VERSION "created by canmatrix"

NS_ :

BS_:

BU_: MD1_ECM ETC NODE_5 BSM_EBS RM_IRCS IC_Multic SGW BCM_NBM VCM NODE_31 ETS NODE_45 FCCU DICO NODE_72 FMReceiver SGW2 VCU ADCU MRGEN DTCO MBMS TPMS AI_CAID ELC ELC_R NODE_F7 BMS3 TUROLLA PCM SRR_Front_Left SRR_Rear_Right SRR_Front_Right SRR_Front SRR_Rear_Left ELFA3_S THERMOKING_M TMU_HP_Rr NODE_B1 NODE_B2 NODE_B3 NODE_B4 NODE_B5 NODE_B6 NODE_B7 NODE_B8 BMS2 NODE_B9 NODE_BA NODE_FC NODE_BB NODE_BC NODE_BE NODE_BD NODE_BF ACU NODE_C0 BMS1 NODE_C1 FCU NODE_C3 NODE_C4 NODE_EC NODE_C5 NODE_C6 NODE_C7 NODE_C8 VCU2 NODE_CA NODE_CB NODE_CD NODE_CE NODE_CF NODE_ED ST_ScanTool MASTER68_STD1 NODE_D1 NODE_F2 NODE_FD NODE_D2 MCSL NODE_EB NODE_D3 NODE_D4 NODE_D5 NODE_D6 VCCU NODE_D8 NODE_D9 NODE_F9 DiagTool NODE_DA NODE_DB NODE_DC NODE_DD NODE_DE NODE_DF NODE_E0 NODE_E1 NODE_E2 NODE_E9 NODE_E3 SAS NODE_FB NODE_F8 NODE_E6 ELFA3 NODE_F THERMOKING_D FMS MULTIC_S MULTIC_2 BMS4 BMS5 BMS6 BMS7 BMS8 BMS9 BMS10 BMS11 NODE_71

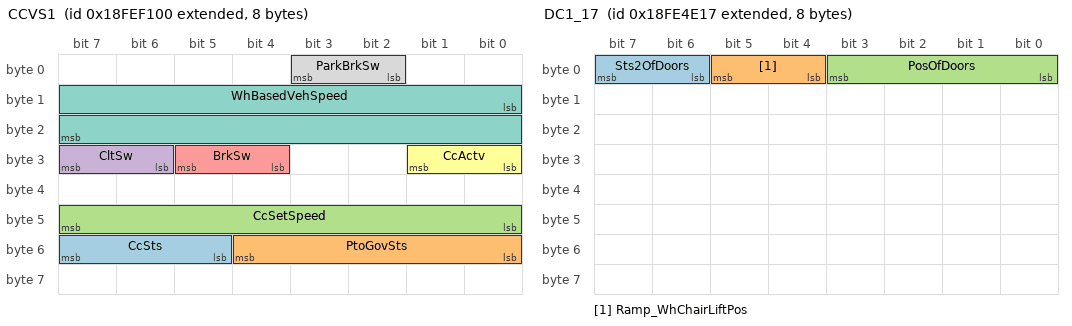
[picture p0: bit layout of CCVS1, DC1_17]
BO_ 2566844672 CCVS1: 8 MD1_ECM
 SG_ CcSts : 53|3@1+ (1,0) [0|7] ""  PCM
 SG_ PtoGovSts : 48|5@1+ (1,0) [0|31] ""  PCM
 SG_ CcSetSpeed : 40|8@1+ (1,0) [0|250] "km/h"  PCM
 SG_ CltSw : 30|2@1+ (1,0) [0|3] ""  PCM
 SG_ BrkSw : 28|2@1+ (1,0) [0|3] ""  PCM
 SG_ CcActv : 24|2@1+ (1,0) [0|3] ""  PCM
 SG_ WhBasedVehSpeed : 8|16@1+ (0.00390625,0) [0|250.996] "km/h"  PCM
 SG_ ParkBrkSw : 2|2@1+ (1,0) [0|3] ""  PCM

BO_ 2566890313 ChargerFaults: 8 FCCU
 SG_ BefLastStopCause : 32|8@1+ (1,0) [0|250] ""  PCM
 SG_ LastStopCause : 24|8@1+ (1,0) [0|250] ""  PCM

BO_ 2566843165 CI_1D: 609 SGW
 SG_ UnitNumPwrUnit : 24|8@1+ (1,0) [0|255] "ASCII"  PCM
 SG_ Sn : 16|8@1+ (1,0) [0|255] "ASCII"  PCM
 SG_ Model : 8|8@1+ (1,0) [0|255] "ASCII"  PCM
 SG_ Make : 0|8@1+ (1,0) [0|255] "ASCII"  PCM

BO_ 2566843230 CI_5E: 609 AI_CAID
 SG_ Model_FEEB5E : 8|8@1+ (1,0) [0|255] "ASCII"  PCM

BO_ 2566865139 CLIM_LTO_STATUS: 8 MBMS
 SG_ CoolSts : 4|4@1+ (1,0) [0|7] ""  PCM

BO_ 2566811659 CVW_0B: 8 BSM_EBS
 SG_ Gcvw : 16|16@1+ (10,0) [0|642550] "kg"  PCM

BO_ 2566802967 DC1_17: 8 IC_Multic
 SG_ Sts2OfDoors : 6|2@1+ (1,0) [0|3] ""  PCM
 SG_ Ramp_WhChairLiftPos : 4|2@1+ (1,0) [0|3] ""  PCM
 SG_ PosOfDoors : 0|4@1+ (1,0) [0|15] ""  PCM

BO_ 2566759703 DC2_17: 8 IC_Multic
 SG_ EnaStsOfDoor10 : 58|2@1+ (1,0) [0|3] ""  PCM
 SG_ OpenStsOfDoor10 : 56|2@1+ (1,0) [0|3] ""  PCM
 SG_ LckStsOfDoor10 : 54|2@1+ (1,0) [0|3] ""  PCM
 SG_ EnaStsOfDoor9 : 52|2@1+ (1,0) [0|3] ""  PCM
 SG_ OpenStsOfDoor9 : 50|2@1+ (1,0) [0|3] ""  PCM
 SG_ LckStsOfDoor9 : 48|2@1+ (1,0) [0|3] ""  PCM
 SG_ EnaStsOfDoor8 : 46|2@1+ (1,0) [0|3] ""  PCM
 SG_ OpenStsOfDoor8 : 44|2@1+ (1,0) [0|3] ""  PCM
 SG_ LckStsOfDoor8 : 42|2@1+ (1,0) [0|3] ""  PCM
 SG_ EnaStsOfDoor7 : 40|2@1+ (1,0) [0|3] ""  PCM
 SG_ OpenStsOfDoor7 : 38|2@1+ (1,0) [0|3] ""  PCM
 SG_ LckStsOfDoor7 : 36|2@1+ (1,0) [0|3] ""  PCM
 SG_ EnaStsOfDoor6 : 34|2@1+ (1,0) [0|3] ""  PCM
 SG_ OpenStsOfDoor6 : 32|2@1+ (1,0) [0|3] ""  PCM
 SG_ LckStsOfDoor6 : 30|2@1+ (1,0) [0|3] ""  PCM
 SG_ EnaStsOfDoor5 : 28|2@1+ (1,0) [0|3] ""  PCM
 SG_ OpenStsOfDoor5 : 26|2@1+ (1,0) [0|3] ""  PCM
 SG_ LckStsOfDoor5 : 24|2@1+ (1,0) [0|3] ""  PCM
 SG_ EnaStsOfDoor4 : 22|2@1+ (1,0) [0|3] ""  PCM
 SG_ OpenStsOfDoor4 : 20|2@1+ (1,0) [0|3] ""  PCM
 SG_ LckStsOfDoor4 : 18|2@1+ (1,0) [0|3] ""  PCM
 SG_ EnaStsOfDoor3 : 16|2@1+ (1,0) [0|3] ""  PCM
 SG_ OpenStsOfDoor3 : 14|2@1+ (1,0) [0|3] ""  PCM
 SG_ LckStsOfDoor3 : 12|2@1+ (1,0) [0|3] ""  PCM
 SG_ EnaStsOfDoor2 : 10|2@1+ (1,0) [0|3] ""  PCM
 SG_ OpenStsOfDoor2 : 8|2@1+ (1,0) [0|3] ""  PCM
 SG_ LckStsOfDoor2 : 6|2@1+ (1,0) [0|3] ""  PCM
 SG_ EnaStsOfDoor1 : 4|2@1+ (1,0) [0|3] ""  PCM
 SG_ OpenStsOfDoor1 : 2|2@1+ (1,0) [0|3] ""  PCM
 SG_ LckStsOfDoor1 : 0|2@1+ (1,0) [0|3] ""  PCM

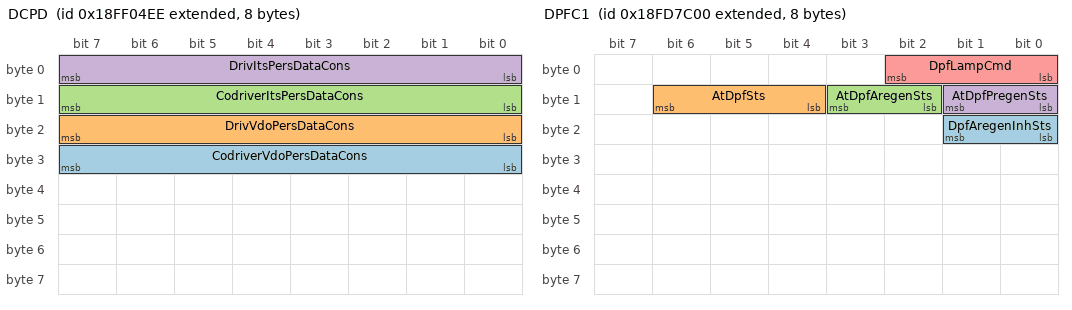
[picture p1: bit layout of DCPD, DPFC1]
BO_ 2566849774 DCPD: 8 DTCO
 SG_ CodriverVdoPersDataCons : 24|8@1+ (1,0) [0|250] ""  PCM
 SG_ DrivVdoPersDataCons : 16|8@1+ (1,0) [0|250] ""  PCM
 SG_ CodriverItsPersDataCons : 8|8@1+ (1,0) [0|250] ""  PCM
 SG_ DrivItsPersDataCons : 0|8@1+ (1,0) [0|250] ""  PCM

BO_ 2566847521 DD1_21: 8 BCM_NBM
 SG_ FuelLev1 : 8|8@1+ (0.4,0) [0|100] "%"  PCM

BO_ 2566810606 DI_EE: 40 DTCO
 SG_ Driv2Id : 8|8@1+ (1,0) [0|255] "ASCII"  PCM
 SG_ Driv1Id : 0|8@1+ (1,0) [0|255] "ASCII"  PCM

BO_ 2566834688 DM01_00: 82 MD1_ECM
 SG_ SpnCm20 : 655|1@1+ (1,0) [0|1] ""  PCM

BO_ 2566834691 DM01_03: 42 ETC
 SG_ SpnCm10 : 335|1@1+ (1,0) [0|1] ""  PCM

BO_ 2566834699 DM01_0B: 42 BSM_EBS
 SG_ SpnCm10_FECA0B : 335|1@1+ (1,0) [0|1] ""  PCM

BO_ 2566834704 DM01_10: 42 RM_IRCS
 SG_ SpnCm10_FECA10 : 335|1@1+ (1,0) [0|1] ""  PCM

BO_ 2566834711 DM01_17: 82 IC_Multic
 SG_ SpnCm20_FECA17 : 655|1@1+ (1,0) [0|1] ""  PCM

BO_ 2566834716 DM01_1C: 42 PCM
 SG_ SpnCm10_FECA1C : 335|1@1+ (1,0) [0|1] "" Vector__XXX

BO_ 2566834717 DM01_1D: 42 SGW
 SG_ SpnCm10_FECA1D : 335|1@1+ (1,0) [0|1] ""  PCM

BO_ 2566834721 DM01_21: 42 BCM_NBM
 SG_ SpnCm10_FECA21 : 335|1@1+ (1,0) [0|1] ""  PCM

BO_ 2566834727 DM01_27: 42 VCM
 SG_ SpnCm10_FECA27 : 335|1@1+ (1,0) [0|1] ""  PCM

BO_ 2566834734 DM01_2E: 42 TUROLLA
 SG_ SpnCm10_FECA2E : 335|1@1+ (1,0) [0|1] ""  PCM

BO_ 2566834735 DM01_2F: 42 ELC
 SG_ SpnCm10_FECA2F : 335|1@1+ (1,0) [0|1] ""  PCM

BO_ 2566834739 DM01_33: 42 TPMS
 SG_ SpnCm10_FECA33 : 335|1@1+ (1,0) [0|1] ""  PCM

BO_ 2566834744 DM01_38: 42 ETS
 SG_ SpnCm10_FECA38 : 335|1@1+ (1,0) [0|1] ""  PCM

BO_ 2566834752 DM01_40: 42 ELC_R
 SG_ SpnCm10_FECA40 : 335|1@1+ (1,0) [0|1] ""  PCM

BO_ 2566834761 DM01_49: 42 FCCU
 SG_ SpnCm10_FECA49 : 335|1@1+ (1,0) [0|1] ""  PCM

BO_ 2566834762 DM01_4A: 42 PCM
 SG_ SpnCm10_FECA4A : 335|1@1+ (1,0) [0|1] "" Vector__XXX

BO_ 2566834778 DM01_5A: 42 DICO
 SG_ SpnCm10_FECA5A : 335|1@1+ (1,0) [0|1] ""  PCM

BO_ 2566834782 DM01_5E: 42 AI_CAID
 SG_ SpnCm10_FECA5E : 335|1@1+ (1,0) [0|1] ""  PCM

BO_ 2566834814 DM01_7E: 42 SGW2
 SG_ SpnCm10_FECA7E : 335|1@1+ (1,0) [0|1] ""  PCM

BO_ 2566834832 DM01_90: 42 SRR_Front_Left
 SG_ SpnCm10_FECA90 : 335|1@1+ (1,0) [0|1] ""  PCM

BO_ 2566834833 DM01_91: 42 SRR_Rear_Right
 SG_ SpnCm10_FECA91 : 335|1@1+ (1,0) [0|1] ""  PCM

BO_ 2566834834 DM01_92: 42 SRR_Front_Right
 SG_ SpnCm10_FECA92 : 335|1@1+ (1,0) [0|1] ""  PCM

BO_ 2566834844 DM01_9C: 42 SRR_Front
 SG_ SpnCm10_FECA9C : 335|1@1+ (1,0) [0|1] ""  PCM

BO_ 2566834846 DM01_9E: 42 ADCU
 SG_ SpnCm10_FECA9E : 335|1@1+ (1,0) [0|1] ""  PCM

BO_ 2566834848 DM01_A0: 42 MRGEN
 SG_ SpnCm10_FECAA0 : 335|1@1+ (1,0) [0|1] ""  PCM

BO_ 2566834920 DM01_E8: 42 SRR_Rear_Left
 SG_ SpnCm10_FECAE8 : 335|1@1+ (1,0) [0|1] ""  PCM

BO_ 2566834926 DM01_EE: 42 DTCO
 SG_ SpnCm10_FECAEE : 335|1@1+ (1,0) [0|1] ""  PCM

BO_ 2566834928 DM01_F0: 42 ELFA3_S
 SG_ SpnCm10_FECAF0 : 335|1@1+ (1,0) [0|1] ""  PCM

BO_ 2566834931 DM01_F3: 42 MBMS
 SG_ SpnCm10_FECAF3 : 335|1@1+ (1,0) [0|1] ""  PCM

BO_ 2566834972 DM02_1C: 42 PCM
 SG_ SpnCm10_FECB1C : 335|1@1+ (1,0) [0|1] "" Vector__XXX

BO_ 2566834973 DM02_1D: 42 SGW
 SG_ SpnCm10_FECB1D : 335|1@1+ (1,0) [0|1] ""  PCM

BO_ 2566835102 DM02_9E: 42 ADCU
 SG_ SpnCm10_FECB9E : 335|1@1+ (1,0) [0|1] ""  PCM

BO_ 2566835485 DM04_1D: 250 SGW
 SG_ HrTotVehDist_10 : 1968|32@1+ (5,0) [0|21055406075] "m"  PCM

BO_ 2566835614 DM04_9E: 250 ADCU
 SG_ HrTotVehDist_10_FECD9E : 1968|32@1+ (5,0) [0|21055406075] "m"  PCM

BO_ 2633943577 DM1_19_P7: 42 THERMOKING_M
 SG_ SpnCm10_FECA19 : 335|1@1+ (1,0) [0|1] ""  PCM

BO_ 2633943610 DM1_3A_P7: 42 TMU_HP_Rr
 SG_ SpnCm10_FECA3A : 335|1@1+ (1,0) [0|1] ""  PCM

BO_ 2633943680 DM1_80_P7: 42 VCU
 SG_ SpnCm10_FECA80 : 335|1@1+ (1,0) [0|1] ""  PCM

BO_ 2566856773 DoorsStat: 8 NODE_45
 SG_ DoorClosTime4 m4 : 32|8@1+ (100,0) [0|20000] "ms"  PCM
 SG_ DoorClosTime3 m3 : 32|8@1+ (100,0) [0|20000] "ms"  PCM
 SG_ DoorClosTime2 m2 : 32|8@1+ (100,0) [0|20000] "ms"  PCM
 SG_ DoorClosTime1 m1 : 32|8@1+ (100,0) [0|20000] "ms"  PCM
 SG_ DoorClosTime0 m0 : 32|8@1+ (100,0) [0|20000] "ms"  PCM
 SG_ DoorCnt4 m4 : 8|24@1+ (1,0) [0|6291455] "Cy"  PCM
 SG_ DoorCnt3 m3 : 8|24@1+ (1,0) [0|6291455] "Cy"  PCM
 SG_ DoorCnt2 m2 : 8|24@1+ (1,0) [0|6291455] "Cy"  PCM
 SG_ DoorCnt1 m1 : 8|24@1+ (1,0) [0|6291455] "Cy"  PCM
 SG_ DoorCnt0 m0 : 8|24@1+ (1,0) [0|6291455] "Cy"  PCM
 SG_ DoorId M : 0|8@1+ (1,0) [0|7] ""  PCM

BO_ 2566749184 DPFC1: 8 MD1_ECM
 SG_ DpfAregenInhSts : 16|2@1+ (1,0) [0|3] ""  PCM
 SG_ AtDpfSts : 12|3@1+ (1,0) [0|7] ""  PCM
 SG_ AtDpfAregenSts : 10|2@1+ (1,0) [0|3] ""  PCM
 SG_ AtDpfPregenSts : 8|2@1+ (1,0) [0|3] ""  PCM
 SG_ DpfLampCmd : 0|3@1+ (1,0) [0|7] ""  PCM

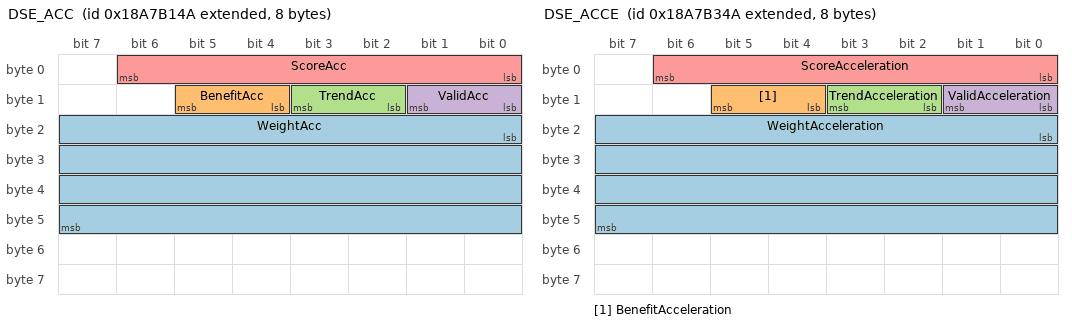
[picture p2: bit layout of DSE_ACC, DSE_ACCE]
BO_ 2561126730 DSE_ACC: 8 PCM
 SG_ WeightAcc : 16|32@1+ (1,-1) [-1|4294967294] ""  NODE_B1
 SG_ BenefitAcc : 12|2@1+ (1,0) [0|3] ""  NODE_B1
 SG_ TrendAcc : 10|2@1+ (1,-1) [-1|2] ""  NODE_B1
 SG_ ValidAcc : 8|2@1+ (1,0) [0|3] ""  NODE_B1
 SG_ ScoreAcc : 0|7@1+ (1,-1) [-1|126] ""  NODE_B1

BO_ 2561126986 DSE_ACC_DBG: 8 PCM
 SG_ EventAcc : 16|2@1+ (1,0) [0|3] ""  NODE_B2
 SG_ EvaluatedSamplesAcc : 0|16@1+ (1,-1) [-1|65534] ""  NODE_B2

BO_ 2561127242 DSE_ACCE: 8 PCM
 SG_ WeightAcceleration : 16|32@1+ (1,-1) [-1|4294967294] ""  NODE_B3
 SG_ BenefitAcceleration : 12|2@1+ (1,0) [0|3] ""  NODE_B3
 SG_ TrendAcceleration : 10|2@1+ (1,-1) [-1|2] ""  NODE_B3
 SG_ ValidAcceleration : 8|2@1+ (1,0) [0|3] ""  NODE_B3
 SG_ ScoreAcceleration : 0|7@1+ (1,-1) [-1|126] ""  NODE_B3

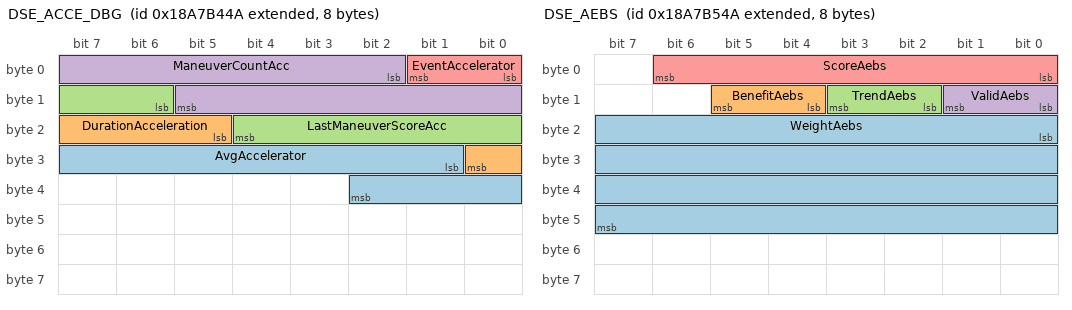
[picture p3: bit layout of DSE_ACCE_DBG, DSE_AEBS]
BO_ 2561127498 DSE_ACCE_DBG: 8 PCM
 SG_ AvgAccelerator : 25|10@1+ (0.1,-1) [-1|101.3] "%"  NODE_B4
 SG_ DurationAcceleration : 21|4@1+ (1,-1) [-1|14] "s"  NODE_B4
 SG_ LastManeuverScoreAcc : 14|7@1+ (1,-1) [-1|126] "Index"  NODE_B4
 SG_ ManeuverCountAcc : 2|12@1+ (1,-1) [-1|4094] "Count"  NODE_B4
 SG_ EventAccelerator : 0|2@1+ (1,0) [0|3] ""  NODE_B4

BO_ 2561127754 DSE_AEBS: 8 PCM
 SG_ WeightAebs : 16|32@1+ (1,-1) [-1|4294967294] ""  NODE_B5
 SG_ BenefitAebs : 12|2@1+ (1,0) [0|3] ""  NODE_B5
 SG_ TrendAebs : 10|2@1+ (1,-1) [-1|2] ""  NODE_B5
 SG_ ValidAebs : 8|2@1+ (1,0) [0|3] ""  NODE_B5
 SG_ ScoreAebs : 0|7@1+ (1,-1) [-1|126] ""  NODE_B5

BO_ 2561128010 DSE_AEBS_DBG: 8 PCM
 SG_ EventAebs : 16|2@1+ (1,0) [0|3] ""  NODE_B6
 SG_ EvaluatedSamplesAebs : 0|16@1+ (1,-1) [-1|65534] ""  NODE_B6

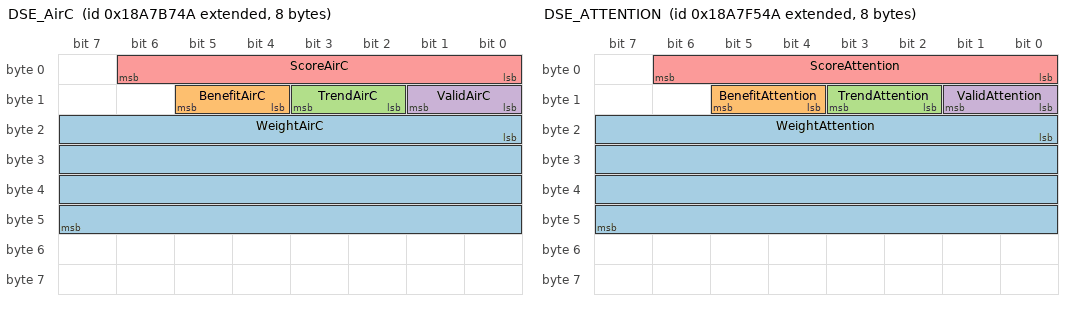
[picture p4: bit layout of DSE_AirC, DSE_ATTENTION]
BO_ 2561128266 DSE_AirC: 8 PCM
 SG_ WeightAirC : 16|32@1+ (1,-1) [-1|4294967294] ""  NODE_B7
 SG_ BenefitAirC : 12|2@1+ (1,0) [0|3] ""  NODE_B7
 SG_ TrendAirC : 10|2@1+ (1,-1) [-1|2] ""  NODE_B7
 SG_ ValidAirC : 8|2@1+ (1,0) [0|3] ""  NODE_B7
 SG_ ScoreAirC : 0|7@1+ (1,-1) [-1|126] ""  NODE_B7

BO_ 2561128522 DSE_AirC_DBG: 8 PCM
 SG_ EvaluatedSamplesAirC : 0|16@1+ (1,-1) [-1|65534] ""  NODE_B8

BO_ 2561144138 DSE_ATTENTION: 8 PCM
 SG_ WeightAttention : 16|32@1+ (1,-1) [-1|4294967294] ""  BMS2
 SG_ BenefitAttention : 12|2@1+ (1,0) [0|3] ""  BMS2
 SG_ TrendAttention : 10|2@1+ (1,-1) [-1|2] ""  BMS2
 SG_ ValidAttention : 8|2@1+ (1,0) [0|3] ""  BMS2
 SG_ ScoreAttention : 0|7@1+ (1,-1) [-1|126] ""  BMS2

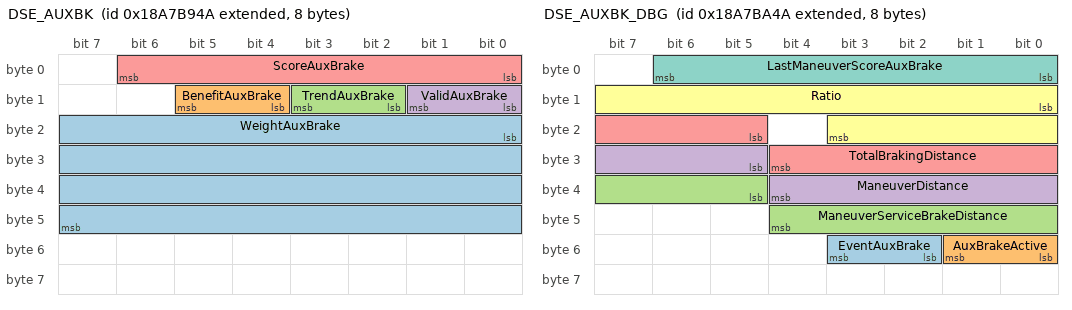
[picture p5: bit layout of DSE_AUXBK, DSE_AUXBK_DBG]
BO_ 2561128778 DSE_AUXBK: 8 PCM
 SG_ WeightAuxBrake : 16|32@1+ (1,-1) [-1|4294967294] ""  NODE_B9
 SG_ BenefitAuxBrake : 12|2@1+ (1,0) [0|3] ""  NODE_B9
 SG_ TrendAuxBrake : 10|2@1+ (1,-1) [-1|2] ""  NODE_B9
 SG_ ValidAuxBrake : 8|2@1+ (1,0) [0|3] ""  NODE_B9
 SG_ ScoreAuxBrake : 0|7@1+ (1,-1) [-1|126] ""  NODE_B9

BO_ 2561129034 DSE_AUXBK_DBG: 8 PCM
 SG_ EventAuxBrake : 50|2@1+ (1,0) [0|3] ""  NODE_BA
 SG_ AuxBrakeActive : 48|2@1+ (1,0) [0|3] ""  NODE_BA
 SG_ ManeuverServiceBrakeDistance : 37|8@1+ (1,0) [0|254] "m"  NODE_BA
 SG_ ManeuverDistance : 29|8@1+ (1,-1) [-1|254] "m"  NODE_BA
 SG_ TotalBrakingDistance : 21|8@1+ (1,-1) [-1|254] "m"  NODE_BA
 SG_ Ratio : 8|12@1+ (0.1,-1) [-1|408.5] ""  NODE_BA
 SG_ LastManeuverScoreAuxBrake : 0|7@1+ (1,-1) [-1|126] "Index"  NODE_BA

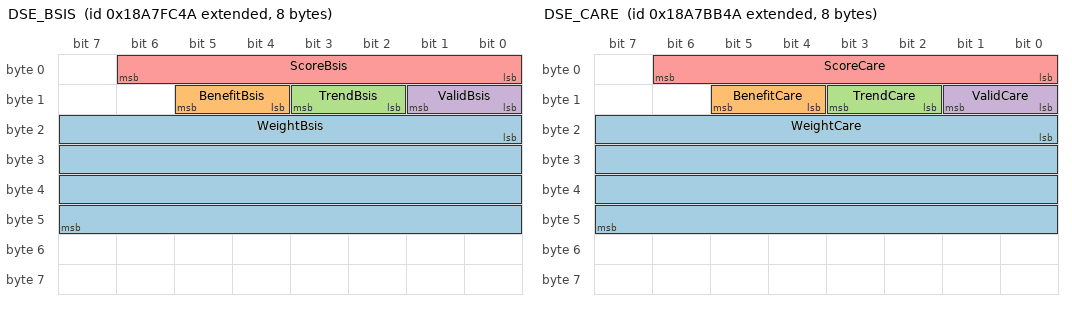
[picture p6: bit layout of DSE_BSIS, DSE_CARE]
BO_ 2561145930 DSE_BSIS: 8 PCM
 SG_ WeightBsis : 16|32@1+ (1,-1) [-1|4294967294] ""  NODE_FC
 SG_ BenefitBsis : 12|2@1+ (1,0) [0|3] ""  NODE_FC
 SG_ TrendBsis : 10|2@1+ (1,-1) [-1|2] ""  NODE_FC
 SG_ ValidBsis : 8|2@1+ (1,0) [0|3] ""  NODE_FC
 SG_ ScoreBsis : 0|7@1+ (1,-1) [-1|126] ""  NODE_FC

BO_ 2561129290 DSE_CARE: 8 PCM
 SG_ WeightCare : 16|32@1+ (1,-1) [-1|4294967294] ""  NODE_BB
 SG_ BenefitCare : 12|2@1+ (1,0) [0|3] ""  NODE_BB
 SG_ TrendCare : 10|2@1+ (1,-1) [-1|2] ""  NODE_BB
 SG_ ValidCare : 8|2@1+ (1,0) [0|3] ""  NODE_BB
 SG_ ScoreCare : 0|7@1+ (1,-1) [-1|126] "Index"  NODE_BB

BO_ 2561129546 DSE_CMD: 8 PCM
 SG_ ResetEcoB : 2|2@1+ (1,0) [0|3] ""  NODE_BC
 SG_ ResetEcoA : 0|2@1+ (1,0) [0|3] ""  NODE_BC

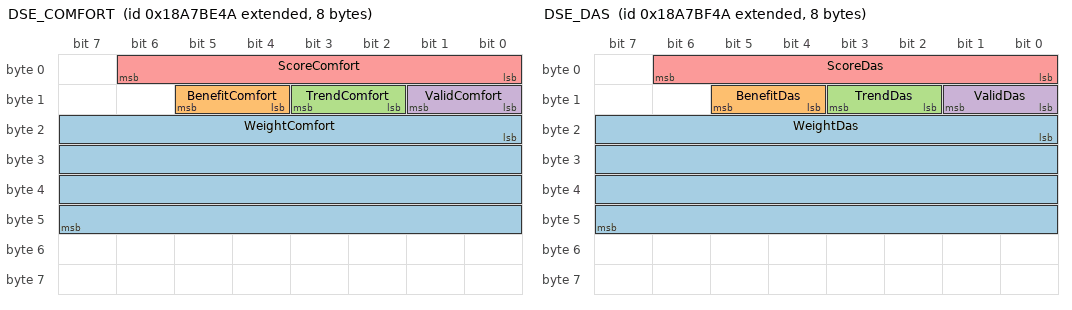
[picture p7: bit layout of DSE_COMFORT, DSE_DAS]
BO_ 2561130058 DSE_COMFORT: 8 PCM
 SG_ WeightComfort : 16|32@1+ (1,-1) [-1|4294967294] ""  NODE_BE
 SG_ BenefitComfort : 12|2@1+ (1,0) [0|3] ""  NODE_BE
 SG_ TrendComfort : 10|2@1+ (1,-1) [-1|2] ""  NODE_BE
 SG_ ValidComfort : 8|2@1+ (1,0) [0|3] ""  NODE_BE
 SG_ ScoreComfort : 0|7@1+ (1,0) [0|100] "%"  NODE_BE

BO_ 2561129802 DSE_CURNT: 8 PCM
 SG_ TimeStampCurrent : 32|32@1+ (1,946684800) [946684800|5241652095] "Date"  NODE_BD
 SG_ OdometerTripCurrent : 0|32@1+ (5,-1) [-1|21474836474] "m"  NODE_BD

BO_ 2561130314 DSE_DAS: 8 PCM
 SG_ WeightDas : 16|32@1+ (1,-1) [-1|4294967294] ""  NODE_BF
 SG_ BenefitDas : 12|2@1+ (1,0) [0|3] ""  NODE_BF
 SG_ TrendDas : 10|2@1+ (1,-1) [-1|2] ""  NODE_BF
 SG_ ValidDas : 8|2@1+ (1,0) [0|3] ""  NODE_BF
 SG_ ScoreDas : 0|7@1+ (1,-1) [-1|126] "Index"  NODE_BF

BO_ 2561140554 DSE_DAS_DBG: 8 PCM
 SG_ EventDas : 16|2@1+ (1,0) [0|3] ""  ACU
 SG_ EvaluatedSamplesDas : 0|16@1+ (1,-1) [-1|65534] ""  ACU

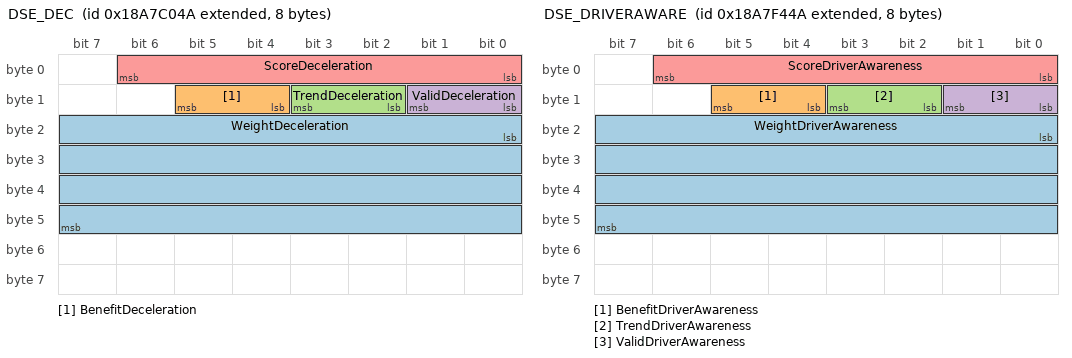
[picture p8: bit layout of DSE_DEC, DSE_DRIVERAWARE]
BO_ 2561130570 DSE_DEC: 8 PCM
 SG_ WeightDeceleration : 16|32@1+ (1,-1) [-1|4294967294] ""  NODE_C0
 SG_ BenefitDeceleration : 12|2@1+ (1,0) [0|3] ""  NODE_C0
 SG_ TrendDeceleration : 10|2@1+ (1,-1) [-1|2] ""  NODE_C0
 SG_ ValidDeceleration : 8|2@1+ (1,0) [0|3] ""  NODE_C0
 SG_ ScoreDeceleration : 0|7@1+ (1,-1) [-1|126] "Index"  NODE_C0

BO_ 2561143882 DSE_DRIVERAWARE: 8 PCM
 SG_ WeightDriverAwareness : 16|32@1+ (1,-1) [-1|4294967294] ""  BMS1
 SG_ BenefitDriverAwareness : 12|2@1+ (1,0) [0|3] ""  BMS1
 SG_ TrendDriverAwareness : 10|2@1+ (1,-1) [-1|2] ""  BMS1
 SG_ ValidDriverAwareness : 8|2@1+ (1,0) [0|3] ""  BMS1
 SG_ ScoreDriverAwareness : 0|7@1+ (1,-1) [-1|126] "Index"  BMS1

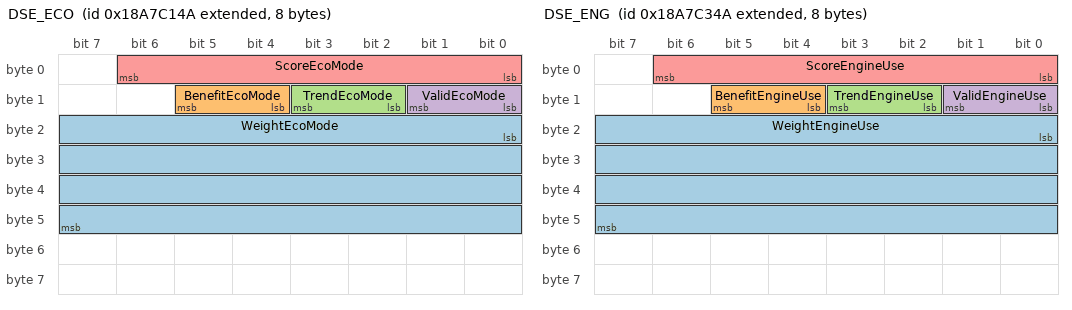
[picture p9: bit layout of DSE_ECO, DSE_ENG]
BO_ 2561130826 DSE_ECO: 8 PCM
 SG_ WeightEcoMode : 16|32@1+ (1,-1) [-1|4294967294] ""  NODE_C1
 SG_ BenefitEcoMode : 12|2@1+ (1,0) [0|3] ""  NODE_C1
 SG_ TrendEcoMode : 10|2@1+ (1,-1) [-1|2] ""  NODE_C1
 SG_ ValidEcoMode : 8|2@1+ (1,0) [0|3] ""  NODE_C1
 SG_ ScoreEcoMode : 0|7@1+ (1,-1) [-1|126] "Index"  NODE_C1

BO_ 2561131082 DSE_ECO_DBG: 8 PCM
 SG_ EvaluatedSamplesEcoMode : 0|16@1+ (1,-1) [-1|65534] ""  FCU

BO_ 2561131338 DSE_ENG: 8 PCM
 SG_ WeightEngineUse : 16|32@1+ (1,-1) [-1|4294967294] ""  NODE_C3
 SG_ BenefitEngineUse : 12|2@1+ (1,0) [0|3] ""  NODE_C3
 SG_ TrendEngineUse : 10|2@1+ (1,-1) [-1|2] ""  NODE_C3
 SG_ ValidEngineUse : 8|2@1+ (1,0) [0|3] ""  NODE_C3
 SG_ ScoreEngineUse : 0|7@1+ (1,-1) [-1|126] "Index"  NODE_C3

BO_ 2561140810 DSE_EVAL: 8 PCM
 SG_ EvaluatedSamplesTrip : 32|32@1+ (1,-1) [-1|4294967294] ""  SRR_Rear_Left
 SG_ EvaluatedMetersTrip : 0|32@1+ (1,-1) [-1|4294967294] "m"  SRR_Rear_Left

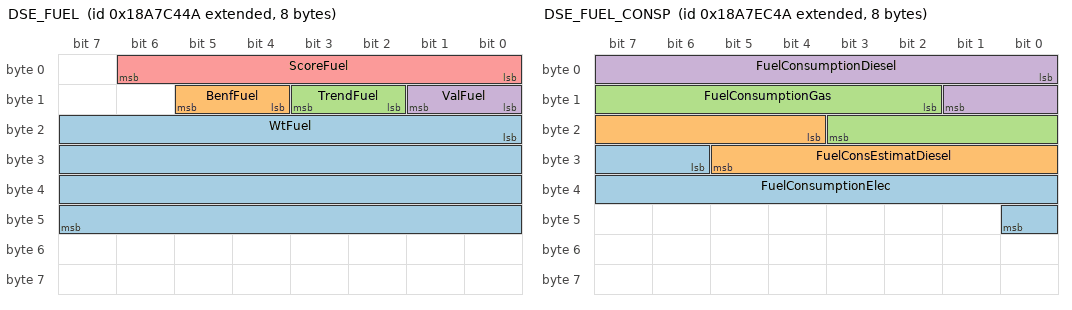
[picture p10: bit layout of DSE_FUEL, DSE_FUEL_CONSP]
BO_ 2561131594 DSE_FUEL: 8 PCM
 SG_ WtFuel : 16|32@1+ (1,-1) [-1|4294967294] ""  NODE_C4
 SG_ BenfFuel : 12|2@1+ (1,0) [0|3] ""  NODE_C4
 SG_ TrendFuel : 10|2@1+ (1,-1) [-1|2] ""  NODE_C4
 SG_ ValFuel : 8|2@1+ (1,0) [0|3] ""  NODE_C4
 SG_ ScoreFuel : 0|7@1+ (1,-1) [-1|100] "%"  NODE_C4

BO_ 2561141834 DSE_FUEL_CONSP: 8 PCM
 SG_ FuelConsumptionElec : 30|11@1+ (0.1,-1) [-1|203.7] "kWh/100km"  NODE_EC
 SG_ FuelConsEstimatDiesel : 20|10@1+ (0.1,-1) [-1|101.3] "L/100km"  NODE_EC
 SG_ FuelConsumptionGas : 10|10@1+ (0.1,-1) [-1|101.3] "Kg/100km"  NODE_EC
 SG_ FuelConsumptionDiesel : 0|10@1+ (0.1,-1) [-1|101.3] "L/100km"  NODE_EC

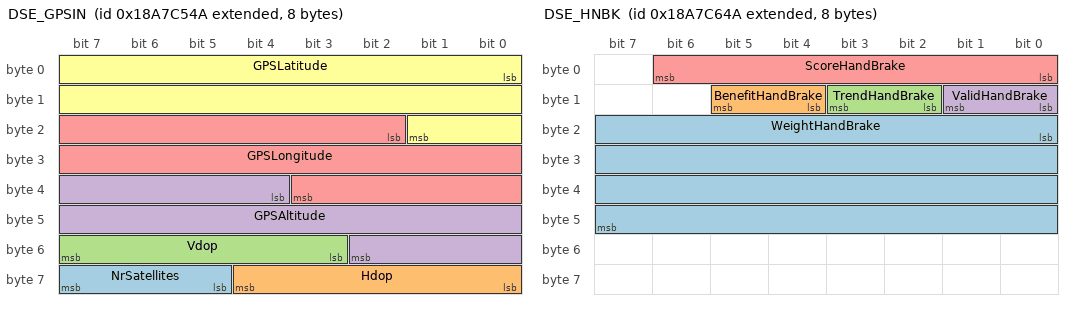
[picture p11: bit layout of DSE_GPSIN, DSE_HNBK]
BO_ 2561131850 DSE_GPSIN: 8 PCM
 SG_ NrSatellites : 61|3@1+ (1,0) [0|7] ""  NODE_C5
 SG_ Hdop : 56|5@1+ (1,0) [0|25] ""  NODE_C5
 SG_ Vdop : 51|5@1+ (1,0) [0|25] ""  NODE_C5
 SG_ GPSAltitude : 36|15@1+ (0.2,-500) [-500|5797.4] ""  NODE_C5
 SG_ GPSLongitude : 18|18@1- (0.0015,0) [-196.608|196.6065] ""  NODE_C5
 SG_ GPSLatitude : 0|18@1- (0.001,0) [-131.072|131.071] ""  NODE_C5

BO_ 2561132106 DSE_HNBK: 8 PCM
 SG_ WeightHandBrake : 16|32@1+ (1,-1) [-1|4294967294] ""  NODE_C6
 SG_ BenefitHandBrake : 12|2@1+ (1,0) [0|3] ""  NODE_C6
 SG_ TrendHandBrake : 10|2@1+ (1,-1) [-1|2] ""  NODE_C6
 SG_ ValidHandBrake : 8|2@1+ (1,0) [0|3] ""  NODE_C6
 SG_ ScoreHandBrake : 0|7@1+ (1,-1) [-1|126] "Index"  NODE_C6

BO_ 2561132362 DSE_HNBK_DBG: 8 PCM
 SG_ EventHandBrake : 16|2@1+ (1,0) [0|3] ""  NODE_C7
 SG_ NumEventsHandBrake : 0|16@1+ (1,-1) [-1|65534] ""  NODE_C7

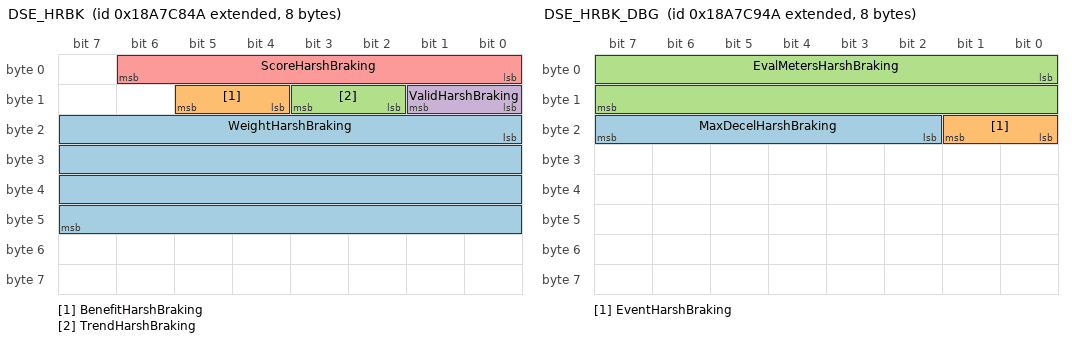
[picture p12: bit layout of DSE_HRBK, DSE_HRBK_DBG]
BO_ 2561132618 DSE_HRBK: 8 PCM
 SG_ WeightHarshBraking : 16|32@1+ (1,-1) [-1|4294967294] ""  NODE_C8
 SG_ BenefitHarshBraking : 12|2@1+ (1,0) [0|3] ""  NODE_C8
 SG_ TrendHarshBraking : 10|2@1+ (1,-1) [-1|2] ""  NODE_C8
 SG_ ValidHarshBraking : 8|2@1+ (1,0) [0|3] ""  NODE_C8
 SG_ ScoreHarshBraking : 0|7@1+ (1,-1) [-1|126] "Index"  NODE_C8

BO_ 2561132874 DSE_HRBK_DBG: 8 PCM
 SG_ MaxDecelHarshBraking : 18|6@1+ (1,0) [0|63] "kmh/s"  VCU2
 SG_ EventHarshBraking : 16|2@1+ (1,0) [0|3] ""  VCU2
 SG_ EvalMetersHarshBraking : 0|16@1+ (1,-1) [-1|65534] "m"  VCU2

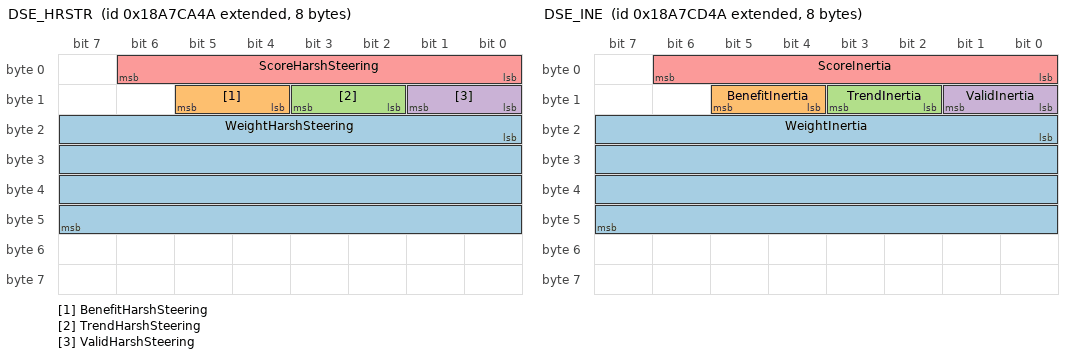
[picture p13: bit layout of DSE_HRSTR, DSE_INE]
BO_ 2561133130 DSE_HRSTR: 8 PCM
 SG_ WeightHarshSteering : 16|32@1+ (1,-1) [-1|4294967294] ""  NODE_CA
 SG_ BenefitHarshSteering : 12|2@1+ (1,0) [0|3] ""  NODE_CA
 SG_ TrendHarshSteering : 10|2@1+ (1,-1) [-1|2] ""  NODE_CA
 SG_ ValidHarshSteering : 8|2@1+ (1,0) [0|3] ""  NODE_CA
 SG_ ScoreHarshSteering : 0|7@1+ (1,-1) [-1|126] "Index"  NODE_CA

BO_ 2561133386 DSE_HRSTR_DBG: 8 PCM
 SG_ EventHarshSteering : 16|2@1+ (1,0) [0|3] ""  NODE_CB
 SG_ EvalMetersHarshSteering : 0|16@1+ (1,-1) [-1|65534] "m"  NODE_CB

BO_ 2561133898 DSE_INE: 8 PCM
 SG_ WeightInertia : 16|32@1+ (1,-1) [-1|4294967294] ""  NODE_CD
 SG_ BenefitInertia : 12|2@1+ (1,0) [0|3] ""  NODE_CD
 SG_ TrendInertia : 10|2@1+ (1,-1) [-1|2] ""  NODE_CD
 SG_ ValidInertia : 8|2@1+ (1,0) [0|3] ""  NODE_CD
 SG_ ScoreInertia : 0|7@1+ (1,-1) [-1|126] "Index"  NODE_CD

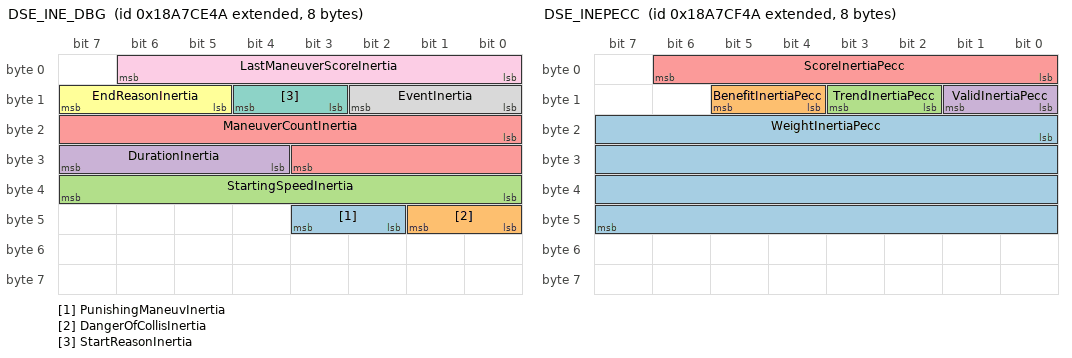
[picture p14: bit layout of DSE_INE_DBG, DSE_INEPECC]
BO_ 2561134154 DSE_INE_DBG: 8 PCM
 SG_ PunishingManeuvInertia : 42|2@1+ (1,0) [0|3] ""  NODE_CE
 SG_ DangerOfCollisInertia : 40|2@1+ (1,0) [0|3] ""  NODE_CE
 SG_ StartingSpeedInertia : 32|8@1+ (0.5,0) [0|125] "km/h"  NODE_CE
 SG_ DurationInertia : 28|4@1+ (1,-1) [-1|14] "s"  NODE_CE
 SG_ ManeuverCountInertia : 16|12@1+ (1,-1) [-1|4094] "Count"  NODE_CE
 SG_ EndReasonInertia : 13|3@1+ (1,0) [0|7] ""  NODE_CE
 SG_ StartReasonInertia : 11|2@1+ (1,0) [0|3] ""  NODE_CE
 SG_ EventInertia : 8|3@1+ (1,0) [0|7] ""  NODE_CE
 SG_ LastManeuverScoreInertia : 0|7@1+ (1,-1) [-1|126] "Index"  NODE_CE

BO_ 2561134410 DSE_INEPECC: 8 PCM
 SG_ WeightInertiaPecc : 16|32@1+ (1,-1) [-1|4294967294] ""  NODE_CF
 SG_ BenefitInertiaPecc : 12|2@1+ (1,0) [0|3] ""  NODE_CF
 SG_ TrendInertiaPecc : 10|2@1+ (1,-1) [-1|2] ""  NODE_CF
 SG_ ValidInertiaPecc : 8|2@1+ (1,0) [0|3] ""  NODE_CF
 SG_ ScoreInertiaPecc : 0|7@1+ (1,-1) [-1|126] "Index"  NODE_CF

CM_ BO_ 2566844672 "- ECU Sender (Tx) on VCM4 if Thermal. VCU or VMU on Siemens elec veh.
-  Only on ELFA2 250K, ELFA3 250K, ELFA2 500K.
-  Only on ELFA3 500K: copy of the message read with SA=0x21 on CAN vehicle. SA=0x00 maintained for PCM and IPM.
-  Sent on VDB for bus (TBC with ADCU requirement).
- VS2.B.SGW2..23..VDB: Used in freeze frames parameters.";
CM_ SG_ 2566844672 PtoGovSts "- To be confirmed if used on elec vehicles. Tx on VCU/VMU to be confirmed.";
CM_ SG_ 2566844672 WhBasedVehSpeed "- SAE J1939/73 Freeze Frame parameter";
CM_ BO_ 2566890313 "- Specific to Siemens Full Elec vehicles. Tx by FCCU, or by VCU in case VC-VCCU. 3 bytes if sent by the FCCU, 8 bytes if sent by the supervisor in case VC-VCCU.";
CM_ SG_ 2566890313 BefLastStopCause "- Diag info end of charge cause (n-1). (case VC-VCCU only)";
CM_ SG_ 2566890313 LastStopCause "- Diag info end of charge cause (n). (case VC-VCCU only)";
CM_ BO_ 2566843165 "- Delimiter (“*”) required after each parameter, even if not used
-  Multipacket message handled by SAE Transport Protocol (J1939/21, par 5.10, Multipacket Broadcast with TP.CM/BAM, TP.DT)
-  Transport Protocol with Control Flow  (RTS, CTS, EndOfMsgAck, Conn_Abort) shall be also supported by the receiver if the multipacket message has been solicited by a Destination Specific Request
-  Variable Message Length, maximum value used for dbc generation";
CM_ SG_ 2566843165 UnitNumPwrUnit "- 15+1 characters maximum
-  Optional, delimiter only if not supported
-  Variable signal length, 8 bits used for dbc generation only";
CM_ SG_ 2566843165 Sn "- 10+1 characters maximum. Manufacturer assigned (CNHI Std. 18-2253)
-  Optional (CNHI Std. 18-2253), delimiter only if not supported
-  Variable signal length, 8 bits used for dbc generation only";
CM_ SG_ 2566843165 Model "- 15+1 characters maximum. Manufacturer assigned Component/ECU Model or P/N(CNHI Std. 18-2253)
-  Variable signal length, 8 bits used for dbc generation only";
CM_ SG_ 2566843165 Make "- Variable signal length, 8 bits used for dbc generation only";
CM_ BO_ 2566843230 "- Delimiter (“*”) required after each parameter, even if not used
-  Multipacket message handled by SAE Transport Protocol (J1939/21, par 5.10, Multipacket Broadcast with TP.CM/BAM, TP.DT)
-  Transport Protocol with Control Flow  (RTS, CTS, EndOfMsgAck, Conn_Abort) shall be also supported by the receiver if the multipacket message has been solicited by a Destination Specific Request
-  Variable Message Length, maximum value used for dbc generation";
CM_ BO_ 2566865139 "- Clim_LTO_Sts (Status of the Clim System of the LTO Batteries) / CLIM_BATT_MANGEMENT.
-  Rate transmision 5000 ms (Value transmitted) / 1000 ms (received for HeatPump).
-  Sent by the MBMS in case of batteries FORSEE (only PULSE battery).
-  Sent by the supervisor (VCU/VMU) in case of batteries Microvast.";
CM_ BO_ 2566811659 "- Message activated only for vehicles with AG ZF Ecolife 2. Message ICE only.
-  SAE Trans.Rate=OnRequest.
- EBC.ZF.BSM..27..VDB: Transmission: 1000 ms";
CM_ SG_ 2566811659 Gcvw "- FF00 to FFFF = not available";
CM_ BO_ 2566802967 "- OVG.Mtx.FMS.4.24.Generic.FMSi: FMS Optional. Update: filled in blue (differed in according with CW/UW VDB CAN files).";
CM_ BO_ 2566759703 "- OVG.Mtx.FMS.4.24.Generic.FMSi: FMS Optional. Update: filled in blue (differed in according with CW/UW VDB CAN files).";
CM_ SG_ 2566759703 EnaStsOfDoor10 "- CUC.C.PCM..3..TELEM: Not used on bus application.";
CM_ SG_ 2566759703 OpenStsOfDoor10 "- CUC.C.PCM..3..TELEM: Not used on bus application.";
CM_ SG_ 2566759703 LckStsOfDoor10 "- CUC.C.PCM..3..TELEM: Not used on bus application.";
CM_ SG_ 2566759703 EnaStsOfDoor9 "- CUC.C.PCM..3..TELEM: Not used on bus application.";
CM_ SG_ 2566759703 OpenStsOfDoor9 "- CUC.C.PCM..3..TELEM: Not used on bus application.";
CM_ SG_ 2566759703 LckStsOfDoor9 "- CUC.C.PCM..3..TELEM: Not used on bus application.";
CM_ BO_ 2566849774 "- Update filled in acc with DTCO4.1 (New file). To be confirmed.";
CM_ BO_ 2566847521 "- MC.W.VCM.4.24..VDB: direct routing to DD1_27";
CM_ BO_ 2566810606 "- * Only if the vehicle is equiped with a tachograph.
-  Multipacket message handled by SAE Transport Protocol (J1939/21, par 5.10, Multipacket Broadcast with TP.CM/BAM, TP.DT)
-  Single packet version. in response of FMS requests every 10s (RQST_25_EE).
-  Variable Message Length, maximum value used for dbc generation";
CM_ SG_ 2566810606 Driv1Id "- Only if no driver card is present, only the two delimiters  *  have to be sent. Then, fill with FF. ASCII Example: DI = 2A 2A FF FF FF FF FF FF, 2A [hex] =  *  [ASCII]";
CM_ BO_ 2566834688 "- If Gaz: Message Length: Up to 42
-  Multipacket message handled by SAE Transport Protocol (J1939/21, par 5.10, Multipacket Broadcast with TP.CM/BAM, TP.DT)
-  Variable Message Length, maximum value used for dbc generation.";
CM_ SG_ 2566834688 SpnCm20 "- Always 0b";
CM_ BO_ 2566834691 "- Multipacket message handled by SAE Transport Protocol (J1939/21, par 5.10, Multipacket Broadcast with TP.CM/BAM, TP.DT)
-  Variable Message Length, maximum value used for dbc generation";
CM_ SG_ 2566834691 SpnCm10 "- Always 0b";
CM_ BO_ 2566834699 "- Multipacket message handled by SAE Transport Protocol (J1939/21, par 5.10, Multipacket Broadcast with TP.CM/BAM, TP.DT)
-  Variable Message Length, maximum value used for dbc generation";
CM_ SG_ 2566834699 SpnCm10_FECA0B "- Always 0b";
CM_ BO_ 2566834711 "- Multipacket message handled by SAE Transport Protocol (J1939/21, par 5.10, Multipacket Broadcast with TP.CM/BAM, TP.DT)
-  Variable Message Length, maximum value used for dbc generation";
CM_ SG_ 2566834711 SpnCm20_FECA17 "- Always 0b";
CM_ BO_ 2566834716 "- Multipacket message handled by SAE Transport Protocol (J1939/21, par 5.10, Multipacket Broadcast with TP.CM/BAM, TP.DT)
-  Transport Protocol Packets (TP.CM, TP.DT) Priority=7
-  Variable Message Length, maximum value used for dbc generation";
CM_ SG_ 2566834716 SpnCm10_FECA1C "- Always 0b";
CM_ BO_ 2566834717 "- Multipacket message handled by SAE Transport Protocol (J1939/21, par 5.10, Multipacket Broadcast with TP.CM/BAM, TP.DT)
-  Variable Message Length, maximum value used for dbc generation";
CM_ SG_ 2566834717 SpnCm10_FECA1D "- Always 0b";
CM_ BO_ 2566834721 "- Multipacket message handled by SAE Transport Protocol (J1939/21, par 5.10, Multipacket Broadcast with TP.CM/BAM, TP.DT)
-  Variable Message Length, maximum value used for dbc generation";
CM_ SG_ 2566834721 SpnCm10_FECA21 "- Always 0b";
CM_ BO_ 2566834727 "- DM1_BMS. Multipacket message handled by SAE Transport Protocol (J1939/21, par 5.10, Multipacket Broadcast with TP.CM/BAM, TP.DT)
-  Variable Message Length, maximum value used for dbc generation.";
CM_ SG_ 2566834727 SpnCm10_FECA27 "- Always 0b";
CM_ BO_ 2566834734 "- Full elec only.
-  Multipacket message handled by SAE Transport Protocol (J1939/21, par 5.10, Multipacket Broadcast with TP.CM/BAM, TP.DT)
-  Variable Message Length, maximum value used for dbc generation.";
CM_ BO_ 2566834735 "- Multipacket message handled by SAE Transport Protocol (J1939/21, par 5.10, Multipacket Broadcast with TP.CM/BAM, TP.DT)
-  Variable Message Length, maximum value used for dbc generation";
CM_ SG_ 2566834735 SpnCm10_FECA2F "- Always 0b";
CM_ BO_ 2566834739 "- Multipacket message handled by SAE Transport Protocol (J1939/21, par 5.10, Multipacket Broadcast with TP.CM/BAM, TP.DT)
-  Variable Message Length, maximum value used for dbc generation";
CM_ SG_ 2566834739 SpnCm10_FECA33 "- Always 0b";
CM_ BO_ 2566834744 "- CW Diesel only.
-  Multipacket message handled by SAE Transport Protocol (J1939/21, par 5.10, Multipacket Broadcast with TP.CM/BAM, TP.DT)
-  Transmission Rate can be 1000 [ms].
-  Variable Message Length, maximum value used for dbc generation.";
CM_ SG_ 2566834744 SpnCm10_FECA38 "- Always 0b";
CM_ BO_ 2566834752 "- Multipacket message handled by SAE Transport Protocol (J1939/21, par 5.10, Multipacket Broadcast with TP.CM/BAM, TP.DT)
-  Variable Message Length, maximum value used for dbc generation
- SSC2.KB.ASM..24..VDB: For Rear ELC.";
CM_ SG_ 2566834752 SpnCm10_FECA40 "- Always 0b";
CM_ BO_ 2566834761 "- Full elec only.
-  Multipacket message handled by SAE Transport Protocol (J1939/21, par 5.10, Multipacket Broadcast with TP.CM/BAM, TP.DT)
-  Variable Message Length, maximum value used for dbc generation";
CM_ SG_ 2566834761 SpnCm10_FECA49 "- Always 0b";
CM_ BO_ 2566834778 "- Reading of the DM1 of the DICO, and copying on the VCB (for display of traction chain fault and fleet management system or predictive maintenance).
-  Specific to Siemens Full Elec vehicles.
-  Timeout (ms): 3000 ms";
CM_ BO_ 2566834814 "- Multipacket message handled by SAE Transport Protocol (J1939/21, par 5.10, Multipacket Broadcast with TP.CM/BAM, TP.DT)
-  Variable Message Length, maximum value used for dbc generation";
CM_ SG_ 2566834814 SpnCm10_FECA7E "- Always 0b";
CM_ BO_ 2566834832 "- SA=0x90. ECU Sender is SRR Left Master (CAN RADAR)";
CM_ BO_ 2566834833 "- SA=0x91. ECU Sender is SRR Right Slave (CAN RADAR)";
CM_ BO_ 2566834834 "- SA=0x92. ECU Sender is SRR Right Master (CAN RADAR)";
CM_ BO_ 2566834844 "- SA=0x9C. ECU Sender is SRR Front Master (CAN RADAR)";
CM_ BO_ 2566834848 "- Multipacket message handled by SAE Transport Protocol (J1939/21, par 5.10, Multipacket Broadcast with TP.CM/BAM, TP.DT)
-  SA=0xA0. ECU Sender is MRGen21 (CAN RADAR). CW Class III only.
-  Variable Message Length, maximum value used for dbc generation";
CM_ SG_ 2566834848 SpnCm10_FECAA0 "- Always 0b";
CM_ BO_ 2566834920 "- SA=0xE8. ECU Sender is SRR Left Slave (CAN RADAR)";
CM_ BO_ 2566834928 "- 18m Gx BEV only
-  Multipacket message DM1 Slave";
CM_ SG_ 2566834928 SpnCm10_FECAF0 "- Always 0b";
CM_ BO_ 2566834931 "- Multipacket message
- BPM.Fo.MBMS....VDB: MBMS Transmission rate: 1000ms for DM1.
- BPM.M.MBMS....VDB: MBMS Transmission rate: 1000ms for DM1.";
CM_ SG_ 2566834931 SpnCm10_FECAF3 "- Always 0b";
CM_ BO_ 2566834972 "- DM02 eHorizon: eHorizon integrated in PCM3 ECU.
-  Multipacket message handled by SAE Transport Protocol (J1939/21, par 5.10, Multipacket Broadcast with TP.CM/BAM, TP.DT)";
CM_ SG_ 2566834972 SpnCm10_FECB1C "- Always 0b";
CM_ BO_ 2566834973 "- Multipacket message handled by SAE Transport Protocol (J1939/21, par 5.10, Multipacket Broadcast with TP.CM/BAM, TP.DT)
-  Transport Protocol with Control Flow  (RTS, CTS, EndOfMsgAck, Conn_Abort) shall be also supported by the receiver if the multipacket message has been solicited by a Destination Specific Request
-  Variable Message Length, maximum value used for dbc generation";
CM_ SG_ 2566834973 SpnCm10_FECB1D "- Always 0b";
CM_ BO_ 2566835102 "- Multipacket message handled by SAE Transport Protocol (J1939/21, par 5.10, Multipacket Broadcast with TP.CM/BAM, TP.DT)
-  Transport Protocol with Control Flow  (RTS, CTS, EndOfMsgAck, Conn_Abort) shall be also supported by the receiver if the multipacket message has been solicited by a Destination Specific Request
-  Variable Message Length, maximum value used for dbc generation";
CM_ SG_ 2566835102 SpnCm10_FECB9E "- Always 0b";
CM_ BO_ 2566835485 "- Freeze Parameters taken at last fault occurrence
-  Multipacket message handled by SAE Transport Protocol (J1939/21, par 5.10, Multipacket Broadcast with TP.CM/BAM, TP.DT)
-  Variable Message Length, maximum value used for dbc generation";
CM_ SG_ 2566835485 HrTotVehDist_10 "- “Manufacturer Specified Information” as per CNHi 18-2253";
CM_ BO_ 2566835614 "- Freeze Parameters taken at last fault occurrence
-  Multipacket message handled by SAE Transport Protocol (J1939/21, par 5.10, Multipacket Broadcast with TP.CM/BAM, TP.DT)
-  Variable Message Length, maximum value used for dbc generation";
CM_ BO_ 2633943577 "- Multipacket message handled by SAE Transport Protocol (J1939/21, par 5.10, Multipacket Broadcast with TP.CM/BAM, TP.DT)
-  Period: 1000ms
-  Variable Message Length, maximum value used for dbc generation.";
CM_ SG_ 2633943577 SpnCm10_FECA19 "- Always 0b";
CM_ BO_ 2633943610 "- Multipacket message handled by SAE Transport Protocol (J1939/21, par 5.10, Multipacket Broadcast with TP.CM/BAM, TP.DT)
-  Period: 1000ms
-  Variable Message Length, maximum value used for dbc generation.";
CM_ SG_ 2633943610 SpnCm10_FECA3A "- Always 0b";
CM_ BO_ 2633943680 "- Multipacket message handled by SAE Transport Protocol (J1939/21, par 5.10, Multipacket Broadcast with TP.CM/BAM, TP.DT)
-  Siemens Full Elec only.
-  Variable Message Length, maximum value used for dbc generation";
CM_ SG_ 2633943680 SpnCm10_FECA80 "- Always 0b";
CM_ BO_ 2566856773 "- DoorsInfo=DoorsStat
-  Predisposal";
CM_ BO_ 2566749184 "- Engine Diesel only.";
CM_ BO_ 2561126730 "- DSE Functionnality. Message sent for debugging on the CAN Telem";
CM_ BO_ 2561126986 "- DSE Functionnality. Message sent for debugging on the CAN Telem";
CM_ BO_ 2561127242 "- DSE Functionnality. Message sent for debugging on the CAN Telem";
CM_ BO_ 2561127498 "- DSE Functionnality. Message sent for debugging on the CAN Telem";
CM_ BO_ 2561127754 "- DSE Functionnality. Message sent for debugging on the CAN Telem";
CM_ BO_ 2561128010 "- DSE Functionnality. Message sent for debugging on the CAN Telem";
CM_ BO_ 2561128266 "- DSE Functionnality. Message sent for debugging on the CAN Telem";
CM_ BO_ 2561128522 "- DSE Functionnality. Message sent for debugging on the CAN Telem";
CM_ BO_ 2561144138 "- DSE Functionnality. Message sent for debugging on the CAN Telem";
CM_ BO_ 2561128778 "- DSE Functionnality. Message sent for debugging on the CAN Telem";
CM_ BO_ 2561129034 "- DSE Functionnality. Message sent for debugging on the CAN Telem";
CM_ BO_ 2561145930 "- DSE Functionnality. Message sent for debugging on the CAN Telem";
CM_ BO_ 2561129290 "- DSE Functionnality. Message sent for debugging on the CAN Telem";
CM_ BO_ 2561129546 "- DSE Functionnality. Message sent for debugging on the CAN Telem";
CM_ BO_ 2561130058 "- DSE Functionnality. Message sent for debugging on the CAN Telem";
CM_ BO_ 2561129802 "- DSE Functionnality. Message sent for debugging on the CAN Telem";
CM_ BO_ 2561130314 "- DSE Functionnality. Message sent for debugging on the CAN Telem";
CM_ BO_ 2561140554 "- DSE Functionnality. Message sent for debugging on the CAN Telem";
CM_ BO_ 2561130570 "- DSE Functionnality. Message sent for debugging on the CAN Telem";
CM_ BO_ 2561143882 "- DSE Functionnality. Message sent for debugging on the CAN Telem";
CM_ BO_ 2561130826 "- DSE Functionnality. Message sent for debugging on the CAN Telem";
CM_ BO_ 2561131082 "- DSE Functionnality. Message sent for debugging on the CAN Telem";
CM_ BO_ 2561131338 "- DSE Functionnality. Message sent for debugging on the CAN Telem";
CM_ BO_ 2561140810 "- DSE Functionnality. Message sent for debugging on the CAN Telem";
CM_ BO_ 2561131594 "- Fuel score is the value interpreated by the cluster's econometer.";
CM_ SG_ 2561131594 ScoreFuel "- Predisposal. Used for Econometer value provided by PCM on IC.
-  Values outside the slot are considered out of range.";
CM_ BO_ 2561141834 "- DSE Functionnality. Message sent for debugging on the CAN Telem";
CM_ BO_ 2561131850 "- DSE Functionnality. Message sent for debugging on the CAN Telem";
CM_ BO_ 2561132106 "- DSE Functionnality. Message sent for debugging on the CAN Telem";
CM_ BO_ 2561132362 "- DSE Functionnality. Message sent for debugging on the CAN Telem";
CM_ BO_ 2561132618 "- DSE Functionnality. Message sent for debugging on the CAN Telem";
CM_ BO_ 2561132874 "- DSE Functionnality. Message sent for debugging on the CAN Telem";
CM_ BO_ 2561133130 "- DSE Functionnality. Message sent for debugging on the CAN Telem";
CM_ BO_ 2561133386 "- DSE Functionnality. Message sent for debugging on the CAN Telem";
CM_ BO_ 2561133898 "- DSE Functionnality. Message sent for debugging on the CAN Telem";
CM_ BO_ 2561134154 "- DSE Functionnality. Message sent for debugging on the CAN Telem";
CM_ BO_ 2561134410 "- DSE Functionnality. Message sent for debugging on the CAN Telem";
BA_DEF_ BO_  "CI_MsgDefinition" STRING ;
BA_DEF_ BO_  "CI_MsgId" INT 0 2147483647;
BA_DEF_ BO_  "CI_MsgName" STRING ;
BA_DEF_ BO_  "GenMsgCycleTime" INT 0 3600000;
BA_DEF_ BO_  "GenMsgCycleTimeFast" INT 0 3600000;
BA_DEF_ BO_  "GenMsgDelayTime" INT 0 3600000;
BA_DEF_ BO_  "GenMsgILSupport" ENUM  "No","Yes";
BA_DEF_ BO_  "GenMsgNrOfRepetition" INT 0 1000000;
BA_DEF_ BO_  "GenMsgRequestable" INT 0 1;
BA_DEF_ BO_  "GenMsgSendType" ENUM  "cyclic","NotUsed","NotUsed","NotUsed","NotUsed","NotUsed","NotUsed","IfActive","noMsgSendType";
BA_DEF_ BO_  "GenMsgStartDelayTime" INT 0 100000;
BA_DEF_ BO_  "TpJ1939VarDlc" ENUM  "No","Yes";
BA_DEF_ BO_  "VFrameFormat" ENUM  "StandardCAN","ExtendedCAN","reserved","J1939PG";
BA_DEF_ SG_  "CI_ParId" STRING ;
BA_DEF_ SG_  "CI_SigId" INT 0 2147483647;
BA_DEF_ SG_  "CI_SigName" STRING ;
BA_DEF_ SG_  "GenSigEVName" STRING ;
BA_DEF_ SG_  "GenSigILSupport" ENUM  "No","Yes";
BA_DEF_ SG_  "GenSigInactiveValue" INT 0 2147483647;
BA_DEF_ SG_  "GenSigSendType" ENUM  "Cyclic","OnWrite","OnWriteWithRepetition","OnChange","OnChangeWithRepetition","IfActive","IfActiveWithRepetition","NoSigSendType";
BA_DEF_ SG_  "GenSigStartValue" INT 0 2147483647;
BA_DEF_ SG_  "GenSigTimeoutTime_ACM_CANAIR" INT 0 3600000;
BA_DEF_ SG_  "GenSigTimeoutTime_ACU" INT 0 3600000;
BA_DEF_ SG_  "GenSigTimeoutTime_ADCU" INT 0 3600000;
BA_DEF_ SG_  "GenSigTimeoutTime_AI_CAID" INT 0 3600000;
BA_DEF_ SG_  "GenSigTimeoutTime_ASM_ELC5_Fr" INT 0 3600000;
BA_DEF_ SG_  "GenSigTimeoutTime_AVAS" INT 0 3600000;
BA_DEF_ SG_  "GenSigTimeoutTime_Av2HP" INT 0 3600000;
BA_DEF_ SG_  "GenSigTimeoutTime_BCM_NBM" INT 0 3600000;
BA_DEF_ SG_  "GenSigTimeoutTime_BSM_EBS" INT 0 3600000;
BA_DEF_ SG_  "GenSigTimeoutTime_DICO" INT 0 3600000;
BA_DEF_ SG_  "GenSigTimeoutTime_DMS" INT 0 3600000;
BA_DEF_ SG_  "GenSigTimeoutTime_EBS_EBR" INT 0 3600000;
BA_DEF_ SG_  "GenSigTimeoutTime_ECM_MD1_D" INT 0 3600000;
BA_DEF_ SG_  "GenSigTimeoutTime_ECM_MD1_G" INT 0 3600000;
BA_DEF_ SG_  "GenSigTimeoutTime_ETC_DiwaNXT" INT 0 3600000;
BA_DEF_ SG_  "GenSigTimeoutTime_ETC_DiwaNXT_MH" INT 0 3600000;
BA_DEF_ SG_  "GenSigTimeoutTime_ETC_Ecolife2" INT 0 3600000;
BA_DEF_ SG_  "GenSigTimeoutTime_FCCU" INT 0 3600000;
BA_DEF_ SG_  "GenSigTimeoutTime_FMS_FMS4" INT 0 3600000;
BA_DEF_ SG_  "GenSigTimeoutTime_FMS_FMS5" INT 0 3600000;
BA_DEF_ SG_  "GenSigTimeoutTime_HVPDU_HV_BOX" INT 0 3600000;
BA_DEF_ SG_  "GenSigTimeoutTime_IC_MulticII" INT 0 3600000;
BA_DEF_ SG_  "GenSigTimeoutTime_IC_MulticS" INT 0 3600000;
BA_DEF_ SG_  "GenSigTimeoutTime_INVEM1_ELFA3" INT 0 3600000;
BA_DEF_ SG_  "GenSigTimeoutTime_MBMS" INT 0 3600000;
BA_DEF_ SG_  "GenSigTimeoutTime_MCSL" INT 0 3600000;
BA_DEF_ SG_  "GenSigTimeoutTime_MPPxPTFE2" INT 0 3600000;
BA_DEF_ SG_  "GenSigTimeoutTime_PCM" INT 0 3600000;
BA_DEF_ SG_  "GenSigTimeoutTime_RDAB_SmtRadio" INT 0 3600000;
BA_DEF_ SG_  "GenSigTimeoutTime_RM_INTD" INT 0 3600000;
BA_DEF_ SG_  "GenSigTimeoutTime_RM_IRCS" INT 0 3600000;
BA_DEF_ SG_  "GenSigTimeoutTime_SAS" INT 0 3600000;
BA_DEF_ SG_  "GenSigTimeoutTime_SGW" INT 0 3600000;
BA_DEF_ SG_  "GenSigTimeoutTime_SGW2" INT 0 3600000;
BA_DEF_ SG_  "GenSigTimeoutTime_TASM_ETS" INT 0 3600000;
BA_DEF_ SG_  "GenSigTimeoutTime_TMU_HP_Fr" INT 0 3600000;
BA_DEF_ SG_  "GenSigTimeoutTime_TMU_HP_Rr" INT 0 3600000;
BA_DEF_ SG_  "GenSigTimeoutTime_TPMS" INT 0 3600000;
BA_DEF_ SG_  "GenSigTimeoutTime_Tacho_DTCO" INT 0 3600000;
BA_DEF_ SG_  "GenSigTimeoutTime_Tacho_MTCO" INT 0 3600000;
BA_DEF_ SG_  "GenSigTimeoutTime_Tacho_TSU" INT 0 3600000;
BA_DEF_ SG_  "GenSigTimeoutTime_VCM" INT 0 3600000;
BA_DEF_ SG_  "GenSigTimeoutTime_VCU" INT 0 3600000;
BA_DEF_ SG_  "GenSigTimeoutTime_VMU" INT 0 3600000;
BA_DEF_ SG_  "SPN" INT 0 524287;
BA_DEF_ SG_  "SigType" ENUM  "Default","Range","RangeSigned","ASCII","Discrete","Control","ReferencePGN","DTC","StringDelimiter","StringLength","StringLengthControl";
BA_DEF_DEF_  "CI_MsgDefinition" "";
BA_DEF_DEF_  "CI_MsgId" 0;
BA_DEF_DEF_  "CI_MsgName" "";
BA_DEF_DEF_  "GenMsgCycleTime" 0;
BA_DEF_DEF_  "GenMsgCycleTimeFast" 0;
BA_DEF_DEF_  "GenMsgDelayTime" 1;
BA_DEF_DEF_  "GenMsgILSupport" "Yes";
BA_DEF_DEF_  "GenMsgNrOfRepetition" 0;
BA_DEF_DEF_  "GenMsgRequestable" 0;
BA_DEF_DEF_  "GenMsgSendType" "noMsgSendType";
BA_DEF_DEF_  "GenMsgStartDelayTime" 0;
BA_DEF_DEF_  "TpJ1939VarDlc" "No";
BA_DEF_DEF_  "VFrameFormat" "J1939PG";
BA_DEF_DEF_  "CI_ParId" "";
BA_DEF_DEF_  "CI_SigId" 0;
BA_DEF_DEF_  "CI_SigName" "";
BA_DEF_DEF_  "GenSigEVName" "Env@Nodename_@Signame";
BA_DEF_DEF_  "GenSigILSupport" "Yes";
BA_DEF_DEF_  "GenSigInactiveValue" 0;
BA_DEF_DEF_  "GenSigSendType" "NoSigSendType";
BA_DEF_DEF_  "GenSigStartValue" 0;
BA_DEF_DEF_  "GenSigTimeoutTime_ACM_CANAIR" 0;
BA_DEF_DEF_  "GenSigTimeoutTime_ACU" 0;
BA_DEF_DEF_  "GenSigTimeoutTime_ADCU" 0;
BA_DEF_DEF_  "GenSigTimeoutTime_AI_CAID" 0;
BA_DEF_DEF_  "GenSigTimeoutTime_ASM_ELC5_Fr" 0;
BA_DEF_DEF_  "GenSigTimeoutTime_AVAS" 0;
BA_DEF_DEF_  "GenSigTimeoutTime_Av2HP" 0;
BA_DEF_DEF_  "GenSigTimeoutTime_BCM_NBM" 0;
BA_DEF_DEF_  "GenSigTimeoutTime_BSM_EBS" 0;
BA_DEF_DEF_  "GenSigTimeoutTime_DICO" 0;
BA_DEF_DEF_  "GenSigTimeoutTime_DMS" 0;
BA_DEF_DEF_  "GenSigTimeoutTime_EBS_EBR" 0;
BA_DEF_DEF_  "GenSigTimeoutTime_ECM_MD1_D" 0;
BA_DEF_DEF_  "GenSigTimeoutTime_ECM_MD1_G" 0;
BA_DEF_DEF_  "GenSigTimeoutTime_ETC_DiwaNXT" 0;
BA_DEF_DEF_  "GenSigTimeoutTime_ETC_DiwaNXT_MH" 0;
BA_DEF_DEF_  "GenSigTimeoutTime_ETC_Ecolife2" 0;
BA_DEF_DEF_  "GenSigTimeoutTime_FCCU" 0;
BA_DEF_DEF_  "GenSigTimeoutTime_FMS_FMS4" 0;
BA_DEF_DEF_  "GenSigTimeoutTime_FMS_FMS5" 0;
BA_DEF_DEF_  "GenSigTimeoutTime_HVPDU_HV_BOX" 0;
BA_DEF_DEF_  "GenSigTimeoutTime_IC_MulticII" 0;
BA_DEF_DEF_  "GenSigTimeoutTime_IC_MulticS" 0;
BA_DEF_DEF_  "GenSigTimeoutTime_INVEM1_ELFA3" 0;
BA_DEF_DEF_  "GenSigTimeoutTime_MBMS" 0;
BA_DEF_DEF_  "GenSigTimeoutTime_MCSL" 0;
BA_DEF_DEF_  "GenSigTimeoutTime_MPPxPTFE2" 0;
BA_DEF_DEF_  "GenSigTimeoutTime_PCM" 0;
BA_DEF_DEF_  "GenSigTimeoutTime_RDAB_SmtRadio" 0;
BA_DEF_DEF_  "GenSigTimeoutTime_RM_INTD" 0;
BA_DEF_DEF_  "GenSigTimeoutTime_RM_IRCS" 0;
BA_DEF_DEF_  "GenSigTimeoutTime_SAS" 0;
BA_DEF_DEF_  "GenSigTimeoutTime_SGW" 0;
BA_DEF_DEF_  "GenSigTimeoutTime_SGW2" 0;
BA_DEF_DEF_  "GenSigTimeoutTime_TASM_ETS" 0;
BA_DEF_DEF_  "GenSigTimeoutTime_TMU_HP_Fr" 0;
BA_DEF_DEF_  "GenSigTimeoutTime_TMU_HP_Rr" 0;
BA_DEF_DEF_  "GenSigTimeoutTime_TPMS" 0;
BA_DEF_DEF_  "GenSigTimeoutTime_Tacho_DTCO" 0;
BA_DEF_DEF_  "GenSigTimeoutTime_Tacho_MTCO" 0;
BA_DEF_DEF_  "GenSigTimeoutTime_Tacho_TSU" 0;
BA_DEF_DEF_  "GenSigTimeoutTime_VCM" 0;
BA_DEF_DEF_  "GenSigTimeoutTime_VCU" 0;
BA_DEF_DEF_  "GenSigTimeoutTime_VMU" 0;
BA_DEF_DEF_  "SPN" 0;
BA_DEF_DEF_  "SigType" "Default";
BA_ "GenMsgStartDelayTime" BO_ 2566844672 20;
BA_ "GenMsgSendType" BO_ 2566844672 0;
BA_ "GenMsgDelayTime" BO_ 2566844672 50;
BA_ "GenMsgCycleTimeFast" BO_ 2566844672 100;
BA_ "GenMsgCycleTime" BO_ 2566844672 100;
BA_ "CI_MsgName" BO_ 2566844672 "CCVS1 - Cruise Control/Vehicle Speed 1";
BA_ "CI_MsgId" BO_ 2566844672 2080;
BA_ "CI_MsgDefinition" BO_ 2566844672 "J1939DA";
BA_ "GenMsgStartDelayTime" BO_ 2566890313 56;
BA_ "GenMsgSendType" BO_ 2566890313 0;
BA_ "GenMsgDelayTime" BO_ 2566890313 2500;
BA_ "GenMsgCycleTimeFast" BO_ 2566890313 5000;
BA_ "GenMsgCycleTime" BO_ 2566890313 5000;
BA_ "CI_MsgName" BO_ 2566890313 "ChargerFaults - Proprietary B - ECCU Faults";
BA_ "CI_MsgId" BO_ 2566890313 1397;
BA_ "CI_MsgDefinition" BO_ 2566890313 "Iveco Proprietary";
BA_ "TpJ1939VarDlc" BO_ 2566843165 1;
BA_ "CI_MsgName" BO_ 2566843165 "CI_1D - Component Identification";
BA_ "CI_MsgId" BO_ 2566843165 10382;
BA_ "CI_MsgDefinition" BO_ 2566843165 "J1939DA";
BA_ "TpJ1939VarDlc" BO_ 2566843230 1;
BA_ "CI_MsgName" BO_ 2566843230 "CI_5E - Component Identification";
BA_ "CI_MsgId" BO_ 2566843230 10397;
BA_ "CI_MsgDefinition" BO_ 2566843230 "J1939DA";
BA_ "GenMsgStartDelayTime" BO_ 2566865139 38;
BA_ "GenMsgSendType" BO_ 2566865139 0;
BA_ "GenMsgDelayTime" BO_ 2566865139 2500;
BA_ "GenMsgCycleTimeFast" BO_ 2566865139 5000;
BA_ "GenMsgCycleTime" BO_ 2566865139 5000;
BA_ "CI_MsgName" BO_ 2566865139 "CLIM_LTO_STATUS - Status of the Clim System of the LTO Batteries";
BA_ "CI_MsgId" BO_ 2566865139 3881;
BA_ "CI_MsgDefinition" BO_ 2566865139 "Iveco Bus Proprietary";
BA_ "GenMsgStartDelayTime" BO_ 2566811659 46;
BA_ "GenMsgSendType" BO_ 2566811659 0;
BA_ "GenMsgDelayTime" BO_ 2566811659 500;
BA_ "GenMsgCycleTimeFast" BO_ 2566811659 1000;
BA_ "GenMsgCycleTime" BO_ 2566811659 1000;
BA_ "CI_MsgName" BO_ 2566811659 "CVW_0B - Combination Vehicle Weight";
BA_ "CI_MsgId" BO_ 2566811659 389;
BA_ "CI_MsgDefinition" BO_ 2566811659 "J1939DA";
BA_ "GenMsgStartDelayTime" BO_ 2566802967 42;
BA_ "GenMsgSendType" BO_ 2566802967 0;
BA_ "GenMsgDelayTime" BO_ 2566802967 50;
BA_ "GenMsgCycleTimeFast" BO_ 2566802967 100;
BA_ "GenMsgCycleTime" BO_ 2566802967 100;
BA_ "CI_MsgName" BO_ 2566802967 "DC1_17 - Door Control 1";
BA_ "CI_MsgId" BO_ 2566802967 3267;
BA_ "CI_MsgDefinition" BO_ 2566802967 "J1939DA";
BA_ "GenMsgStartDelayTime" BO_ 2566759703 30;
BA_ "GenMsgSendType" BO_ 2566759703 0;
BA_ "GenMsgDelayTime" BO_ 2566759703 50;
BA_ "GenMsgCycleTimeFast" BO_ 2566759703 100;
BA_ "GenMsgCycleTime" BO_ 2566759703 100;
BA_ "CI_MsgName" BO_ 2566759703 "DC2_17 - Door Control 2";
BA_ "CI_MsgId" BO_ 2566759703 3271;
BA_ "CI_MsgDefinition" BO_ 2566759703 "J1939DA";
BA_ "CI_MsgName" BO_ 2566849774 "DCPD - DriversConsentOnPersonalData (Continental Proprietary)";
BA_ "CI_MsgId" BO_ 2566849774 2581;
BA_ "CI_MsgDefinition" BO_ 2566849774 "Continental Proprietary";
BA_ "GenMsgStartDelayTime" BO_ 2566847521 140;
BA_ "GenMsgSendType" BO_ 2566847521 0;
BA_ "GenMsgDelayTime" BO_ 2566847521 100;
BA_ "GenMsgCycleTimeFast" BO_ 2566847521 1000;
BA_ "GenMsgCycleTime" BO_ 2566847521 1000;
BA_ "CI_MsgName" BO_ 2566847521 "DD1_21 - Dash Display 1";
BA_ "CI_MsgId" BO_ 2566847521 2997;
BA_ "CI_MsgDefinition" BO_ 2566847521 "J1939DA";
BA_ "TpJ1939VarDlc" BO_ 2566810606 1;
BA_ "CI_MsgName" BO_ 2566810606 "DI_EE - Driver's Identification";
BA_ "CI_MsgId" BO_ 2566810606 729;
BA_ "CI_MsgDefinition" BO_ 2566810606 "J1939DA";
BA_ "TpJ1939VarDlc" BO_ 2566834688 1;
BA_ "GenMsgStartDelayTime" BO_ 2566834688 49;
BA_ "GenMsgSendType" BO_ 2566834688 0;
BA_ "GenMsgDelayTime" BO_ 2566834688 100;
BA_ "GenMsgCycleTimeFast" BO_ 2566834688 1000;
BA_ "GenMsgCycleTime" BO_ 2566834688 1000;
BA_ "CI_MsgName" BO_ 2566834688 "DM01_00 - Active Diagnostic Trouble Codes";
BA_ "CI_MsgId" BO_ 2566834688 4456;
BA_ "CI_MsgDefinition" BO_ 2566834688 "J1939-73";
BA_ "TpJ1939VarDlc" BO_ 2566834691 1;
BA_ "GenMsgStartDelayTime" BO_ 2566834691 27;
BA_ "GenMsgSendType" BO_ 2566834691 0;
BA_ "GenMsgDelayTime" BO_ 2566834691 100;
BA_ "GenMsgCycleTimeFast" BO_ 2566834691 1000;
BA_ "GenMsgCycleTime" BO_ 2566834691 1000;
BA_ "CI_MsgName" BO_ 2566834691 "DM01_03 - Active Diagnostic Trouble Codes";
BA_ "CI_MsgId" BO_ 2566834691 4565;
BA_ "CI_MsgDefinition" BO_ 2566834691 "J1939-73";
BA_ "TpJ1939VarDlc" BO_ 2566834699 1;
BA_ "GenMsgStartDelayTime" BO_ 2566834699 51;
BA_ "GenMsgSendType" BO_ 2566834699 0;
BA_ "GenMsgDelayTime" BO_ 2566834699 100;
BA_ "GenMsgCycleTimeFast" BO_ 2566834699 1000;
BA_ "GenMsgCycleTime" BO_ 2566834699 1000;
BA_ "CI_MsgName" BO_ 2566834699 "DM01_0B - Active Diagnostic Trouble Codes";
BA_ "CI_MsgId" BO_ 2566834699 4624;
BA_ "CI_MsgDefinition" BO_ 2566834699 "J1939-73";
BA_ "TpJ1939VarDlc" BO_ 2566834704 1;
BA_ "GenMsgStartDelayTime" BO_ 2566834704 6;
BA_ "GenMsgSendType" BO_ 2566834704 0;
BA_ "GenMsgDelayTime" BO_ 2566834704 100;
BA_ "GenMsgCycleTimeFast" BO_ 2566834704 1000;
BA_ "GenMsgCycleTime" BO_ 2566834704 1000;
BA_ "CI_MsgName" BO_ 2566834704 "DM01_10 - Active Diagnostic Trouble Codes";
BA_ "CI_MsgId" BO_ 2566834704 4679;
BA_ "CI_MsgDefinition" BO_ 2566834704 "J1939-73";
BA_ "TpJ1939VarDlc" BO_ 2566834711 1;
BA_ "GenMsgStartDelayTime" BO_ 2566834711 84;
BA_ "GenMsgSendType" BO_ 2566834711 0;
BA_ "GenMsgDelayTime" BO_ 2566834711 100;
BA_ "GenMsgCycleTimeFast" BO_ 2566834711 1000;
BA_ "GenMsgCycleTime" BO_ 2566834711 1000;
BA_ "CI_MsgName" BO_ 2566834711 "DM01_17 - Active Diagnostic Trouble Codes";
BA_ "CI_MsgId" BO_ 2566834711 4738;
BA_ "CI_MsgDefinition" BO_ 2566834711 "J1939-73";
BA_ "TpJ1939VarDlc" BO_ 2566834716 1;
BA_ "GenMsgStartDelayTime" BO_ 2566834716 152;
BA_ "GenMsgSendType" BO_ 2566834716 0;
BA_ "GenMsgDelayTime" BO_ 2566834716 100;
BA_ "GenMsgCycleTimeFast" BO_ 2566834716 1000;
BA_ "GenMsgCycleTime" BO_ 2566834716 1000;
BA_ "CI_MsgName" BO_ 2566834716 "DM01_1C - Active Diagnostic Trouble Codes";
BA_ "CI_MsgId" BO_ 2566834716 5008;
BA_ "CI_MsgDefinition" BO_ 2566834716 "J1939-73";
BA_ "TpJ1939VarDlc" BO_ 2566834717 1;
BA_ "GenMsgStartDelayTime" BO_ 2566834717 24;
BA_ "GenMsgSendType" BO_ 2566834717 0;
BA_ "GenMsgDelayTime" BO_ 2566834717 100;
BA_ "GenMsgCycleTimeFast" BO_ 2566834717 1000;
BA_ "GenMsgCycleTime" BO_ 2566834717 1000;
BA_ "CI_MsgName" BO_ 2566834717 "DM01_1D - Active Diagnostic Trouble Codes";
BA_ "CI_MsgId" BO_ 2566834717 5063;
BA_ "CI_MsgDefinition" BO_ 2566834717 "J1939-73";
BA_ "TpJ1939VarDlc" BO_ 2566834721 1;
BA_ "GenMsgStartDelayTime" BO_ 2566834721 132;
BA_ "GenMsgSendType" BO_ 2566834721 0;
BA_ "GenMsgDelayTime" BO_ 2566834721 100;
BA_ "GenMsgCycleTimeFast" BO_ 2566834721 1000;
BA_ "GenMsgCycleTime" BO_ 2566834721 1000;
BA_ "CI_MsgName" BO_ 2566834721 "DM01_21 - Active Diagnostic Trouble Codes";
BA_ "CI_MsgId" BO_ 2566834721 5118;
BA_ "CI_MsgDefinition" BO_ 2566834721 "J1939-73";
BA_ "TpJ1939VarDlc" BO_ 2566834727 1;
BA_ "GenMsgStartDelayTime" BO_ 2566834727 6;
BA_ "GenMsgSendType" BO_ 2566834727 0;
BA_ "GenMsgDelayTime" BO_ 2566834727 100;
BA_ "GenMsgCycleTimeFast" BO_ 2566834727 1000;
BA_ "GenMsgCycleTime" BO_ 2566834727 1000;
BA_ "CI_MsgName" BO_ 2566834727 "DM01_27 - Active Diagnostic Trouble Codes";
BA_ "CI_MsgId" BO_ 2566834727 5173;
BA_ "CI_MsgDefinition" BO_ 2566834727 "J1939-73";
BA_ "TpJ1939VarDlc" BO_ 2566834734 1;
BA_ "GenMsgSendType" BO_ 2566834734 0;
BA_ "GenMsgDelayTime" BO_ 2566834734 100;
BA_ "GenMsgCycleTimeFast" BO_ 2566834734 1000;
BA_ "GenMsgCycleTime" BO_ 2566834734 1000;
BA_ "CI_MsgName" BO_ 2566834734 "DM01_2E - Active Diagnostic Trouble Codes";
BA_ "CI_MsgId" BO_ 2566834734 5283;
BA_ "CI_MsgDefinition" BO_ 2566834734 "J1939-73";
BA_ "TpJ1939VarDlc" BO_ 2566834735 1;
BA_ "GenMsgStartDelayTime" BO_ 2566834735 8;
BA_ "GenMsgSendType" BO_ 2566834735 0;
BA_ "GenMsgDelayTime" BO_ 2566834735 100;
BA_ "GenMsgCycleTimeFast" BO_ 2566834735 1000;
BA_ "GenMsgCycleTime" BO_ 2566834735 1000;
BA_ "CI_MsgName" BO_ 2566834735 "DM01_2F - Active Diagnostic Trouble Codes";
BA_ "CI_MsgId" BO_ 2566834735 5338;
BA_ "CI_MsgDefinition" BO_ 2566834735 "J1939-73";
BA_ "TpJ1939VarDlc" BO_ 2566834739 1;
BA_ "GenMsgStartDelayTime" BO_ 2566834739 2;
BA_ "GenMsgSendType" BO_ 2566834739 0;
BA_ "GenMsgDelayTime" BO_ 2566834739 100;
BA_ "GenMsgCycleTimeFast" BO_ 2566834739 1000;
BA_ "GenMsgCycleTime" BO_ 2566834739 1000;
BA_ "CI_MsgName" BO_ 2566834739 "DM01_33 - Active Diagnostic Trouble Codes";
BA_ "CI_MsgId" BO_ 2566834739 5448;
BA_ "CI_MsgDefinition" BO_ 2566834739 "J1939-73";
BA_ "TpJ1939VarDlc" BO_ 2566834744 1;
BA_ "GenMsgSendType" BO_ 2566834744 0;
BA_ "GenMsgDelayTime" BO_ 2566834744 100;
BA_ "GenMsgCycleTimeFast" BO_ 2566834744 1000;
BA_ "GenMsgCycleTime" BO_ 2566834744 1000;
BA_ "CI_MsgName" BO_ 2566834744 "DM01_38 - Active Diagnostic Trouble Codes";
BA_ "CI_MsgId" BO_ 2566834744 5503;
BA_ "CI_MsgDefinition" BO_ 2566834744 "J1939-73";
BA_ "TpJ1939VarDlc" BO_ 2566834752 1;
BA_ "GenMsgStartDelayTime" BO_ 2566834752 8;
BA_ "GenMsgSendType" BO_ 2566834752 0;
BA_ "GenMsgDelayTime" BO_ 2566834752 100;
BA_ "GenMsgCycleTimeFast" BO_ 2566834752 1000;
BA_ "GenMsgCycleTime" BO_ 2566834752 1000;
BA_ "CI_MsgName" BO_ 2566834752 "DM01_40 - Active Diagnostic Trouble Codes";
BA_ "CI_MsgId" BO_ 2566834752 5793;
BA_ "CI_MsgDefinition" BO_ 2566834752 "J1939-73";
BA_ "TpJ1939VarDlc" BO_ 2566834761 1;
BA_ "GenMsgSendType" BO_ 2566834761 0;
BA_ "GenMsgDelayTime" BO_ 2566834761 100;
BA_ "GenMsgCycleTimeFast" BO_ 2566834761 1000;
BA_ "GenMsgCycleTime" BO_ 2566834761 1000;
BA_ "CI_MsgName" BO_ 2566834761 "DM01_49 - Active Diagnostic Trouble Codes";
BA_ "CI_MsgId" BO_ 2566834761 4953;
BA_ "CI_MsgDefinition" BO_ 2566834761 "J1939-73";
BA_ "TpJ1939VarDlc" BO_ 2566834762 1;
BA_ "GenMsgStartDelayTime" BO_ 2566834762 154;
BA_ "GenMsgSendType" BO_ 2566834762 0;
BA_ "GenMsgDelayTime" BO_ 2566834762 100;
BA_ "GenMsgCycleTimeFast" BO_ 2566834762 1000;
BA_ "GenMsgCycleTime" BO_ 2566834762 1000;
BA_ "CI_MsgName" BO_ 2566834762 "DM01_4A - Active Diagnostic Trouble Codes";
BA_ "CI_MsgId" BO_ 2566834762 5558;
BA_ "CI_MsgDefinition" BO_ 2566834762 "J1939-73";
BA_ "TpJ1939VarDlc" BO_ 2566834778 1;
BA_ "GenMsgStartDelayTime" BO_ 2566834778 12;
BA_ "GenMsgSendType" BO_ 2566834778 0;
BA_ "GenMsgDelayTime" BO_ 2566834778 100;
BA_ "GenMsgCycleTimeFast" BO_ 2566834778 1000;
BA_ "GenMsgCycleTime" BO_ 2566834778 1000;
BA_ "CI_MsgName" BO_ 2566834778 "DM01_5A - Active Diagnostic Trouble Codes";
BA_ "CI_MsgId" BO_ 2566834778 5738;
BA_ "CI_MsgDefinition" BO_ 2566834778 "J1939-73";
BA_ "TpJ1939VarDlc" BO_ 2566834782 1;
BA_ "GenMsgStartDelayTime" BO_ 2566834782 6;
BA_ "GenMsgSendType" BO_ 2566834782 0;
BA_ "GenMsgDelayTime" BO_ 2566834782 100;
BA_ "GenMsgCycleTimeFast" BO_ 2566834782 1000;
BA_ "GenMsgCycleTime" BO_ 2566834782 1000;
BA_ "CI_MsgName" BO_ 2566834782 "DM01_5E - Active Diagnostic Trouble Codes";
BA_ "CI_MsgId" BO_ 2566834782 14754;
BA_ "CI_MsgDefinition" BO_ 2566834782 "J1939-73";
BA_ "TpJ1939VarDlc" BO_ 2566834814 1;
BA_ "GenMsgStartDelayTime" BO_ 2566834814 2;
BA_ "GenMsgSendType" BO_ 2566834814 0;
BA_ "GenMsgDelayTime" BO_ 2566834814 100;
BA_ "GenMsgCycleTimeFast" BO_ 2566834814 1000;
BA_ "GenMsgCycleTime" BO_ 2566834814 1000;
BA_ "CI_MsgName" BO_ 2566834814 "DM01_7E - Active Diagnostic Trouble Codes";
BA_ "CI_MsgId" BO_ 2566834814 5903;
BA_ "CI_MsgDefinition" BO_ 2566834814 "J1939-73";
BA_ "TpJ1939VarDlc" BO_ 2566834832 1;
BA_ "GenMsgSendType" BO_ 2566834832 0;
BA_ "GenMsgDelayTime" BO_ 2566834832 100;
BA_ "GenMsgCycleTimeFast" BO_ 2566834832 1000;
BA_ "GenMsgCycleTime" BO_ 2566834832 1000;
BA_ "CI_MsgName" BO_ 2566834832 "DM01_90 - Active Diagnostic Trouble Codes";
BA_ "CI_MsgId" BO_ 2566834832 6068;
BA_ "CI_MsgDefinition" BO_ 2566834832 "J1939-73";
BA_ "TpJ1939VarDlc" BO_ 2566834833 1;
BA_ "GenMsgSendType" BO_ 2566834833 0;
BA_ "GenMsgDelayTime" BO_ 2566834833 100;
BA_ "GenMsgCycleTimeFast" BO_ 2566834833 1000;
BA_ "GenMsgCycleTime" BO_ 2566834833 1000;
BA_ "CI_MsgName" BO_ 2566834833 "DM01_91 - Active Diagnostic Trouble Codes";
BA_ "CI_MsgId" BO_ 2566834833 6123;
BA_ "CI_MsgDefinition" BO_ 2566834833 "J1939-73";
BA_ "TpJ1939VarDlc" BO_ 2566834834 1;
BA_ "GenMsgSendType" BO_ 2566834834 0;
BA_ "GenMsgDelayTime" BO_ 2566834834 100;
BA_ "GenMsgCycleTimeFast" BO_ 2566834834 1000;
BA_ "GenMsgCycleTime" BO_ 2566834834 1000;
BA_ "CI_MsgName" BO_ 2566834834 "DM01_92 - Active Diagnostic Trouble Codes";
BA_ "CI_MsgId" BO_ 2566834834 6178;
BA_ "CI_MsgDefinition" BO_ 2566834834 "J1939-73";
BA_ "TpJ1939VarDlc" BO_ 2566834844 1;
BA_ "GenMsgSendType" BO_ 2566834844 0;
BA_ "GenMsgDelayTime" BO_ 2566834844 100;
BA_ "GenMsgCycleTimeFast" BO_ 2566834844 1000;
BA_ "GenMsgCycleTime" BO_ 2566834844 1000;
BA_ "CI_MsgName" BO_ 2566834844 "DM01_9C - Active Diagnostic Trouble Codes";
BA_ "CI_MsgId" BO_ 2566834844 6233;
BA_ "CI_MsgDefinition" BO_ 2566834844 "J1939-73";
BA_ "TpJ1939VarDlc" BO_ 2566834846 1;
BA_ "GenMsgStartDelayTime" BO_ 2566834846 16;
BA_ "GenMsgSendType" BO_ 2566834846 0;
BA_ "GenMsgDelayTime" BO_ 2566834846 100;
BA_ "GenMsgCycleTimeFast" BO_ 2566834846 1000;
BA_ "GenMsgCycleTime" BO_ 2566834846 1000;
BA_ "CI_MsgName" BO_ 2566834846 "DM01_9E - Active Diagnostic Trouble Codes";
BA_ "CI_MsgId" BO_ 2566834846 5958;
BA_ "CI_MsgDefinition" BO_ 2566834846 "J1939-73";
BA_ "TpJ1939VarDlc" BO_ 2566834848 1;
BA_ "GenMsgSendType" BO_ 2566834848 0;
BA_ "GenMsgDelayTime" BO_ 2566834848 100;
BA_ "GenMsgCycleTimeFast" BO_ 2566834848 1000;
BA_ "GenMsgCycleTime" BO_ 2566834848 1000;
BA_ "CI_MsgName" BO_ 2566834848 "DM01_A0 - Active Diagnostic Trouble Codes";
BA_ "CI_MsgId" BO_ 2566834848 6288;
BA_ "CI_MsgDefinition" BO_ 2566834848 "J1939-73";
BA_ "TpJ1939VarDlc" BO_ 2566834920 1;
BA_ "GenMsgSendType" BO_ 2566834920 0;
BA_ "GenMsgDelayTime" BO_ 2566834920 100;
BA_ "GenMsgCycleTimeFast" BO_ 2566834920 1000;
BA_ "GenMsgCycleTime" BO_ 2566834920 1000;
BA_ "CI_MsgName" BO_ 2566834920 "DM01_E8 - Active Diagnostic Trouble Codes";
BA_ "CI_MsgId" BO_ 2566834920 6013;
BA_ "CI_MsgDefinition" BO_ 2566834920 "J1939-73";
BA_ "TpJ1939VarDlc" BO_ 2566834926 1;
BA_ "GenMsgStartDelayTime" BO_ 2566834926 22;
BA_ "GenMsgSendType" BO_ 2566834926 0;
BA_ "GenMsgDelayTime" BO_ 2566834926 100;
BA_ "GenMsgCycleTimeFast" BO_ 2566834926 1000;
BA_ "GenMsgCycleTime" BO_ 2566834926 1000;
BA_ "CI_MsgName" BO_ 2566834926 "DM01_EE - Active Diagnostic Trouble Codes";
BA_ "CI_MsgId" BO_ 2566834926 6353;
BA_ "CI_MsgDefinition" BO_ 2566834926 "J1939-73";
BA_ "TpJ1939VarDlc" BO_ 2566834928 1;
BA_ "GenMsgSendType" BO_ 2566834928 0;
BA_ "GenMsgDelayTime" BO_ 2566834928 100;
BA_ "GenMsgCycleTimeFast" BO_ 2566834928 1000;
BA_ "GenMsgCycleTime" BO_ 2566834928 1000;
BA_ "CI_MsgName" BO_ 2566834928 "DM01_F0 - Active Diagnostic Trouble Codes";
BA_ "CI_MsgId" BO_ 2566834928 20562;
BA_ "CI_MsgDefinition" BO_ 2566834928 "J1939-73";
BA_ "TpJ1939VarDlc" BO_ 2566834931 1;
BA_ "GenMsgStartDelayTime" BO_ 2566834931 14;
BA_ "GenMsgSendType" BO_ 2566834931 0;
BA_ "GenMsgDelayTime" BO_ 2566834931 100;
BA_ "GenMsgCycleTimeFast" BO_ 2566834931 1000;
BA_ "GenMsgCycleTime" BO_ 2566834931 1000;
BA_ "CI_MsgName" BO_ 2566834931 "DM01_F3 - Active Diagnostic Trouble Codes";
BA_ "CI_MsgId" BO_ 2566834931 6408;
BA_ "CI_MsgDefinition" BO_ 2566834931 "J1939-73";
BA_ "TpJ1939VarDlc" BO_ 2566834972 1;
BA_ "CI_MsgName" BO_ 2566834972 "DM02_1C - Previously Active Diagnostic Trouble Codes";
BA_ "CI_MsgId" BO_ 2566834972 6797;
BA_ "CI_MsgDefinition" BO_ 2566834972 "J1939-73";
BA_ "TpJ1939VarDlc" BO_ 2566834973 1;
BA_ "CI_MsgName" BO_ 2566834973 "DM02_1D - Previously Active Diagnostic Trouble Codes";
BA_ "CI_MsgId" BO_ 2566834973 6966;
BA_ "CI_MsgDefinition" BO_ 2566834973 "J1939-73";
BA_ "TpJ1939VarDlc" BO_ 2566835102 1;
BA_ "CI_MsgName" BO_ 2566835102 "DM02_9E - Previously Active Diagnostic Trouble Codes";
BA_ "CI_MsgId" BO_ 2566835102 7241;
BA_ "CI_MsgDefinition" BO_ 2566835102 "J1939-73";
BA_ "TpJ1939VarDlc" BO_ 2566835485 1;
BA_ "CI_MsgName" BO_ 2566835485 "DM04_1D - Freeze Frame Parameters";
BA_ "CI_MsgId" BO_ 2566835485 8594;
BA_ "CI_MsgDefinition" BO_ 2566835485 "Iveco Proprietary";
BA_ "TpJ1939VarDlc" BO_ 2566835614 1;
BA_ "CI_MsgName" BO_ 2566835614 "DM04_9E - Freeze Frame Parameters";
BA_ "CI_MsgId" BO_ 2566835614 9197;
BA_ "CI_MsgDefinition" BO_ 2566835614 "Iveco Proprietary";
BA_ "TpJ1939VarDlc" BO_ 2633943577 1;
BA_ "GenMsgStartDelayTime" BO_ 2633943577 2;
BA_ "GenMsgSendType" BO_ 2633943577 0;
BA_ "GenMsgDelayTime" BO_ 2633943577 100;
BA_ "GenMsgCycleTimeFast" BO_ 2633943577 1000;
BA_ "GenMsgCycleTime" BO_ 2633943577 1000;
BA_ "CI_MsgName" BO_ 2633943577 "DM1_19_P7 - Active Diagnostic Trouble Codes";
BA_ "CI_MsgId" BO_ 2633943577 14916;
BA_ "CI_MsgDefinition" BO_ 2633943577 "J1939-73";
BA_ "TpJ1939VarDlc" BO_ 2633943610 1;
BA_ "GenMsgSendType" BO_ 2633943610 0;
BA_ "GenMsgDelayTime" BO_ 2633943610 100;
BA_ "GenMsgCycleTimeFast" BO_ 2633943610 1000;
BA_ "GenMsgCycleTime" BO_ 2633943610 1000;
BA_ "CI_MsgName" BO_ 2633943610 "DM1_3A_P7 - Active Diagnostic Trouble Codes";
BA_ "CI_MsgId" BO_ 2633943610 20735;
BA_ "CI_MsgDefinition" BO_ 2633943610 "J1939-73";
BA_ "TpJ1939VarDlc" BO_ 2633943680 1;
BA_ "GenMsgStartDelayTime" BO_ 2633943680 53;
BA_ "GenMsgSendType" BO_ 2633943680 0;
BA_ "GenMsgDelayTime" BO_ 2633943680 100;
BA_ "GenMsgCycleTimeFast" BO_ 2633943680 1000;
BA_ "GenMsgCycleTime" BO_ 2633943680 1000;
BA_ "CI_MsgName" BO_ 2633943680 "DM1_80_P7 - Active Diagnostic Trouble Codes";
BA_ "CI_MsgId" BO_ 2633943680 5668;
BA_ "CI_MsgDefinition" BO_ 2633943680 "J1939-73";
BA_ "GenMsgStartDelayTime" BO_ 2566856773 163;
BA_ "GenMsgSendType" BO_ 2566856773 0;
BA_ "GenMsgDelayTime" BO_ 2566856773 500;
BA_ "GenMsgCycleTimeFast" BO_ 2566856773 1000;
BA_ "GenMsgCycleTime" BO_ 2566856773 1000;
BA_ "CI_MsgName" BO_ 2566856773 "DoorStat - Doors status for PCM";
BA_ "CI_MsgId" BO_ 2566856773 3364;
BA_ "CI_MsgDefinition" BO_ 2566856773 "Iveco Proprietary";
BA_ "GenMsgStartDelayTime" BO_ 2566749184 45;
BA_ "GenMsgSendType" BO_ 2566749184 0;
BA_ "GenMsgDelayTime" BO_ 2566749184 100;
BA_ "GenMsgCycleTimeFast" BO_ 2566749184 1000;
BA_ "GenMsgCycleTime" BO_ 2566749184 1000;
BA_ "CI_MsgName" BO_ 2566749184 "DPFC1 - Diesel Particulate Filter Control 1";
BA_ "CI_MsgId" BO_ 2566749184 1215;
BA_ "CI_MsgDefinition" BO_ 2566749184 "J1939DA";
BA_ "GenMsgStartDelayTime" BO_ 2561126730 4;
BA_ "GenMsgSendType" BO_ 2561126730 0;
BA_ "GenMsgDelayTime" BO_ 2561126730 500;
BA_ "GenMsgCycleTimeFast" BO_ 2561126730 1000;
BA_ "GenMsgCycleTime" BO_ 2561126730 1000;
BA_ "CI_MsgName" BO_ 2561126730 "DSE_ACC - DSE Acc";
BA_ "CI_MsgId" BO_ 2561126730 14224;
BA_ "CI_MsgDefinition" BO_ 2561126730 "Iveco Bus Proprietary";
BA_ "GenMsgStartDelayTime" BO_ 2561126986 6;
BA_ "GenMsgSendType" BO_ 2561126986 0;
BA_ "GenMsgDelayTime" BO_ 2561126986 500;
BA_ "GenMsgCycleTimeFast" BO_ 2561126986 1000;
BA_ "GenMsgCycleTime" BO_ 2561126986 1000;
BA_ "CI_MsgName" BO_ 2561126986 "DSE_ACC_DBG - DSE Acc DBG";
BA_ "CI_MsgId" BO_ 2561126986 14230;
BA_ "CI_MsgDefinition" BO_ 2561126986 "Iveco Bus Proprietary";
BA_ "GenMsgStartDelayTime" BO_ 2561127242 8;
BA_ "GenMsgSendType" BO_ 2561127242 0;
BA_ "GenMsgDelayTime" BO_ 2561127242 500;
BA_ "GenMsgCycleTimeFast" BO_ 2561127242 1000;
BA_ "GenMsgCycleTime" BO_ 2561127242 1000;
BA_ "CI_MsgName" BO_ 2561127242 "DSE_ACCE - DSE Acceleration";
BA_ "CI_MsgId" BO_ 2561127242 14233;
BA_ "CI_MsgDefinition" BO_ 2561127242 "Iveco Bus Proprietary";
BA_ "GenMsgStartDelayTime" BO_ 2561127498 10;
BA_ "GenMsgSendType" BO_ 2561127498 0;
BA_ "GenMsgDelayTime" BO_ 2561127498 500;
BA_ "GenMsgCycleTimeFast" BO_ 2561127498 1000;
BA_ "GenMsgCycleTime" BO_ 2561127498 1000;
BA_ "CI_MsgName" BO_ 2561127498 "DSE_ACCE_DBG - DSE Acceleration DBG";
BA_ "CI_MsgId" BO_ 2561127498 14239;
BA_ "CI_MsgDefinition" BO_ 2561127498 "Iveco Bus Proprietary";
BA_ "GenMsgStartDelayTime" BO_ 2561127754 12;
BA_ "GenMsgSendType" BO_ 2561127754 0;
BA_ "GenMsgDelayTime" BO_ 2561127754 500;
BA_ "GenMsgCycleTimeFast" BO_ 2561127754 1000;
BA_ "GenMsgCycleTime" BO_ 2561127754 1000;
BA_ "CI_MsgName" BO_ 2561127754 "DSE_AEBS - DSE Aebs";
BA_ "CI_MsgId" BO_ 2561127754 14245;
BA_ "CI_MsgDefinition" BO_ 2561127754 "Iveco Bus Proprietary";
BA_ "GenMsgStartDelayTime" BO_ 2561128010 14;
BA_ "GenMsgSendType" BO_ 2561128010 0;
BA_ "GenMsgDelayTime" BO_ 2561128010 500;
BA_ "GenMsgCycleTimeFast" BO_ 2561128010 1000;
BA_ "GenMsgCycleTime" BO_ 2561128010 1000;
BA_ "CI_MsgName" BO_ 2561128010 "DSE_AEBS_DBG - DSE Aebs DBG";
BA_ "CI_MsgId" BO_ 2561128010 14251;
BA_ "CI_MsgDefinition" BO_ 2561128010 "Iveco Bus Proprietary";
BA_ "GenMsgStartDelayTime" BO_ 2561128266 16;
BA_ "GenMsgSendType" BO_ 2561128266 0;
BA_ "GenMsgDelayTime" BO_ 2561128266 500;
BA_ "GenMsgCycleTimeFast" BO_ 2561128266 1000;
BA_ "GenMsgCycleTime" BO_ 2561128266 1000;
BA_ "CI_MsgName" BO_ 2561128266 "DSE_AirC - DSE AirC";
BA_ "CI_MsgId" BO_ 2561128266 14254;
BA_ "CI_MsgDefinition" BO_ 2561128266 "Iveco Bus Proprietary";
BA_ "GenMsgStartDelayTime" BO_ 2561128522 18;
BA_ "GenMsgSendType" BO_ 2561128522 0;
BA_ "GenMsgDelayTime" BO_ 2561128522 500;
BA_ "GenMsgCycleTimeFast" BO_ 2561128522 1000;
BA_ "GenMsgCycleTime" BO_ 2561128522 1000;
BA_ "CI_MsgName" BO_ 2561128522 "DSE_AirC_DBG - DSE AirC DBG";
BA_ "CI_MsgId" BO_ 2561128522 14260;
BA_ "CI_MsgDefinition" BO_ 2561128522 "Iveco Bus Proprietary";
BA_ "GenMsgStartDelayTime" BO_ 2561144138 134;
BA_ "GenMsgSendType" BO_ 2561144138 0;
BA_ "GenMsgDelayTime" BO_ 2561144138 500;
BA_ "GenMsgCycleTimeFast" BO_ 2561144138 1000;
BA_ "GenMsgCycleTime" BO_ 2561144138 1000;
BA_ "CI_MsgName" BO_ 2561144138 "DSE_ATTENTION - DSE Attention";
BA_ "CI_MsgId" BO_ 2561144138 14262;
BA_ "CI_MsgDefinition" BO_ 2561144138 "Iveco Bus Proprietary";
BA_ "GenMsgStartDelayTime" BO_ 2561128778 20;
BA_ "GenMsgSendType" BO_ 2561128778 0;
BA_ "GenMsgDelayTime" BO_ 2561128778 500;
BA_ "GenMsgCycleTimeFast" BO_ 2561128778 1000;
BA_ "GenMsgCycleTime" BO_ 2561128778 1000;
BA_ "CI_MsgName" BO_ 2561128778 "DSE_AUXBK - DSE AuxBrake";
BA_ "CI_MsgId" BO_ 2561128778 14268;
BA_ "CI_MsgDefinition" BO_ 2561128778 "Iveco Bus Proprietary";
BA_ "GenMsgStartDelayTime" BO_ 2561129034 22;
BA_ "GenMsgSendType" BO_ 2561129034 0;
BA_ "GenMsgDelayTime" BO_ 2561129034 500;
BA_ "GenMsgCycleTimeFast" BO_ 2561129034 1000;
BA_ "GenMsgCycleTime" BO_ 2561129034 1000;
BA_ "CI_MsgName" BO_ 2561129034 "DSE_AUXBK_DBG - DSE AuxBrake DBG";
BA_ "CI_MsgId" BO_ 2561129034 14274;
BA_ "CI_MsgDefinition" BO_ 2561129034 "Iveco Bus Proprietary";
BA_ "GenMsgStartDelayTime" BO_ 2561145930 148;
BA_ "GenMsgSendType" BO_ 2561145930 0;
BA_ "GenMsgDelayTime" BO_ 2561145930 500;
BA_ "GenMsgCycleTimeFast" BO_ 2561145930 1000;
BA_ "GenMsgCycleTime" BO_ 2561145930 1000;
BA_ "CI_MsgName" BO_ 2561145930 "DSE_BSIS - DSE Bsis";
BA_ "CI_MsgId" BO_ 2561145930 14282;
BA_ "CI_MsgDefinition" BO_ 2561145930 "Iveco Bus Proprietary";
BA_ "GenMsgStartDelayTime" BO_ 2561129290 24;
BA_ "GenMsgSendType" BO_ 2561129290 0;
BA_ "GenMsgDelayTime" BO_ 2561129290 500;
BA_ "GenMsgCycleTimeFast" BO_ 2561129290 1000;
BA_ "GenMsgCycleTime" BO_ 2561129290 1000;
BA_ "CI_MsgName" BO_ 2561129290 "DSE_CARE - DSE Care";
BA_ "CI_MsgId" BO_ 2561129290 14288;
BA_ "CI_MsgDefinition" BO_ 2561129290 "Iveco Bus Proprietary";
BA_ "GenMsgStartDelayTime" BO_ 2561129546 26;
BA_ "GenMsgSendType" BO_ 2561129546 0;
BA_ "GenMsgDelayTime" BO_ 2561129546 500;
BA_ "GenMsgCycleTimeFast" BO_ 2561129546 1000;
BA_ "GenMsgCycleTime" BO_ 2561129546 1000;
BA_ "CI_MsgName" BO_ 2561129546 "DSE_CMD - DSE CMD";
BA_ "CI_MsgId" BO_ 2561129546 14294;
BA_ "CI_MsgDefinition" BO_ 2561129546 "Iveco Bus Proprietary";
BA_ "GenMsgStartDelayTime" BO_ 2561130058 30;
BA_ "GenMsgSendType" BO_ 2561130058 0;
BA_ "GenMsgDelayTime" BO_ 2561130058 500;
BA_ "GenMsgCycleTimeFast" BO_ 2561130058 1000;
BA_ "GenMsgCycleTime" BO_ 2561130058 1000;
BA_ "CI_MsgName" BO_ 2561130058 "DSE_COMFORT - DSE Comfort";
BA_ "CI_MsgId" BO_ 2561130058 14297;
BA_ "CI_MsgDefinition" BO_ 2561130058 "Iveco Bus Proprietary";
BA_ "GenMsgStartDelayTime" BO_ 2561129802 28;
BA_ "GenMsgSendType" BO_ 2561129802 0;
BA_ "GenMsgDelayTime" BO_ 2561129802 500;
BA_ "GenMsgCycleTimeFast" BO_ 2561129802 1000;
BA_ "GenMsgCycleTime" BO_ 2561129802 1000;
BA_ "CI_MsgName" BO_ 2561129802 "DSE_CURNT - DSE Curent";
BA_ "CI_MsgId" BO_ 2561129802 14303;
BA_ "CI_MsgDefinition" BO_ 2561129802 "Iveco Bus Proprietary";
BA_ "GenMsgStartDelayTime" BO_ 2561130314 32;
BA_ "GenMsgSendType" BO_ 2561130314 0;
BA_ "GenMsgDelayTime" BO_ 2561130314 500;
BA_ "GenMsgCycleTimeFast" BO_ 2561130314 1000;
BA_ "GenMsgCycleTime" BO_ 2561130314 1000;
BA_ "CI_MsgName" BO_ 2561130314 "DSE_DAS - DSE Das";
BA_ "CI_MsgId" BO_ 2561130314 14306;
BA_ "CI_MsgDefinition" BO_ 2561130314 "Iveco Bus Proprietary";
BA_ "GenMsgStartDelayTime" BO_ 2561140554 106;
BA_ "GenMsgSendType" BO_ 2561140554 0;
BA_ "GenMsgDelayTime" BO_ 2561140554 500;
BA_ "GenMsgCycleTimeFast" BO_ 2561140554 1000;
BA_ "GenMsgCycleTime" BO_ 2561140554 1000;
BA_ "CI_MsgName" BO_ 2561140554 "DSE_DAS_DBG - DSE DAS DBG";
BA_ "CI_MsgId" BO_ 2561140554 14312;
BA_ "CI_MsgDefinition" BO_ 2561140554 "Iveco Bus Proprietary";
BA_ "GenMsgStartDelayTime" BO_ 2561130570 34;
BA_ "GenMsgSendType" BO_ 2561130570 0;
BA_ "GenMsgDelayTime" BO_ 2561130570 500;
BA_ "GenMsgCycleTimeFast" BO_ 2561130570 1000;
BA_ "GenMsgCycleTime" BO_ 2561130570 1000;
BA_ "CI_MsgName" BO_ 2561130570 "DSE_DEC - DSE Deceleration";
BA_ "CI_MsgId" BO_ 2561130570 14315;
BA_ "CI_MsgDefinition" BO_ 2561130570 "Iveco Bus Proprietary";
BA_ "GenMsgStartDelayTime" BO_ 2561143882 132;
BA_ "GenMsgSendType" BO_ 2561143882 0;
BA_ "GenMsgDelayTime" BO_ 2561143882 500;
BA_ "GenMsgCycleTimeFast" BO_ 2561143882 1000;
BA_ "GenMsgCycleTime" BO_ 2561143882 1000;
BA_ "CI_MsgName" BO_ 2561143882 "DSE_DRIVERAWARE - DSE Driver Awareness";
BA_ "CI_MsgId" BO_ 2561143882 14321;
BA_ "CI_MsgDefinition" BO_ 2561143882 "Iveco Bus Proprietary";
BA_ "GenMsgStartDelayTime" BO_ 2561130826 36;
BA_ "GenMsgSendType" BO_ 2561130826 0;
BA_ "GenMsgDelayTime" BO_ 2561130826 500;
BA_ "GenMsgCycleTimeFast" BO_ 2561130826 1000;
BA_ "GenMsgCycleTime" BO_ 2561130826 1000;
BA_ "CI_MsgName" BO_ 2561130826 "DSE_ECO - DSE EcoMode";
BA_ "CI_MsgId" BO_ 2561130826 14327;
BA_ "CI_MsgDefinition" BO_ 2561130826 "Iveco Bus Proprietary";
BA_ "GenMsgStartDelayTime" BO_ 2561131082 38;
BA_ "GenMsgSendType" BO_ 2561131082 0;
BA_ "GenMsgDelayTime" BO_ 2561131082 500;
BA_ "GenMsgCycleTimeFast" BO_ 2561131082 1000;
BA_ "GenMsgCycleTime" BO_ 2561131082 1000;
BA_ "CI_MsgName" BO_ 2561131082 "DSE_ECO_DBG - DSE EcoMode DBG";
BA_ "CI_MsgId" BO_ 2561131082 14333;
BA_ "CI_MsgDefinition" BO_ 2561131082 "Iveco Bus Proprietary";
BA_ "GenMsgStartDelayTime" BO_ 2561131338 40;
BA_ "GenMsgSendType" BO_ 2561131338 0;
BA_ "GenMsgDelayTime" BO_ 2561131338 500;
BA_ "GenMsgCycleTimeFast" BO_ 2561131338 1000;
BA_ "GenMsgCycleTime" BO_ 2561131338 1000;
BA_ "CI_MsgName" BO_ 2561131338 "DSE_ENG - DSE Engine Use";
BA_ "CI_MsgId" BO_ 2561131338 14335;
BA_ "CI_MsgDefinition" BO_ 2561131338 "Iveco Bus Proprietary";
BA_ "GenMsgStartDelayTime" BO_ 2561140810 108;
BA_ "GenMsgSendType" BO_ 2561140810 0;
BA_ "GenMsgDelayTime" BO_ 2561140810 500;
BA_ "GenMsgCycleTimeFast" BO_ 2561140810 1000;
BA_ "GenMsgCycleTime" BO_ 2561140810 1000;
BA_ "CI_MsgName" BO_ 2561140810 "DSE_EVAL - DSE Evaluated Trip";
BA_ "CI_MsgId" BO_ 2561140810 14341;
BA_ "CI_MsgDefinition" BO_ 2561140810 "Iveco Bus Proprietary";
BA_ "GenMsgSendType" BO_ 2561131594 0;
BA_ "GenMsgDelayTime" BO_ 2561131594 250;
BA_ "GenMsgCycleTimeFast" BO_ 2561131594 500;
BA_ "GenMsgCycleTime" BO_ 2561131594 500;
BA_ "CI_MsgName" BO_ 2561131594 "DSE_FUEL - DSE Fuel";
BA_ "CI_MsgId" BO_ 2561131594 1906;
BA_ "CI_MsgDefinition" BO_ 2561131594 "Iveco Bus Proprietary";
BA_ "GenMsgStartDelayTime" BO_ 2561141834 116;
BA_ "GenMsgSendType" BO_ 2561141834 0;
BA_ "GenMsgDelayTime" BO_ 2561141834 500;
BA_ "GenMsgCycleTimeFast" BO_ 2561141834 1000;
BA_ "GenMsgCycleTime" BO_ 2561141834 1000;
BA_ "CI_MsgName" BO_ 2561141834 "DSE_FUEL_CONSP - DSE Fuel Consumption";
BA_ "CI_MsgId" BO_ 2561141834 14344;
BA_ "CI_MsgDefinition" BO_ 2561141834 "Iveco Bus Proprietary";
BA_ "GenMsgStartDelayTime" BO_ 2561131850 42;
BA_ "GenMsgSendType" BO_ 2561131850 0;
BA_ "GenMsgDelayTime" BO_ 2561131850 500;
BA_ "GenMsgCycleTimeFast" BO_ 2561131850 1000;
BA_ "GenMsgCycleTime" BO_ 2561131850 1000;
BA_ "CI_MsgName" BO_ 2561131850 "DSE_GPSIN - DSE GPSIN";
BA_ "CI_MsgId" BO_ 2561131850 14349;
BA_ "CI_MsgDefinition" BO_ 2561131850 "Iveco Bus Proprietary";
BA_ "GenMsgStartDelayTime" BO_ 2561132106 44;
BA_ "GenMsgSendType" BO_ 2561132106 0;
BA_ "GenMsgDelayTime" BO_ 2561132106 500;
BA_ "GenMsgCycleTimeFast" BO_ 2561132106 1000;
BA_ "GenMsgCycleTime" BO_ 2561132106 1000;
BA_ "CI_MsgName" BO_ 2561132106 "DSE_HNBK - DSE Hand Brake";
BA_ "CI_MsgId" BO_ 2561132106 14356;
BA_ "CI_MsgDefinition" BO_ 2561132106 "Iveco Bus Proprietary";
BA_ "GenMsgStartDelayTime" BO_ 2561132362 46;
BA_ "GenMsgSendType" BO_ 2561132362 0;
BA_ "GenMsgDelayTime" BO_ 2561132362 500;
BA_ "GenMsgCycleTimeFast" BO_ 2561132362 1000;
BA_ "GenMsgCycleTime" BO_ 2561132362 1000;
BA_ "CI_MsgName" BO_ 2561132362 "DSE_HNBK_DBG - DSE Hand Brake DBG";
BA_ "CI_MsgId" BO_ 2561132362 14362;
BA_ "CI_MsgDefinition" BO_ 2561132362 "Iveco Bus Proprietary";
BA_ "GenMsgStartDelayTime" BO_ 2561132618 48;
BA_ "GenMsgSendType" BO_ 2561132618 0;
BA_ "GenMsgDelayTime" BO_ 2561132618 500;
BA_ "GenMsgCycleTimeFast" BO_ 2561132618 1000;
BA_ "GenMsgCycleTime" BO_ 2561132618 1000;
BA_ "CI_MsgName" BO_ 2561132618 "DSE_HRBK - DSE HarshBraking";
BA_ "CI_MsgId" BO_ 2561132618 14365;
BA_ "CI_MsgDefinition" BO_ 2561132618 "Iveco Bus Proprietary";
BA_ "GenMsgStartDelayTime" BO_ 2561132874 50;
BA_ "GenMsgSendType" BO_ 2561132874 0;
BA_ "GenMsgDelayTime" BO_ 2561132874 500;
BA_ "GenMsgCycleTimeFast" BO_ 2561132874 1000;
BA_ "GenMsgCycleTime" BO_ 2561132874 1000;
BA_ "CI_MsgName" BO_ 2561132874 "DSE_HRBK_DBG - DSE HarshBraking DBG";
BA_ "CI_MsgId" BO_ 2561132874 14371;
BA_ "CI_MsgDefinition" BO_ 2561132874 "Iveco Bus Proprietary";
BA_ "GenMsgStartDelayTime" BO_ 2561133130 52;
BA_ "GenMsgSendType" BO_ 2561133130 0;
BA_ "GenMsgDelayTime" BO_ 2561133130 500;
BA_ "GenMsgCycleTimeFast" BO_ 2561133130 1000;
BA_ "GenMsgCycleTime" BO_ 2561133130 1000;
BA_ "CI_MsgName" BO_ 2561133130 "DSE_HRSTR - DSE Harsh Steeering";
BA_ "CI_MsgId" BO_ 2561133130 14375;
BA_ "CI_MsgDefinition" BO_ 2561133130 "Iveco Bus Proprietary";
BA_ "GenMsgStartDelayTime" BO_ 2561133386 54;
BA_ "GenMsgSendType" BO_ 2561133386 0;
BA_ "GenMsgDelayTime" BO_ 2561133386 500;
BA_ "GenMsgCycleTimeFast" BO_ 2561133386 1000;
BA_ "GenMsgCycleTime" BO_ 2561133386 1000;
BA_ "CI_MsgName" BO_ 2561133386 "DSE_HRSTR_DBG - DSE Harsh Steeering DBG";
BA_ "CI_MsgId" BO_ 2561133386 14381;
BA_ "CI_MsgDefinition" BO_ 2561133386 "Iveco Bus Proprietary";
BA_ "GenMsgStartDelayTime" BO_ 2561133898 56;
BA_ "GenMsgSendType" BO_ 2561133898 0;
BA_ "GenMsgDelayTime" BO_ 2561133898 500;
BA_ "GenMsgCycleTimeFast" BO_ 2561133898 1000;
BA_ "GenMsgCycleTime" BO_ 2561133898 1000;
BA_ "CI_MsgName" BO_ 2561133898 "DSE_INE - DSE Inertia";
BA_ "CI_MsgId" BO_ 2561133898 14384;
BA_ "CI_MsgDefinition" BO_ 2561133898 "Iveco Bus Proprietary";
BA_ "GenMsgStartDelayTime" BO_ 2561134154 58;
BA_ "GenMsgSendType" BO_ 2561134154 0;
BA_ "GenMsgDelayTime" BO_ 2561134154 500;
BA_ "GenMsgCycleTimeFast" BO_ 2561134154 1000;
BA_ "GenMsgCycleTime" BO_ 2561134154 1000;
BA_ "CI_MsgName" BO_ 2561134154 "DSE_INE_DBG - DSE Inertia DBG";
BA_ "CI_MsgId" BO_ 2561134154 14390;
BA_ "CI_MsgDefinition" BO_ 2561134154 "Iveco Bus Proprietary";
BA_ "GenMsgStartDelayTime" BO_ 2561134410 60;
BA_ "GenMsgSendType" BO_ 2561134410 0;
BA_ "GenMsgDelayTime" BO_ 2561134410 500;
BA_ "GenMsgCycleTimeFast" BO_ 2561134410 1000;
BA_ "GenMsgCycleTime" BO_ 2561134410 1000;
BA_ "CI_MsgName" BO_ 2561134410 "DSE_INEPECC - DSE Inertia Pecc";
BA_ "CI_MsgId" BO_ 2561134410 14400;
BA_ "CI_MsgDefinition" BO_ 2561134410 "Iveco Bus Proprietary";
BA_ "SPN" SG_ 2566844672 CcSts 527;
BA_ "GenSigTimeoutTime_SGW2" SG_ 2566844672 CcSts 500;
BA_ "GenSigTimeoutTime_SGW" SG_ 2566844672 CcSts 500;
BA_ "GenSigTimeoutTime_RM_IRCS" SG_ 2566844672 CcSts 500;
BA_ "GenSigTimeoutTime_PCM" SG_ 2566844672 CcSts 500;
BA_ "GenSigTimeoutTime_MPPxPTFE2" SG_ 2566844672 CcSts 500;
BA_ "GenSigTimeoutTime_IC_MulticS" SG_ 2566844672 CcSts 500;
BA_ "GenSigTimeoutTime_FMS_FMS5" SG_ 2566844672 CcSts 500;
BA_ "GenSigTimeoutTime_FMS_FMS4" SG_ 2566844672 CcSts 500;
BA_ "GenSigTimeoutTime_ADCU" SG_ 2566844672 CcSts 500;
BA_ "CI_SigName" SG_ 2566844672 CcSts "Cruise Control States";
BA_ "CI_SigId" SG_ 2566844672 CcSts 2095;
BA_ "CI_ParId" SG_ 2566844672 CcSts "527";
BA_ "SPN" SG_ 2566844672 PtoGovSts 976;
BA_ "GenSigTimeoutTime_SGW2" SG_ 2566844672 PtoGovSts 500;
BA_ "GenSigTimeoutTime_SGW" SG_ 2566844672 PtoGovSts 500;
BA_ "GenSigTimeoutTime_PCM" SG_ 2566844672 PtoGovSts 500;
BA_ "GenSigTimeoutTime_IC_MulticS" SG_ 2566844672 PtoGovSts 500;
BA_ "GenSigTimeoutTime_FMS_FMS5" SG_ 2566844672 PtoGovSts 500;
BA_ "GenSigTimeoutTime_FMS_FMS4" SG_ 2566844672 PtoGovSts 500;
BA_ "CI_SigName" SG_ 2566844672 PtoGovSts "PTO Governor State";
BA_ "CI_SigId" SG_ 2566844672 PtoGovSts 2094;
BA_ "CI_ParId" SG_ 2566844672 PtoGovSts "976";
BA_ "SigType" SG_ 2566844672 CcSetSpeed 1;
BA_ "SPN" SG_ 2566844672 CcSetSpeed 86;
BA_ "GenSigTimeoutTime_SGW2" SG_ 2566844672 CcSetSpeed 500;
BA_ "GenSigTimeoutTime_SGW" SG_ 2566844672 CcSetSpeed 500;
BA_ "GenSigTimeoutTime_PCM" SG_ 2566844672 CcSetSpeed 500;
BA_ "GenSigTimeoutTime_IC_MulticS" SG_ 2566844672 CcSetSpeed 500;
BA_ "GenSigTimeoutTime_ADCU" SG_ 2566844672 CcSetSpeed 500;
BA_ "CI_SigName" SG_ 2566844672 CcSetSpeed "Cruise Control Set Speed";
BA_ "CI_SigId" SG_ 2566844672 CcSetSpeed 2093;
BA_ "CI_ParId" SG_ 2566844672 CcSetSpeed "86";
BA_ "SigType" SG_ 2566844672 CltSw 4;
BA_ "SPN" SG_ 2566844672 CltSw 598;
BA_ "GenSigTimeoutTime_SGW2" SG_ 2566844672 CltSw 500;
BA_ "GenSigTimeoutTime_SGW" SG_ 2566844672 CltSw 500;
BA_ "GenSigTimeoutTime_PCM" SG_ 2566844672 CltSw 500;
BA_ "GenSigTimeoutTime_FMS_FMS5" SG_ 2566844672 CltSw 500;
BA_ "GenSigTimeoutTime_FMS_FMS4" SG_ 2566844672 CltSw 500;
BA_ "GenSigTimeoutTime_BSM_EBS" SG_ 2566844672 CltSw 500;
BA_ "GenSigTimeoutTime_BCM_NBM" SG_ 2566844672 CltSw 500;
BA_ "GenSigTimeoutTime_ADCU" SG_ 2566844672 CltSw 500;
BA_ "CI_SigName" SG_ 2566844672 CltSw "Clutch Switch";
BA_ "CI_SigId" SG_ 2566844672 CltSw 2088;
BA_ "CI_ParId" SG_ 2566844672 CltSw "598";
BA_ "SigType" SG_ 2566844672 BrkSw 4;
BA_ "SPN" SG_ 2566844672 BrkSw 597;
BA_ "GenSigTimeoutTime_SGW2" SG_ 2566844672 BrkSw 500;
BA_ "GenSigTimeoutTime_SGW" SG_ 2566844672 BrkSw 500;
BA_ "GenSigTimeoutTime_RM_IRCS" SG_ 2566844672 BrkSw 500;
BA_ "GenSigTimeoutTime_PCM" SG_ 2566844672 BrkSw 500;
BA_ "GenSigTimeoutTime_MPPxPTFE2" SG_ 2566844672 BrkSw 500;
BA_ "GenSigTimeoutTime_FMS_FMS5" SG_ 2566844672 BrkSw 500;
BA_ "GenSigTimeoutTime_FMS_FMS4" SG_ 2566844672 BrkSw 500;
BA_ "GenSigTimeoutTime_ETC_Ecolife2" SG_ 2566844672 BrkSw 500;
BA_ "GenSigTimeoutTime_BCM_NBM" SG_ 2566844672 BrkSw 500;
BA_ "GenSigTimeoutTime_ADCU" SG_ 2566844672 BrkSw 500;
BA_ "CI_SigName" SG_ 2566844672 BrkSw "Brake Switch";
BA_ "CI_SigId" SG_ 2566844672 BrkSw 2087;
BA_ "CI_ParId" SG_ 2566844672 BrkSw "597";
BA_ "SigType" SG_ 2566844672 CcActv 4;
BA_ "SPN" SG_ 2566844672 CcActv 595;
BA_ "GenSigTimeoutTime_SGW2" SG_ 2566844672 CcActv 500;
BA_ "GenSigTimeoutTime_SGW" SG_ 2566844672 CcActv 500;
BA_ "GenSigTimeoutTime_RM_IRCS" SG_ 2566844672 CcActv 500;
BA_ "GenSigTimeoutTime_PCM" SG_ 2566844672 CcActv 500;
BA_ "GenSigTimeoutTime_MPPxPTFE2" SG_ 2566844672 CcActv 500;
BA_ "GenSigTimeoutTime_IC_MulticS" SG_ 2566844672 CcActv 500;
BA_ "GenSigTimeoutTime_FMS_FMS5" SG_ 2566844672 CcActv 500;
BA_ "GenSigTimeoutTime_FMS_FMS4" SG_ 2566844672 CcActv 500;
BA_ "GenSigTimeoutTime_ETC_Ecolife2" SG_ 2566844672 CcActv 500;
BA_ "GenSigTimeoutTime_BSM_EBS" SG_ 2566844672 CcActv 500;
BA_ "GenSigTimeoutTime_BCM_NBM" SG_ 2566844672 CcActv 500;
BA_ "GenSigTimeoutTime_ADCU" SG_ 2566844672 CcActv 500;
BA_ "CI_SigName" SG_ 2566844672 CcActv "Cruise Control Active";
BA_ "CI_SigId" SG_ 2566844672 CcActv 2085;
BA_ "CI_ParId" SG_ 2566844672 CcActv "595";
BA_ "SigType" SG_ 2566844672 WhBasedVehSpeed 1;
BA_ "SPN" SG_ 2566844672 WhBasedVehSpeed 84;
BA_ "GenSigTimeoutTime_SGW2" SG_ 2566844672 WhBasedVehSpeed 500;
BA_ "GenSigTimeoutTime_SGW" SG_ 2566844672 WhBasedVehSpeed 500;
BA_ "GenSigTimeoutTime_SAS" SG_ 2566844672 WhBasedVehSpeed 500;
BA_ "GenSigTimeoutTime_RM_IRCS" SG_ 2566844672 WhBasedVehSpeed 500;
BA_ "GenSigTimeoutTime_RDAB_SmtRadio" SG_ 2566844672 WhBasedVehSpeed 500;
BA_ "GenSigTimeoutTime_PCM" SG_ 2566844672 WhBasedVehSpeed 500;
BA_ "GenSigTimeoutTime_MPPxPTFE2" SG_ 2566844672 WhBasedVehSpeed 500;
BA_ "GenSigTimeoutTime_MBMS" SG_ 2566844672 WhBasedVehSpeed 500;
BA_ "GenSigTimeoutTime_FMS_FMS5" SG_ 2566844672 WhBasedVehSpeed 500;
BA_ "GenSigTimeoutTime_FMS_FMS4" SG_ 2566844672 WhBasedVehSpeed 500;
BA_ "GenSigTimeoutTime_ETC_Ecolife2" SG_ 2566844672 WhBasedVehSpeed 500;
BA_ "GenSigTimeoutTime_DMS" SG_ 2566844672 WhBasedVehSpeed 500;
BA_ "GenSigTimeoutTime_BSM_EBS" SG_ 2566844672 WhBasedVehSpeed 500;
BA_ "GenSigTimeoutTime_Av2HP" SG_ 2566844672 WhBasedVehSpeed 500;
BA_ "GenSigTimeoutTime_AVAS" SG_ 2566844672 WhBasedVehSpeed 500;
BA_ "GenSigTimeoutTime_ASM_ELC5_Fr" SG_ 2566844672 WhBasedVehSpeed 500;
BA_ "GenSigTimeoutTime_ADCU" SG_ 2566844672 WhBasedVehSpeed 500;
BA_ "GenSigTimeoutTime_ACM_CANAIR" SG_ 2566844672 WhBasedVehSpeed 500;
BA_ "CI_SigName" SG_ 2566844672 WhBasedVehSpeed "Wheel-Based Vehicle Speed";
BA_ "CI_SigId" SG_ 2566844672 WhBasedVehSpeed 2084;
BA_ "CI_ParId" SG_ 2566844672 WhBasedVehSpeed "84";
BA_ "SigType" SG_ 2566844672 ParkBrkSw 4;
BA_ "SPN" SG_ 2566844672 ParkBrkSw 70;
BA_ "GenSigTimeoutTime_SGW2" SG_ 2566844672 ParkBrkSw 500;
BA_ "GenSigTimeoutTime_SGW" SG_ 2566844672 ParkBrkSw 500;
BA_ "GenSigTimeoutTime_RDAB_SmtRadio" SG_ 2566844672 ParkBrkSw 500;
BA_ "GenSigTimeoutTime_PCM" SG_ 2566844672 ParkBrkSw 500;
BA_ "GenSigTimeoutTime_MPPxPTFE2" SG_ 2566844672 ParkBrkSw 500;
BA_ "GenSigTimeoutTime_IC_MulticS" SG_ 2566844672 ParkBrkSw 500;
BA_ "GenSigTimeoutTime_FMS_FMS5" SG_ 2566844672 ParkBrkSw 500;
BA_ "GenSigTimeoutTime_FMS_FMS4" SG_ 2566844672 ParkBrkSw 500;
BA_ "GenSigTimeoutTime_ETC_Ecolife2" SG_ 2566844672 ParkBrkSw 500;
BA_ "GenSigTimeoutTime_BSM_EBS" SG_ 2566844672 ParkBrkSw 500;
BA_ "GenSigTimeoutTime_BCM_NBM" SG_ 2566844672 ParkBrkSw 500;
BA_ "GenSigTimeoutTime_ADCU" SG_ 2566844672 ParkBrkSw 500;
BA_ "GenSigTimeoutTime_ACM_CANAIR" SG_ 2566844672 ParkBrkSw 500;
BA_ "CI_SigName" SG_ 2566844672 ParkBrkSw "Parking Brake Switch";
BA_ "CI_SigId" SG_ 2566844672 ParkBrkSw 2082;
BA_ "CI_ParId" SG_ 2566844672 ParkBrkSw "70";
BA_ "GenSigTimeoutTime_SGW" SG_ 2566890313 BefLastStopCause 25000;
BA_ "GenSigTimeoutTime_PCM" SG_ 2566890313 BefLastStopCause 25000;
BA_ "GenSigTimeoutTime_IC_MulticS" SG_ 2566890313 BefLastStopCause 25000;
BA_ "GenSigTimeoutTime_IC_MulticII" SG_ 2566890313 BefLastStopCause 25000;
BA_ "CI_SigName" SG_ 2566890313 BefLastStopCause "Before Last Stop Cause";
BA_ "CI_SigId" SG_ 2566890313 BefLastStopCause 1405;
BA_ "CI_ParId" SG_ 2566890313 BefLastStopCause "IB127";
BA_ "GenSigTimeoutTime_SGW" SG_ 2566890313 LastStopCause 25000;
BA_ "GenSigTimeoutTime_PCM" SG_ 2566890313 LastStopCause 25000;
BA_ "GenSigTimeoutTime_IC_MulticS" SG_ 2566890313 LastStopCause 25000;
BA_ "GenSigTimeoutTime_IC_MulticII" SG_ 2566890313 LastStopCause 25000;
BA_ "CI_SigName" SG_ 2566890313 LastStopCause "Last Stop Cause";
BA_ "CI_SigId" SG_ 2566890313 LastStopCause 1404;
BA_ "CI_ParId" SG_ 2566890313 LastStopCause "IB126";
BA_ "SigType" SG_ 2566843165 UnitNumPwrUnit 8;
BA_ "SPN" SG_ 2566843165 UnitNumPwrUnit 233;
BA_ "CI_SigName" SG_ 2566843165 UnitNumPwrUnit "Unit Number (Power Unit)";
BA_ "CI_SigId" SG_ 2566843165 UnitNumPwrUnit 10386;
BA_ "CI_ParId" SG_ 2566843165 UnitNumPwrUnit "233";
BA_ "SigType" SG_ 2566843165 Sn 8;
BA_ "SPN" SG_ 2566843165 Sn 588;
BA_ "CI_SigName" SG_ 2566843165 Sn "Serial Number";
BA_ "CI_SigId" SG_ 2566843165 Sn 10385;
BA_ "CI_ParId" SG_ 2566843165 Sn "588";
BA_ "SigType" SG_ 2566843165 Model 8;
BA_ "SPN" SG_ 2566843165 Model 587;
BA_ "CI_SigName" SG_ 2566843165 Model "Model";
BA_ "CI_SigId" SG_ 2566843165 Model 10384;
BA_ "CI_ParId" SG_ 2566843165 Model "587";
BA_ "SigType" SG_ 2566843165 Make 8;
BA_ "SPN" SG_ 2566843165 Make 586;
BA_ "CI_SigName" SG_ 2566843165 Make "Make";
BA_ "CI_SigId" SG_ 2566843165 Make 10383;
BA_ "CI_ParId" SG_ 2566843165 Make "586";
BA_ "SigType" SG_ 2566843230 Model_FEEB5E 8;
BA_ "SPN" SG_ 2566843230 Model_FEEB5E 587;
BA_ "CI_SigName" SG_ 2566843230 Model_FEEB5E "Model";
BA_ "CI_SigId" SG_ 2566843230 Model_FEEB5E 10399;
BA_ "CI_ParId" SG_ 2566843230 Model_FEEB5E "587";
BA_ "GenSigTimeoutTime_SGW" SG_ 2566865139 CoolSts 25000;
BA_ "GenSigTimeoutTime_PCM" SG_ 2566865139 CoolSts 25000;
BA_ "GenSigTimeoutTime_IC_MulticS" SG_ 2566865139 CoolSts 25000;
BA_ "GenSigTimeoutTime_IC_MulticII" SG_ 2566865139 CoolSts 25000;
BA_ "GenSigTimeoutTime_BCM_NBM" SG_ 2566865139 CoolSts 25000;
BA_ "CI_SigName" SG_ 2566865139 CoolSts "Cooling state";
BA_ "CI_SigId" SG_ 2566865139 CoolSts 3883;
BA_ "CI_ParId" SG_ 2566865139 CoolSts "IB530";
BA_ "SigType" SG_ 2566811659 Gcvw 1;
BA_ "SPN" SG_ 2566811659 Gcvw 1760;
BA_ "GenSigTimeoutTime_SGW" SG_ 2566811659 Gcvw 5000;
BA_ "GenSigTimeoutTime_PCM" SG_ 2566811659 Gcvw 5000;
BA_ "GenSigTimeoutTime_FMS_FMS5" SG_ 2566811659 Gcvw 5000;
BA_ "GenSigTimeoutTime_FMS_FMS4" SG_ 2566811659 Gcvw 5000;
BA_ "GenSigTimeoutTime_ETC_Ecolife2" SG_ 2566811659 Gcvw 5000;
BA_ "GenSigTimeoutTime_ADCU" SG_ 2566811659 Gcvw 5000;
BA_ "CI_SigName" SG_ 2566811659 Gcvw "Gross Combination Vehicle Weight";
BA_ "CI_SigId" SG_ 2566811659 Gcvw 391;
BA_ "CI_ParId" SG_ 2566811659 Gcvw "1760";
BA_ "SigType" SG_ 2566802967 Sts2OfDoors 4;
BA_ "SPN" SG_ 2566802967 Sts2OfDoors 3411;
BA_ "GenSigTimeoutTime_SGW" SG_ 2566802967 Sts2OfDoors 500;
BA_ "GenSigTimeoutTime_PCM" SG_ 2566802967 Sts2OfDoors 500;
BA_ "GenSigTimeoutTime_MPPxPTFE2" SG_ 2566802967 Sts2OfDoors 500;
BA_ "GenSigTimeoutTime_FMS_FMS5" SG_ 2566802967 Sts2OfDoors 500;
BA_ "GenSigTimeoutTime_FMS_FMS4" SG_ 2566802967 Sts2OfDoors 500;
BA_ "CI_SigName" SG_ 2566802967 Sts2OfDoors "Status 2 of doors";
BA_ "CI_SigId" SG_ 2566802967 Sts2OfDoors 3270;
BA_ "CI_ParId" SG_ 2566802967 Sts2OfDoors "3411";
BA_ "SigType" SG_ 2566802967 Ramp_WhChairLiftPos 4;
BA_ "SPN" SG_ 2566802967 Ramp_WhChairLiftPos 1820;
BA_ "GenSigTimeoutTime_SGW" SG_ 2566802967 Ramp_WhChairLiftPos 500;
BA_ "GenSigTimeoutTime_PCM" SG_ 2566802967 Ramp_WhChairLiftPos 500;
BA_ "GenSigTimeoutTime_MPPxPTFE2" SG_ 2566802967 Ramp_WhChairLiftPos 500;
BA_ "GenSigTimeoutTime_FMS_FMS5" SG_ 2566802967 Ramp_WhChairLiftPos 500;
BA_ "GenSigTimeoutTime_FMS_FMS4" SG_ 2566802967 Ramp_WhChairLiftPos 500;
BA_ "CI_SigName" SG_ 2566802967 Ramp_WhChairLiftPos "Ramp / Wheel Chair Lift Position";
BA_ "CI_SigId" SG_ 2566802967 Ramp_WhChairLiftPos 3269;
BA_ "CI_ParId" SG_ 2566802967 Ramp_WhChairLiftPos "1820";
BA_ "SPN" SG_ 2566802967 PosOfDoors 1821;
BA_ "GenSigTimeoutTime_SGW" SG_ 2566802967 PosOfDoors 500;
BA_ "GenSigTimeoutTime_PCM" SG_ 2566802967 PosOfDoors 500;
BA_ "GenSigTimeoutTime_MPPxPTFE2" SG_ 2566802967 PosOfDoors 500;
BA_ "GenSigTimeoutTime_FMS_FMS5" SG_ 2566802967 PosOfDoors 500;
BA_ "GenSigTimeoutTime_FMS_FMS4" SG_ 2566802967 PosOfDoors 500;
BA_ "GenSigTimeoutTime_ADCU" SG_ 2566802967 PosOfDoors 500;
BA_ "CI_SigName" SG_ 2566802967 PosOfDoors "Position of doors";
BA_ "CI_SigId" SG_ 2566802967 PosOfDoors 3268;
BA_ "CI_ParId" SG_ 2566802967 PosOfDoors "1821";
BA_ "SigType" SG_ 2566759703 EnaStsOfDoor10 4;
BA_ "SPN" SG_ 2566759703 EnaStsOfDoor10 3441;
BA_ "GenSigTimeoutTime_SGW" SG_ 2566759703 EnaStsOfDoor10 500;
BA_ "GenSigTimeoutTime_PCM" SG_ 2566759703 EnaStsOfDoor10 500;
BA_ "CI_SigName" SG_ 2566759703 EnaStsOfDoor10 "Enable Status of Door 10";
BA_ "CI_SigId" SG_ 2566759703 EnaStsOfDoor10 3301;
BA_ "CI_ParId" SG_ 2566759703 EnaStsOfDoor10 "3441";
BA_ "SigType" SG_ 2566759703 OpenStsOfDoor10 4;
BA_ "SPN" SG_ 2566759703 OpenStsOfDoor10 3440;
BA_ "GenSigTimeoutTime_SGW" SG_ 2566759703 OpenStsOfDoor10 500;
BA_ "GenSigTimeoutTime_PCM" SG_ 2566759703 OpenStsOfDoor10 500;
BA_ "CI_SigName" SG_ 2566759703 OpenStsOfDoor10 "Open Status of Door 10";
BA_ "CI_SigId" SG_ 2566759703 OpenStsOfDoor10 3300;
BA_ "CI_ParId" SG_ 2566759703 OpenStsOfDoor10 "3440";
BA_ "SigType" SG_ 2566759703 LckStsOfDoor10 4;
BA_ "SPN" SG_ 2566759703 LckStsOfDoor10 3439;
BA_ "GenSigTimeoutTime_SGW" SG_ 2566759703 LckStsOfDoor10 500;
BA_ "GenSigTimeoutTime_PCM" SG_ 2566759703 LckStsOfDoor10 500;
BA_ "CI_SigName" SG_ 2566759703 LckStsOfDoor10 "Lock Status of Door 10";
BA_ "CI_SigId" SG_ 2566759703 LckStsOfDoor10 3299;
BA_ "CI_ParId" SG_ 2566759703 LckStsOfDoor10 "3439";
BA_ "SigType" SG_ 2566759703 EnaStsOfDoor9 4;
BA_ "SPN" SG_ 2566759703 EnaStsOfDoor9 3438;
BA_ "GenSigTimeoutTime_SGW" SG_ 2566759703 EnaStsOfDoor9 500;
BA_ "GenSigTimeoutTime_PCM" SG_ 2566759703 EnaStsOfDoor9 500;
BA_ "CI_SigName" SG_ 2566759703 EnaStsOfDoor9 "Enable Status of Door 9";
BA_ "CI_SigId" SG_ 2566759703 EnaStsOfDoor9 3298;
BA_ "CI_ParId" SG_ 2566759703 EnaStsOfDoor9 "3438";
BA_ "SigType" SG_ 2566759703 OpenStsOfDoor9 4;
BA_ "SPN" SG_ 2566759703 OpenStsOfDoor9 3437;
BA_ "GenSigTimeoutTime_SGW" SG_ 2566759703 OpenStsOfDoor9 500;
BA_ "GenSigTimeoutTime_PCM" SG_ 2566759703 OpenStsOfDoor9 500;
BA_ "CI_SigName" SG_ 2566759703 OpenStsOfDoor9 "Open Status of Door 9";
BA_ "CI_SigId" SG_ 2566759703 OpenStsOfDoor9 3297;
BA_ "CI_ParId" SG_ 2566759703 OpenStsOfDoor9 "3437";
BA_ "SigType" SG_ 2566759703 LckStsOfDoor9 4;
BA_ "SPN" SG_ 2566759703 LckStsOfDoor9 3436;
BA_ "GenSigTimeoutTime_SGW" SG_ 2566759703 LckStsOfDoor9 500;
BA_ "GenSigTimeoutTime_PCM" SG_ 2566759703 LckStsOfDoor9 500;
BA_ "CI_SigName" SG_ 2566759703 LckStsOfDoor9 "Lock Status of Door 9";
BA_ "CI_SigId" SG_ 2566759703 LckStsOfDoor9 3296;
BA_ "CI_ParId" SG_ 2566759703 LckStsOfDoor9 "3436";
BA_ "SigType" SG_ 2566759703 EnaStsOfDoor8 4;
BA_ "SPN" SG_ 2566759703 EnaStsOfDoor8 3435;
BA_ "GenSigTimeoutTime_SGW" SG_ 2566759703 EnaStsOfDoor8 500;
BA_ "GenSigTimeoutTime_PCM" SG_ 2566759703 EnaStsOfDoor8 500;
BA_ "CI_SigName" SG_ 2566759703 EnaStsOfDoor8 "Enable Status of Door 8";
BA_ "CI_SigId" SG_ 2566759703 EnaStsOfDoor8 3295;
BA_ "CI_ParId" SG_ 2566759703 EnaStsOfDoor8 "3435";
BA_ "SigType" SG_ 2566759703 OpenStsOfDoor8 4;
BA_ "SPN" SG_ 2566759703 OpenStsOfDoor8 3434;
BA_ "GenSigTimeoutTime_SGW" SG_ 2566759703 OpenStsOfDoor8 500;
BA_ "GenSigTimeoutTime_PCM" SG_ 2566759703 OpenStsOfDoor8 500;
BA_ "CI_SigName" SG_ 2566759703 OpenStsOfDoor8 "Open Status of Door 8";
BA_ "CI_SigId" SG_ 2566759703 OpenStsOfDoor8 3294;
BA_ "CI_ParId" SG_ 2566759703 OpenStsOfDoor8 "3434";
BA_ "SigType" SG_ 2566759703 LckStsOfDoor8 4;
BA_ "SPN" SG_ 2566759703 LckStsOfDoor8 3433;
BA_ "GenSigTimeoutTime_SGW" SG_ 2566759703 LckStsOfDoor8 500;
BA_ "GenSigTimeoutTime_PCM" SG_ 2566759703 LckStsOfDoor8 500;
BA_ "CI_SigName" SG_ 2566759703 LckStsOfDoor8 "Lock Status of Door 8";
BA_ "CI_SigId" SG_ 2566759703 LckStsOfDoor8 3293;
BA_ "CI_ParId" SG_ 2566759703 LckStsOfDoor8 "3433";
BA_ "SigType" SG_ 2566759703 EnaStsOfDoor7 4;
BA_ "SPN" SG_ 2566759703 EnaStsOfDoor7 3432;
BA_ "GenSigTimeoutTime_SGW" SG_ 2566759703 EnaStsOfDoor7 500;
BA_ "GenSigTimeoutTime_PCM" SG_ 2566759703 EnaStsOfDoor7 500;
BA_ "CI_SigName" SG_ 2566759703 EnaStsOfDoor7 "Enable Status of Door 7";
BA_ "CI_SigId" SG_ 2566759703 EnaStsOfDoor7 3292;
BA_ "CI_ParId" SG_ 2566759703 EnaStsOfDoor7 "3432";
BA_ "SigType" SG_ 2566759703 OpenStsOfDoor7 4;
BA_ "SPN" SG_ 2566759703 OpenStsOfDoor7 3431;
BA_ "GenSigTimeoutTime_SGW" SG_ 2566759703 OpenStsOfDoor7 500;
BA_ "GenSigTimeoutTime_PCM" SG_ 2566759703 OpenStsOfDoor7 500;
BA_ "CI_SigName" SG_ 2566759703 OpenStsOfDoor7 "Open Status of Door 7";
BA_ "CI_SigId" SG_ 2566759703 OpenStsOfDoor7 3291;
BA_ "CI_ParId" SG_ 2566759703 OpenStsOfDoor7 "3431";
BA_ "SigType" SG_ 2566759703 LckStsOfDoor7 4;
BA_ "SPN" SG_ 2566759703 LckStsOfDoor7 3430;
BA_ "GenSigTimeoutTime_SGW" SG_ 2566759703 LckStsOfDoor7 500;
BA_ "GenSigTimeoutTime_PCM" SG_ 2566759703 LckStsOfDoor7 500;
BA_ "CI_SigName" SG_ 2566759703 LckStsOfDoor7 "Lock Status of Door 7";
BA_ "CI_SigId" SG_ 2566759703 LckStsOfDoor7 3290;
BA_ "CI_ParId" SG_ 2566759703 LckStsOfDoor7 "3430";
BA_ "SigType" SG_ 2566759703 EnaStsOfDoor6 4;
BA_ "SPN" SG_ 2566759703 EnaStsOfDoor6 3429;
BA_ "GenSigTimeoutTime_SGW" SG_ 2566759703 EnaStsOfDoor6 500;
BA_ "GenSigTimeoutTime_PCM" SG_ 2566759703 EnaStsOfDoor6 500;
BA_ "CI_SigName" SG_ 2566759703 EnaStsOfDoor6 "Enable Status of Door 6";
BA_ "CI_SigId" SG_ 2566759703 EnaStsOfDoor6 3289;
BA_ "CI_ParId" SG_ 2566759703 EnaStsOfDoor6 "3429";
BA_ "SigType" SG_ 2566759703 OpenStsOfDoor6 4;
BA_ "SPN" SG_ 2566759703 OpenStsOfDoor6 3428;
BA_ "GenSigTimeoutTime_SGW" SG_ 2566759703 OpenStsOfDoor6 500;
BA_ "GenSigTimeoutTime_PCM" SG_ 2566759703 OpenStsOfDoor6 500;
BA_ "CI_SigName" SG_ 2566759703 OpenStsOfDoor6 "Open Status of Door 6";
BA_ "CI_SigId" SG_ 2566759703 OpenStsOfDoor6 3288;
BA_ "CI_ParId" SG_ 2566759703 OpenStsOfDoor6 "3428";
BA_ "SigType" SG_ 2566759703 LckStsOfDoor6 4;
BA_ "SPN" SG_ 2566759703 LckStsOfDoor6 3427;
BA_ "GenSigTimeoutTime_SGW" SG_ 2566759703 LckStsOfDoor6 500;
BA_ "GenSigTimeoutTime_PCM" SG_ 2566759703 LckStsOfDoor6 500;
BA_ "CI_SigName" SG_ 2566759703 LckStsOfDoor6 "Lock Status of Door 6";
BA_ "CI_SigId" SG_ 2566759703 LckStsOfDoor6 3287;
BA_ "CI_ParId" SG_ 2566759703 LckStsOfDoor6 "3427";
BA_ "SigType" SG_ 2566759703 EnaStsOfDoor5 4;
BA_ "SPN" SG_ 2566759703 EnaStsOfDoor5 3426;
BA_ "GenSigTimeoutTime_SGW" SG_ 2566759703 EnaStsOfDoor5 500;
BA_ "GenSigTimeoutTime_PCM" SG_ 2566759703 EnaStsOfDoor5 500;
BA_ "CI_SigName" SG_ 2566759703 EnaStsOfDoor5 "Enable Status of Door 5";
BA_ "CI_SigId" SG_ 2566759703 EnaStsOfDoor5 3286;
BA_ "CI_ParId" SG_ 2566759703 EnaStsOfDoor5 "3426";
BA_ "SigType" SG_ 2566759703 OpenStsOfDoor5 4;
BA_ "SPN" SG_ 2566759703 OpenStsOfDoor5 3425;
BA_ "GenSigTimeoutTime_SGW" SG_ 2566759703 OpenStsOfDoor5 500;
BA_ "GenSigTimeoutTime_PCM" SG_ 2566759703 OpenStsOfDoor5 500;
BA_ "CI_SigName" SG_ 2566759703 OpenStsOfDoor5 "Open Status of Door 5";
BA_ "CI_SigId" SG_ 2566759703 OpenStsOfDoor5 3285;
BA_ "CI_ParId" SG_ 2566759703 OpenStsOfDoor5 "3425";
BA_ "SigType" SG_ 2566759703 LckStsOfDoor5 4;
BA_ "SPN" SG_ 2566759703 LckStsOfDoor5 3424;
BA_ "GenSigTimeoutTime_SGW" SG_ 2566759703 LckStsOfDoor5 500;
BA_ "GenSigTimeoutTime_PCM" SG_ 2566759703 LckStsOfDoor5 500;
BA_ "CI_SigName" SG_ 2566759703 LckStsOfDoor5 "Lock Status of Door 5";
BA_ "CI_SigId" SG_ 2566759703 LckStsOfDoor5 3284;
BA_ "CI_ParId" SG_ 2566759703 LckStsOfDoor5 "3424";
BA_ "SigType" SG_ 2566759703 EnaStsOfDoor4 4;
BA_ "SPN" SG_ 2566759703 EnaStsOfDoor4 3423;
BA_ "GenSigTimeoutTime_SGW" SG_ 2566759703 EnaStsOfDoor4 500;
BA_ "GenSigTimeoutTime_PCM" SG_ 2566759703 EnaStsOfDoor4 500;
BA_ "GenSigTimeoutTime_MPPxPTFE2" SG_ 2566759703 EnaStsOfDoor4 500;
BA_ "GenSigTimeoutTime_FMS_FMS5" SG_ 2566759703 EnaStsOfDoor4 500;
BA_ "GenSigTimeoutTime_FMS_FMS4" SG_ 2566759703 EnaStsOfDoor4 500;
BA_ "CI_SigName" SG_ 2566759703 EnaStsOfDoor4 "Enable Status of Door 4";
BA_ "CI_SigId" SG_ 2566759703 EnaStsOfDoor4 3283;
BA_ "CI_ParId" SG_ 2566759703 EnaStsOfDoor4 "3423";
BA_ "SigType" SG_ 2566759703 OpenStsOfDoor4 4;
BA_ "SPN" SG_ 2566759703 OpenStsOfDoor4 3422;
BA_ "GenSigTimeoutTime_SGW" SG_ 2566759703 OpenStsOfDoor4 500;
BA_ "GenSigTimeoutTime_PCM" SG_ 2566759703 OpenStsOfDoor4 500;
BA_ "GenSigTimeoutTime_MPPxPTFE2" SG_ 2566759703 OpenStsOfDoor4 500;
BA_ "GenSigTimeoutTime_FMS_FMS5" SG_ 2566759703 OpenStsOfDoor4 500;
BA_ "GenSigTimeoutTime_FMS_FMS4" SG_ 2566759703 OpenStsOfDoor4 500;
BA_ "CI_SigName" SG_ 2566759703 OpenStsOfDoor4 "Open Status of Door 4";
BA_ "CI_SigId" SG_ 2566759703 OpenStsOfDoor4 3282;
BA_ "CI_ParId" SG_ 2566759703 OpenStsOfDoor4 "3422";
BA_ "SigType" SG_ 2566759703 LckStsOfDoor4 4;
BA_ "SPN" SG_ 2566759703 LckStsOfDoor4 3421;
BA_ "GenSigTimeoutTime_SGW" SG_ 2566759703 LckStsOfDoor4 500;
BA_ "GenSigTimeoutTime_PCM" SG_ 2566759703 LckStsOfDoor4 500;
BA_ "GenSigTimeoutTime_MPPxPTFE2" SG_ 2566759703 LckStsOfDoor4 500;
BA_ "GenSigTimeoutTime_FMS_FMS5" SG_ 2566759703 LckStsOfDoor4 500;
BA_ "GenSigTimeoutTime_FMS_FMS4" SG_ 2566759703 LckStsOfDoor4 500;
BA_ "CI_SigName" SG_ 2566759703 LckStsOfDoor4 "Lock Status of Door 4";
BA_ "CI_SigId" SG_ 2566759703 LckStsOfDoor4 3281;
BA_ "CI_ParId" SG_ 2566759703 LckStsOfDoor4 "3421";
BA_ "SigType" SG_ 2566759703 EnaStsOfDoor3 4;
BA_ "SPN" SG_ 2566759703 EnaStsOfDoor3 3420;
BA_ "GenSigTimeoutTime_SGW" SG_ 2566759703 EnaStsOfDoor3 500;
BA_ "GenSigTimeoutTime_PCM" SG_ 2566759703 EnaStsOfDoor3 500;
BA_ "GenSigTimeoutTime_MPPxPTFE2" SG_ 2566759703 EnaStsOfDoor3 500;
BA_ "GenSigTimeoutTime_FMS_FMS5" SG_ 2566759703 EnaStsOfDoor3 500;
BA_ "GenSigTimeoutTime_FMS_FMS4" SG_ 2566759703 EnaStsOfDoor3 500;
BA_ "CI_SigName" SG_ 2566759703 EnaStsOfDoor3 "Enable Status of Door 3";
BA_ "CI_SigId" SG_ 2566759703 EnaStsOfDoor3 3280;
BA_ "CI_ParId" SG_ 2566759703 EnaStsOfDoor3 "3420";
BA_ "SigType" SG_ 2566759703 OpenStsOfDoor3 4;
BA_ "SPN" SG_ 2566759703 OpenStsOfDoor3 3419;
BA_ "GenSigTimeoutTime_SGW" SG_ 2566759703 OpenStsOfDoor3 500;
BA_ "GenSigTimeoutTime_PCM" SG_ 2566759703 OpenStsOfDoor3 500;
BA_ "GenSigTimeoutTime_MPPxPTFE2" SG_ 2566759703 OpenStsOfDoor3 500;
BA_ "GenSigTimeoutTime_FMS_FMS5" SG_ 2566759703 OpenStsOfDoor3 500;
BA_ "GenSigTimeoutTime_FMS_FMS4" SG_ 2566759703 OpenStsOfDoor3 500;
BA_ "CI_SigName" SG_ 2566759703 OpenStsOfDoor3 "Open Status of Door 3";
BA_ "CI_SigId" SG_ 2566759703 OpenStsOfDoor3 3279;
BA_ "CI_ParId" SG_ 2566759703 OpenStsOfDoor3 "3419";
BA_ "SigType" SG_ 2566759703 LckStsOfDoor3 4;
BA_ "SPN" SG_ 2566759703 LckStsOfDoor3 3418;
BA_ "GenSigTimeoutTime_SGW" SG_ 2566759703 LckStsOfDoor3 500;
BA_ "GenSigTimeoutTime_PCM" SG_ 2566759703 LckStsOfDoor3 500;
BA_ "GenSigTimeoutTime_MPPxPTFE2" SG_ 2566759703 LckStsOfDoor3 500;
BA_ "GenSigTimeoutTime_FMS_FMS5" SG_ 2566759703 LckStsOfDoor3 500;
BA_ "GenSigTimeoutTime_FMS_FMS4" SG_ 2566759703 LckStsOfDoor3 500;
BA_ "CI_SigName" SG_ 2566759703 LckStsOfDoor3 "Lock Status of Door 3";
BA_ "CI_SigId" SG_ 2566759703 LckStsOfDoor3 3278;
BA_ "CI_ParId" SG_ 2566759703 LckStsOfDoor3 "3418";
BA_ "SigType" SG_ 2566759703 EnaStsOfDoor2 4;
BA_ "SPN" SG_ 2566759703 EnaStsOfDoor2 3417;
BA_ "GenSigTimeoutTime_SGW" SG_ 2566759703 EnaStsOfDoor2 500;
BA_ "GenSigTimeoutTime_PCM" SG_ 2566759703 EnaStsOfDoor2 500;
BA_ "GenSigTimeoutTime_MPPxPTFE2" SG_ 2566759703 EnaStsOfDoor2 500;
BA_ "GenSigTimeoutTime_FMS_FMS5" SG_ 2566759703 EnaStsOfDoor2 500;
BA_ "GenSigTimeoutTime_FMS_FMS4" SG_ 2566759703 EnaStsOfDoor2 500;
BA_ "CI_SigName" SG_ 2566759703 EnaStsOfDoor2 "Enable Status of Door 2";
BA_ "CI_SigId" SG_ 2566759703 EnaStsOfDoor2 3277;
BA_ "CI_ParId" SG_ 2566759703 EnaStsOfDoor2 "3417";
BA_ "SigType" SG_ 2566759703 OpenStsOfDoor2 4;
BA_ "SPN" SG_ 2566759703 OpenStsOfDoor2 3416;
BA_ "GenSigTimeoutTime_SGW" SG_ 2566759703 OpenStsOfDoor2 500;
BA_ "GenSigTimeoutTime_PCM" SG_ 2566759703 OpenStsOfDoor2 500;
BA_ "GenSigTimeoutTime_MPPxPTFE2" SG_ 2566759703 OpenStsOfDoor2 500;
BA_ "GenSigTimeoutTime_FMS_FMS5" SG_ 2566759703 OpenStsOfDoor2 500;
BA_ "GenSigTimeoutTime_FMS_FMS4" SG_ 2566759703 OpenStsOfDoor2 500;
BA_ "CI_SigName" SG_ 2566759703 OpenStsOfDoor2 "Open Status of Door 2";
BA_ "CI_SigId" SG_ 2566759703 OpenStsOfDoor2 3276;
BA_ "CI_ParId" SG_ 2566759703 OpenStsOfDoor2 "3416";
BA_ "SigType" SG_ 2566759703 LckStsOfDoor2 4;
BA_ "SPN" SG_ 2566759703 LckStsOfDoor2 3415;
BA_ "GenSigTimeoutTime_SGW" SG_ 2566759703 LckStsOfDoor2 500;
BA_ "GenSigTimeoutTime_PCM" SG_ 2566759703 LckStsOfDoor2 500;
BA_ "GenSigTimeoutTime_MPPxPTFE2" SG_ 2566759703 LckStsOfDoor2 500;
BA_ "GenSigTimeoutTime_FMS_FMS5" SG_ 2566759703 LckStsOfDoor2 500;
BA_ "GenSigTimeoutTime_FMS_FMS4" SG_ 2566759703 LckStsOfDoor2 500;
BA_ "CI_SigName" SG_ 2566759703 LckStsOfDoor2 "Lock Status of Door 2";
BA_ "CI_SigId" SG_ 2566759703 LckStsOfDoor2 3275;
BA_ "CI_ParId" SG_ 2566759703 LckStsOfDoor2 "3415";
BA_ "SigType" SG_ 2566759703 EnaStsOfDoor1 4;
BA_ "SPN" SG_ 2566759703 EnaStsOfDoor1 3414;
BA_ "GenSigTimeoutTime_SGW" SG_ 2566759703 EnaStsOfDoor1 500;
BA_ "GenSigTimeoutTime_PCM" SG_ 2566759703 EnaStsOfDoor1 500;
BA_ "GenSigTimeoutTime_MPPxPTFE2" SG_ 2566759703 EnaStsOfDoor1 500;
BA_ "GenSigTimeoutTime_FMS_FMS5" SG_ 2566759703 EnaStsOfDoor1 500;
BA_ "GenSigTimeoutTime_FMS_FMS4" SG_ 2566759703 EnaStsOfDoor1 500;
BA_ "CI_SigName" SG_ 2566759703 EnaStsOfDoor1 "Enable Status of Door 1";
BA_ "CI_SigId" SG_ 2566759703 EnaStsOfDoor1 3274;
BA_ "CI_ParId" SG_ 2566759703 EnaStsOfDoor1 "3414";
BA_ "SigType" SG_ 2566759703 OpenStsOfDoor1 4;
BA_ "SPN" SG_ 2566759703 OpenStsOfDoor1 3413;
BA_ "GenSigTimeoutTime_SGW" SG_ 2566759703 OpenStsOfDoor1 500;
BA_ "GenSigTimeoutTime_PCM" SG_ 2566759703 OpenStsOfDoor1 500;
BA_ "GenSigTimeoutTime_MPPxPTFE2" SG_ 2566759703 OpenStsOfDoor1 500;
BA_ "GenSigTimeoutTime_FMS_FMS5" SG_ 2566759703 OpenStsOfDoor1 500;
BA_ "GenSigTimeoutTime_FMS_FMS4" SG_ 2566759703 OpenStsOfDoor1 500;
BA_ "CI_SigName" SG_ 2566759703 OpenStsOfDoor1 "Open Status of Door 1";
BA_ "CI_SigId" SG_ 2566759703 OpenStsOfDoor1 3273;
BA_ "CI_ParId" SG_ 2566759703 OpenStsOfDoor1 "3413";
BA_ "SigType" SG_ 2566759703 LckStsOfDoor1 4;
BA_ "SPN" SG_ 2566759703 LckStsOfDoor1 3412;
BA_ "GenSigTimeoutTime_SGW" SG_ 2566759703 LckStsOfDoor1 500;
BA_ "GenSigTimeoutTime_PCM" SG_ 2566759703 LckStsOfDoor1 500;
BA_ "GenSigTimeoutTime_MPPxPTFE2" SG_ 2566759703 LckStsOfDoor1 500;
BA_ "GenSigTimeoutTime_FMS_FMS5" SG_ 2566759703 LckStsOfDoor1 500;
BA_ "GenSigTimeoutTime_FMS_FMS4" SG_ 2566759703 LckStsOfDoor1 500;
BA_ "CI_SigName" SG_ 2566759703 LckStsOfDoor1 "Lock Status of Door 1";
BA_ "CI_SigId" SG_ 2566759703 LckStsOfDoor1 3272;
BA_ "CI_ParId" SG_ 2566759703 LckStsOfDoor1 "3412";
BA_ "CI_SigName" SG_ 2566849774 CodriverVdoPersDataCons "Codriver VDO Personal Data Consent";
BA_ "CI_SigId" SG_ 2566849774 CodriverVdoPersDataCons 2585;
BA_ "CI_ParId" SG_ 2566849774 CodriverVdoPersDataCons "V098";
BA_ "CI_SigName" SG_ 2566849774 DrivVdoPersDataCons "Driver VDO Personal Data Consent";
BA_ "CI_SigId" SG_ 2566849774 DrivVdoPersDataCons 2584;
BA_ "CI_ParId" SG_ 2566849774 DrivVdoPersDataCons "V097";
BA_ "CI_SigName" SG_ 2566849774 CodriverItsPersDataCons "Codriver ITS Personal Data Consent";
BA_ "CI_SigId" SG_ 2566849774 CodriverItsPersDataCons 2583;
BA_ "CI_ParId" SG_ 2566849774 CodriverItsPersDataCons "V096";
BA_ "CI_SigName" SG_ 2566849774 DrivItsPersDataCons "Driver ITS Personal Data Consent";
BA_ "CI_SigId" SG_ 2566849774 DrivItsPersDataCons 2582;
BA_ "CI_ParId" SG_ 2566849774 DrivItsPersDataCons "V095";
BA_ "SigType" SG_ 2566847521 FuelLev1 1;
BA_ "SPN" SG_ 2566847521 FuelLev1 96;
BA_ "GenSigTimeoutTime_VCM" SG_ 2566847521 FuelLev1 5000;
BA_ "GenSigTimeoutTime_SGW" SG_ 2566847521 FuelLev1 5000;
BA_ "GenSigTimeoutTime_PCM" SG_ 2566847521 FuelLev1 5000;
BA_ "GenSigTimeoutTime_IC_MulticS" SG_ 2566847521 FuelLev1 5000;
BA_ "GenSigTimeoutTime_FMS_FMS5" SG_ 2566847521 FuelLev1 5000;
BA_ "GenSigTimeoutTime_FMS_FMS4" SG_ 2566847521 FuelLev1 5000;
BA_ "CI_SigName" SG_ 2566847521 FuelLev1 "Fuel Level 1";
BA_ "CI_SigId" SG_ 2566847521 FuelLev1 3000;
BA_ "CI_ParId" SG_ 2566847521 FuelLev1 "96";
BA_ "SigType" SG_ 2566810606 Driv2Id 8;
BA_ "SPN" SG_ 2566810606 Driv2Id 1626;
BA_ "CI_SigName" SG_ 2566810606 Driv2Id "Driver 2 identification";
BA_ "CI_SigId" SG_ 2566810606 Driv2Id 731;
BA_ "CI_ParId" SG_ 2566810606 Driv2Id "1626";
BA_ "SigType" SG_ 2566810606 Driv1Id 8;
BA_ "SPN" SG_ 2566810606 Driv1Id 1625;
BA_ "CI_SigName" SG_ 2566810606 Driv1Id "Driver 1 identification";
BA_ "CI_SigId" SG_ 2566810606 Driv1Id 730;
BA_ "CI_ParId" SG_ 2566810606 Driv1Id "1625";
BA_ "SPN" SG_ 2566834688 SpnCm20 1706;
BA_ "GenSigTimeoutTime_SGW" SG_ 2566834688 SpnCm20 5000;
BA_ "GenSigTimeoutTime_PCM" SG_ 2566834688 SpnCm20 5000;
BA_ "GenSigTimeoutTime_IC_MulticS" SG_ 2566834688 SpnCm20 5000;
BA_ "GenSigTimeoutTime_FMS_FMS5" SG_ 2566834688 SpnCm20 5000;
BA_ "GenSigTimeoutTime_FMS_FMS4" SG_ 2566834688 SpnCm20 5000;
BA_ "GenSigTimeoutTime_BCM_NBM" SG_ 2566834688 SpnCm20 5000;
BA_ "GenSigSendType" SG_ 2566834688 SpnCm20 3;
BA_ "CI_SigName" SG_ 2566834688 SpnCm20 "SPN Conversion Method 20";
BA_ "CI_SigId" SG_ 2566834688 SpnCm20 4564;
BA_ "CI_ParId" SG_ 2566834688 SpnCm20 "1706";
BA_ "SPN" SG_ 2566834691 SpnCm10 1706;
BA_ "GenSigTimeoutTime_SGW" SG_ 2566834691 SpnCm10 5000;
BA_ "GenSigTimeoutTime_PCM" SG_ 2566834691 SpnCm10 5000;
BA_ "GenSigTimeoutTime_IC_MulticS" SG_ 2566834691 SpnCm10 5000;
BA_ "GenSigTimeoutTime_FMS_FMS5" SG_ 2566834691 SpnCm10 5000;
BA_ "GenSigTimeoutTime_FMS_FMS4" SG_ 2566834691 SpnCm10 5000;
BA_ "GenSigSendType" SG_ 2566834691 SpnCm10 3;
BA_ "CI_SigName" SG_ 2566834691 SpnCm10 "SPN Conversion Method 10";
BA_ "CI_SigId" SG_ 2566834691 SpnCm10 4623;
BA_ "CI_ParId" SG_ 2566834691 SpnCm10 "1706";
BA_ "SPN" SG_ 2566834699 SpnCm10_FECA0B 1706;
BA_ "GenSigTimeoutTime_SGW" SG_ 2566834699 SpnCm10_FECA0B 5000;
BA_ "GenSigTimeoutTime_PCM" SG_ 2566834699 SpnCm10_FECA0B 5000;
BA_ "GenSigTimeoutTime_MPPxPTFE2" SG_ 2566834699 SpnCm10_FECA0B 5000;
BA_ "GenSigTimeoutTime_IC_MulticS" SG_ 2566834699 SpnCm10_FECA0B 5000;
BA_ "GenSigTimeoutTime_FMS_FMS5" SG_ 2566834699 SpnCm10_FECA0B 5000;
BA_ "GenSigTimeoutTime_FMS_FMS4" SG_ 2566834699 SpnCm10_FECA0B 5000;
BA_ "GenSigSendType" SG_ 2566834699 SpnCm10_FECA0B 3;
BA_ "CI_SigName" SG_ 2566834699 SpnCm10_FECA0B "SPN Conversion Method 10";
BA_ "CI_SigId" SG_ 2566834699 SpnCm10_FECA0B 4678;
BA_ "CI_ParId" SG_ 2566834699 SpnCm10_FECA0B "1706";
BA_ "SPN" SG_ 2566834704 SpnCm10_FECA10 1706;
BA_ "GenSigTimeoutTime_SGW" SG_ 2566834704 SpnCm10_FECA10 5000;
BA_ "GenSigTimeoutTime_PCM" SG_ 2566834704 SpnCm10_FECA10 5000;
BA_ "GenSigTimeoutTime_IC_MulticS" SG_ 2566834704 SpnCm10_FECA10 5000;
BA_ "GenSigTimeoutTime_FMS_FMS5" SG_ 2566834704 SpnCm10_FECA10 5000;
BA_ "GenSigTimeoutTime_FMS_FMS4" SG_ 2566834704 SpnCm10_FECA10 5000;
BA_ "GenSigSendType" SG_ 2566834704 SpnCm10_FECA10 3;
BA_ "CI_SigName" SG_ 2566834704 SpnCm10_FECA10 "SPN Conversion Method 10";
BA_ "CI_SigId" SG_ 2566834704 SpnCm10_FECA10 4737;
BA_ "CI_ParId" SG_ 2566834704 SpnCm10_FECA10 "1706";
BA_ "SPN" SG_ 2566834711 SpnCm20_FECA17 1706;
BA_ "GenSigTimeoutTime_SGW" SG_ 2566834711 SpnCm20_FECA17 5000;
BA_ "GenSigTimeoutTime_PCM" SG_ 2566834711 SpnCm20_FECA17 5000;
BA_ "GenSigTimeoutTime_MPPxPTFE2" SG_ 2566834711 SpnCm20_FECA17 5000;
BA_ "GenSigTimeoutTime_FMS_FMS5" SG_ 2566834711 SpnCm20_FECA17 5000;
BA_ "GenSigTimeoutTime_FMS_FMS4" SG_ 2566834711 SpnCm20_FECA17 5000;
BA_ "GenSigSendType" SG_ 2566834711 SpnCm20_FECA17 3;
BA_ "CI_SigName" SG_ 2566834711 SpnCm20_FECA17 "SPN Conversion Method 20";
BA_ "CI_SigId" SG_ 2566834711 SpnCm20_FECA17 4842;
BA_ "CI_ParId" SG_ 2566834711 SpnCm20_FECA17 "1706";
BA_ "SPN" SG_ 2566834716 SpnCm10_FECA1C 1706;
BA_ "GenSigTimeoutTime_SGW" SG_ 2566834716 SpnCm10_FECA1C 5000;
BA_ "GenSigTimeoutTime_PCM" SG_ 2566834716 SpnCm10_FECA1C 5000;
BA_ "GenSigTimeoutTime_MPPxPTFE2" SG_ 2566834716 SpnCm10_FECA1C 5000;
BA_ "GenSigTimeoutTime_IC_MulticS" SG_ 2566834716 SpnCm10_FECA1C 5000;
BA_ "GenSigTimeoutTime_FMS_FMS5" SG_ 2566834716 SpnCm10_FECA1C 5000;
BA_ "GenSigTimeoutTime_FMS_FMS4" SG_ 2566834716 SpnCm10_FECA1C 5000;
BA_ "GenSigSendType" SG_ 2566834716 SpnCm10_FECA1C 3;
BA_ "CI_SigName" SG_ 2566834716 SpnCm10_FECA1C "SPN Conversion Method 10";
BA_ "CI_SigId" SG_ 2566834716 SpnCm10_FECA1C 5062;
BA_ "CI_ParId" SG_ 2566834716 SpnCm10_FECA1C "1706";
BA_ "SPN" SG_ 2566834717 SpnCm10_FECA1D 1706;
BA_ "GenSigTimeoutTime_PCM" SG_ 2566834717 SpnCm10_FECA1D 5000;
BA_ "GenSigTimeoutTime_MPPxPTFE2" SG_ 2566834717 SpnCm10_FECA1D 5000;
BA_ "GenSigTimeoutTime_IC_MulticS" SG_ 2566834717 SpnCm10_FECA1D 5000;
BA_ "GenSigTimeoutTime_FMS_FMS5" SG_ 2566834717 SpnCm10_FECA1D 5000;
BA_ "GenSigTimeoutTime_FMS_FMS4" SG_ 2566834717 SpnCm10_FECA1D 5000;
BA_ "GenSigSendType" SG_ 2566834717 SpnCm10_FECA1D 3;
BA_ "CI_SigName" SG_ 2566834717 SpnCm10_FECA1D "SPN Conversion Method 10";
BA_ "CI_SigId" SG_ 2566834717 SpnCm10_FECA1D 5117;
BA_ "CI_ParId" SG_ 2566834717 SpnCm10_FECA1D "1706";
BA_ "SPN" SG_ 2566834721 SpnCm10_FECA21 1706;
BA_ "GenSigTimeoutTime_SGW" SG_ 2566834721 SpnCm10_FECA21 5000;
BA_ "GenSigTimeoutTime_PCM" SG_ 2566834721 SpnCm10_FECA21 5000;
BA_ "GenSigTimeoutTime_MPPxPTFE2" SG_ 2566834721 SpnCm10_FECA21 5000;
BA_ "GenSigTimeoutTime_IC_MulticS" SG_ 2566834721 SpnCm10_FECA21 5000;
BA_ "GenSigTimeoutTime_FMS_FMS5" SG_ 2566834721 SpnCm10_FECA21 5000;
BA_ "GenSigTimeoutTime_FMS_FMS4" SG_ 2566834721 SpnCm10_FECA21 5000;
BA_ "GenSigSendType" SG_ 2566834721 SpnCm10_FECA21 3;
BA_ "CI_SigName" SG_ 2566834721 SpnCm10_FECA21 "SPN Conversion Method 10";
BA_ "CI_SigId" SG_ 2566834721 SpnCm10_FECA21 5172;
BA_ "CI_ParId" SG_ 2566834721 SpnCm10_FECA21 "1706";
BA_ "SPN" SG_ 2566834727 SpnCm10_FECA27 1706;
BA_ "GenSigTimeoutTime_SGW" SG_ 2566834727 SpnCm10_FECA27 5000;
BA_ "GenSigTimeoutTime_PCM" SG_ 2566834727 SpnCm10_FECA27 5000;
BA_ "GenSigTimeoutTime_IC_MulticS" SG_ 2566834727 SpnCm10_FECA27 5000;
BA_ "GenSigTimeoutTime_FMS_FMS5" SG_ 2566834727 SpnCm10_FECA27 5000;
BA_ "GenSigTimeoutTime_FMS_FMS4" SG_ 2566834727 SpnCm10_FECA27 5000;
BA_ "CI_SigName" SG_ 2566834727 SpnCm10_FECA27 "SPN Conversion Method 10";
BA_ "CI_SigId" SG_ 2566834727 SpnCm10_FECA27 5227;
BA_ "CI_ParId" SG_ 2566834727 SpnCm10_FECA27 "1706";
BA_ "SPN" SG_ 2566834734 SpnCm10_FECA2E 1706;
BA_ "GenSigTimeoutTime_SGW" SG_ 2566834734 SpnCm10_FECA2E 5000;
BA_ "GenSigTimeoutTime_PCM" SG_ 2566834734 SpnCm10_FECA2E 5000;
BA_ "GenSigTimeoutTime_MPPxPTFE2" SG_ 2566834734 SpnCm10_FECA2E 5000;
BA_ "GenSigTimeoutTime_IC_MulticS" SG_ 2566834734 SpnCm10_FECA2E 5000;
BA_ "GenSigTimeoutTime_FMS_FMS5" SG_ 2566834734 SpnCm10_FECA2E 5000;
BA_ "GenSigTimeoutTime_FMS_FMS4" SG_ 2566834734 SpnCm10_FECA2E 5000;
BA_ "GenSigSendType" SG_ 2566834734 SpnCm10_FECA2E 3;
BA_ "CI_SigName" SG_ 2566834734 SpnCm10_FECA2E "SPN Conversion Method 10";
BA_ "CI_SigId" SG_ 2566834734 SpnCm10_FECA2E 5337;
BA_ "CI_ParId" SG_ 2566834734 SpnCm10_FECA2E "1706";
BA_ "SPN" SG_ 2566834735 SpnCm10_FECA2F 1706;
BA_ "GenSigTimeoutTime_SGW" SG_ 2566834735 SpnCm10_FECA2F 5000;
BA_ "GenSigTimeoutTime_PCM" SG_ 2566834735 SpnCm10_FECA2F 5000;
BA_ "GenSigTimeoutTime_MPPxPTFE2" SG_ 2566834735 SpnCm10_FECA2F 5000;
BA_ "GenSigTimeoutTime_IC_MulticS" SG_ 2566834735 SpnCm10_FECA2F 5000;
BA_ "GenSigTimeoutTime_FMS_FMS5" SG_ 2566834735 SpnCm10_FECA2F 5000;
BA_ "GenSigTimeoutTime_FMS_FMS4" SG_ 2566834735 SpnCm10_FECA2F 5000;
BA_ "GenSigSendType" SG_ 2566834735 SpnCm10_FECA2F 3;
BA_ "CI_SigName" SG_ 2566834735 SpnCm10_FECA2F "SPN Conversion Method 10";
BA_ "CI_SigId" SG_ 2566834735 SpnCm10_FECA2F 5392;
BA_ "CI_ParId" SG_ 2566834735 SpnCm10_FECA2F "1706";
BA_ "SPN" SG_ 2566834739 SpnCm10_FECA33 1706;
BA_ "GenSigTimeoutTime_SGW" SG_ 2566834739 SpnCm10_FECA33 5000;
BA_ "GenSigTimeoutTime_PCM" SG_ 2566834739 SpnCm10_FECA33 5000;
BA_ "GenSigTimeoutTime_MPPxPTFE2" SG_ 2566834739 SpnCm10_FECA33 5000;
BA_ "GenSigTimeoutTime_IC_MulticS" SG_ 2566834739 SpnCm10_FECA33 5000;
BA_ "GenSigTimeoutTime_FMS_FMS5" SG_ 2566834739 SpnCm10_FECA33 5000;
BA_ "GenSigTimeoutTime_FMS_FMS4" SG_ 2566834739 SpnCm10_FECA33 5000;
BA_ "GenSigSendType" SG_ 2566834739 SpnCm10_FECA33 3;
BA_ "CI_SigName" SG_ 2566834739 SpnCm10_FECA33 "SPN Conversion Method 10";
BA_ "CI_SigId" SG_ 2566834739 SpnCm10_FECA33 5502;
BA_ "CI_ParId" SG_ 2566834739 SpnCm10_FECA33 "1706";
BA_ "SPN" SG_ 2566834744 SpnCm10_FECA38 1706;
BA_ "GenSigTimeoutTime_SGW" SG_ 2566834744 SpnCm10_FECA38 5000;
BA_ "GenSigTimeoutTime_PCM" SG_ 2566834744 SpnCm10_FECA38 5000;
BA_ "GenSigTimeoutTime_IC_MulticS" SG_ 2566834744 SpnCm10_FECA38 5000;
BA_ "GenSigTimeoutTime_FMS_FMS5" SG_ 2566834744 SpnCm10_FECA38 5000;
BA_ "GenSigTimeoutTime_FMS_FMS4" SG_ 2566834744 SpnCm10_FECA38 5000;
BA_ "GenSigSendType" SG_ 2566834744 SpnCm10_FECA38 3;
BA_ "CI_SigName" SG_ 2566834744 SpnCm10_FECA38 "SPN Conversion Method 10";
BA_ "CI_SigId" SG_ 2566834744 SpnCm10_FECA38 5557;
BA_ "CI_ParId" SG_ 2566834744 SpnCm10_FECA38 "1706";
BA_ "SPN" SG_ 2566834752 SpnCm10_FECA40 1706;
BA_ "GenSigTimeoutTime_SGW" SG_ 2566834752 SpnCm10_FECA40 5000;
BA_ "GenSigTimeoutTime_PCM" SG_ 2566834752 SpnCm10_FECA40 5000;
BA_ "GenSigTimeoutTime_MPPxPTFE2" SG_ 2566834752 SpnCm10_FECA40 5000;
BA_ "GenSigTimeoutTime_FMS_FMS5" SG_ 2566834752 SpnCm10_FECA40 5000;
BA_ "GenSigTimeoutTime_FMS_FMS4" SG_ 2566834752 SpnCm10_FECA40 5000;
BA_ "GenSigSendType" SG_ 2566834752 SpnCm10_FECA40 3;
BA_ "CI_SigName" SG_ 2566834752 SpnCm10_FECA40 "SPN Conversion Method 10";
BA_ "CI_SigId" SG_ 2566834752 SpnCm10_FECA40 5847;
BA_ "CI_ParId" SG_ 2566834752 SpnCm10_FECA40 "1706";
BA_ "SPN" SG_ 2566834761 SpnCm10_FECA49 1706;
BA_ "GenSigTimeoutTime_SGW" SG_ 2566834761 SpnCm10_FECA49 5000;
BA_ "GenSigTimeoutTime_PCM" SG_ 2566834761 SpnCm10_FECA49 5000;
BA_ "GenSigTimeoutTime_IC_MulticS" SG_ 2566834761 SpnCm10_FECA49 5000;
BA_ "GenSigTimeoutTime_FMS_FMS4" SG_ 2566834761 SpnCm10_FECA49 5000;
BA_ "GenSigSendType" SG_ 2566834761 SpnCm10_FECA49 3;
BA_ "CI_SigName" SG_ 2566834761 SpnCm10_FECA49 "SPN Conversion Method 10";
BA_ "CI_SigId" SG_ 2566834761 SpnCm10_FECA49 5007;
BA_ "CI_ParId" SG_ 2566834761 SpnCm10_FECA49 "1706";
BA_ "SPN" SG_ 2566834762 SpnCm10_FECA4A 1706;
BA_ "GenSigTimeoutTime_SGW" SG_ 2566834762 SpnCm10_FECA4A 5000;
BA_ "GenSigTimeoutTime_MPPxPTFE2" SG_ 2566834762 SpnCm10_FECA4A 5000;
BA_ "GenSigTimeoutTime_IC_MulticS" SG_ 2566834762 SpnCm10_FECA4A 5000;
BA_ "GenSigTimeoutTime_IC_MulticII" SG_ 2566834762 SpnCm10_FECA4A 5000;
BA_ "GenSigTimeoutTime_FMS_FMS5" SG_ 2566834762 SpnCm10_FECA4A 5000;
BA_ "GenSigTimeoutTime_FMS_FMS4" SG_ 2566834762 SpnCm10_FECA4A 5000;
BA_ "GenSigSendType" SG_ 2566834762 SpnCm10_FECA4A 3;
BA_ "CI_SigName" SG_ 2566834762 SpnCm10_FECA4A "SPN Conversion Method 10";
BA_ "CI_SigId" SG_ 2566834762 SpnCm10_FECA4A 5612;
BA_ "CI_ParId" SG_ 2566834762 SpnCm10_FECA4A "1706";
BA_ "SPN" SG_ 2566834778 SpnCm10_FECA5A 1706;
BA_ "GenSigTimeoutTime_VMU" SG_ 2566834778 SpnCm10_FECA5A 5000;
BA_ "GenSigTimeoutTime_VCU" SG_ 2566834778 SpnCm10_FECA5A 5000;
BA_ "GenSigTimeoutTime_SGW" SG_ 2566834778 SpnCm10_FECA5A 5000;
BA_ "GenSigTimeoutTime_PCM" SG_ 2566834778 SpnCm10_FECA5A 5000;
BA_ "GenSigSendType" SG_ 2566834778 SpnCm10_FECA5A 3;
BA_ "CI_SigName" SG_ 2566834778 SpnCm10_FECA5A "SPN Conversion Method 10";
BA_ "CI_SigId" SG_ 2566834778 SpnCm10_FECA5A 5792;
BA_ "CI_ParId" SG_ 2566834778 SpnCm10_FECA5A "1706";
BA_ "SPN" SG_ 2566834782 SpnCm10_FECA5E 1706;
BA_ "GenSigTimeoutTime_SGW2" SG_ 2566834782 SpnCm10_FECA5E 5000;
BA_ "GenSigTimeoutTime_SGW" SG_ 2566834782 SpnCm10_FECA5E 5000;
BA_ "GenSigTimeoutTime_PCM" SG_ 2566834782 SpnCm10_FECA5E 5000;
BA_ "GenSigSendType" SG_ 2566834782 SpnCm10_FECA5E 3;
BA_ "CI_SigName" SG_ 2566834782 SpnCm10_FECA5E "SPN Conversion Method 10";
BA_ "CI_SigId" SG_ 2566834782 SpnCm10_FECA5E 14808;
BA_ "CI_ParId" SG_ 2566834782 SpnCm10_FECA5E "1706";
BA_ "SPN" SG_ 2566834814 SpnCm10_FECA7E 1706;
BA_ "GenSigTimeoutTime_SGW" SG_ 2566834814 SpnCm10_FECA7E 5000;
BA_ "GenSigTimeoutTime_PCM" SG_ 2566834814 SpnCm10_FECA7E 5000;
BA_ "GenSigTimeoutTime_MPPxPTFE2" SG_ 2566834814 SpnCm10_FECA7E 5000;
BA_ "GenSigTimeoutTime_FMS_FMS5" SG_ 2566834814 SpnCm10_FECA7E 5000;
BA_ "GenSigTimeoutTime_FMS_FMS4" SG_ 2566834814 SpnCm10_FECA7E 5000;
BA_ "GenSigSendType" SG_ 2566834814 SpnCm10_FECA7E 3;
BA_ "CI_SigName" SG_ 2566834814 SpnCm10_FECA7E "SPN Conversion Method 10";
BA_ "CI_SigId" SG_ 2566834814 SpnCm10_FECA7E 5957;
BA_ "CI_ParId" SG_ 2566834814 SpnCm10_FECA7E "1706";
BA_ "SPN" SG_ 2566834832 SpnCm10_FECA90 1706;
BA_ "GenSigTimeoutTime_SGW" SG_ 2566834832 SpnCm10_FECA90 5000;
BA_ "GenSigTimeoutTime_PCM" SG_ 2566834832 SpnCm10_FECA90 5000;
BA_ "GenSigTimeoutTime_IC_MulticS" SG_ 2566834832 SpnCm10_FECA90 5000;
BA_ "GenSigSendType" SG_ 2566834832 SpnCm10_FECA90 3;
BA_ "CI_SigName" SG_ 2566834832 SpnCm10_FECA90 "SPN Conversion Method 10";
BA_ "CI_SigId" SG_ 2566834832 SpnCm10_FECA90 6122;
BA_ "CI_ParId" SG_ 2566834832 SpnCm10_FECA90 "1706";
BA_ "SPN" SG_ 2566834833 SpnCm10_FECA91 1706;
BA_ "GenSigTimeoutTime_SGW" SG_ 2566834833 SpnCm10_FECA91 5000;
BA_ "GenSigTimeoutTime_PCM" SG_ 2566834833 SpnCm10_FECA91 5000;
BA_ "GenSigTimeoutTime_IC_MulticS" SG_ 2566834833 SpnCm10_FECA91 5000;
BA_ "GenSigSendType" SG_ 2566834833 SpnCm10_FECA91 3;
BA_ "CI_SigName" SG_ 2566834833 SpnCm10_FECA91 "SPN Conversion Method 10";
BA_ "CI_SigId" SG_ 2566834833 SpnCm10_FECA91 6177;
BA_ "CI_ParId" SG_ 2566834833 SpnCm10_FECA91 "1706";
BA_ "SPN" SG_ 2566834834 SpnCm10_FECA92 1706;
BA_ "GenSigTimeoutTime_SGW" SG_ 2566834834 SpnCm10_FECA92 5000;
BA_ "GenSigTimeoutTime_PCM" SG_ 2566834834 SpnCm10_FECA92 5000;
BA_ "GenSigTimeoutTime_IC_MulticS" SG_ 2566834834 SpnCm10_FECA92 5000;
BA_ "GenSigSendType" SG_ 2566834834 SpnCm10_FECA92 3;
BA_ "CI_SigName" SG_ 2566834834 SpnCm10_FECA92 "SPN Conversion Method 10";
BA_ "CI_SigId" SG_ 2566834834 SpnCm10_FECA92 6232;
BA_ "CI_ParId" SG_ 2566834834 SpnCm10_FECA92 "1706";
BA_ "SPN" SG_ 2566834844 SpnCm10_FECA9C 1706;
BA_ "GenSigTimeoutTime_SGW" SG_ 2566834844 SpnCm10_FECA9C 5000;
BA_ "GenSigTimeoutTime_PCM" SG_ 2566834844 SpnCm10_FECA9C 5000;
BA_ "GenSigTimeoutTime_IC_MulticS" SG_ 2566834844 SpnCm10_FECA9C 5000;
BA_ "GenSigSendType" SG_ 2566834844 SpnCm10_FECA9C 3;
BA_ "CI_SigName" SG_ 2566834844 SpnCm10_FECA9C "SPN Conversion Method 10";
BA_ "CI_SigId" SG_ 2566834844 SpnCm10_FECA9C 6287;
BA_ "CI_ParId" SG_ 2566834844 SpnCm10_FECA9C "1706";
BA_ "SPN" SG_ 2566834846 SpnCm10_FECA9E 1706;
BA_ "GenSigTimeoutTime_SGW" SG_ 2566834846 SpnCm10_FECA9E 5000;
BA_ "GenSigTimeoutTime_PCM" SG_ 2566834846 SpnCm10_FECA9E 5000;
BA_ "GenSigTimeoutTime_IC_MulticS" SG_ 2566834846 SpnCm10_FECA9E 5000;
BA_ "GenSigSendType" SG_ 2566834846 SpnCm10_FECA9E 3;
BA_ "CI_SigName" SG_ 2566834846 SpnCm10_FECA9E "SPN Conversion Method 10";
BA_ "CI_SigId" SG_ 2566834846 SpnCm10_FECA9E 6012;
BA_ "CI_ParId" SG_ 2566834846 SpnCm10_FECA9E "1706";
BA_ "SPN" SG_ 2566834848 SpnCm10_FECAA0 1706;
BA_ "GenSigTimeoutTime_SGW" SG_ 2566834848 SpnCm10_FECAA0 5000;
BA_ "GenSigTimeoutTime_PCM" SG_ 2566834848 SpnCm10_FECAA0 5000;
BA_ "GenSigTimeoutTime_MPPxPTFE2" SG_ 2566834848 SpnCm10_FECAA0 5000;
BA_ "GenSigTimeoutTime_IC_MulticS" SG_ 2566834848 SpnCm10_FECAA0 5000;
BA_ "GenSigTimeoutTime_FMS_FMS5" SG_ 2566834848 SpnCm10_FECAA0 5000;
BA_ "GenSigTimeoutTime_FMS_FMS4" SG_ 2566834848 SpnCm10_FECAA0 5000;
BA_ "GenSigSendType" SG_ 2566834848 SpnCm10_FECAA0 3;
BA_ "CI_SigName" SG_ 2566834848 SpnCm10_FECAA0 "SPN Conversion Method 10";
BA_ "CI_SigId" SG_ 2566834848 SpnCm10_FECAA0 6342;
BA_ "CI_ParId" SG_ 2566834848 SpnCm10_FECAA0 "1706";
BA_ "SPN" SG_ 2566834920 SpnCm10_FECAE8 1706;
BA_ "GenSigTimeoutTime_SGW" SG_ 2566834920 SpnCm10_FECAE8 5000;
BA_ "GenSigTimeoutTime_PCM" SG_ 2566834920 SpnCm10_FECAE8 5000;
BA_ "GenSigTimeoutTime_IC_MulticS" SG_ 2566834920 SpnCm10_FECAE8 5000;
BA_ "GenSigSendType" SG_ 2566834920 SpnCm10_FECAE8 3;
BA_ "CI_SigName" SG_ 2566834920 SpnCm10_FECAE8 "SPN Conversion Method 10";
BA_ "CI_SigId" SG_ 2566834920 SpnCm10_FECAE8 6067;
BA_ "CI_ParId" SG_ 2566834920 SpnCm10_FECAE8 "1706";
BA_ "SPN" SG_ 2566834926 SpnCm10_FECAEE 1706;
BA_ "GenSigTimeoutTime_SGW" SG_ 2566834926 SpnCm10_FECAEE 5000;
BA_ "GenSigTimeoutTime_PCM" SG_ 2566834926 SpnCm10_FECAEE 5000;
BA_ "GenSigTimeoutTime_MPPxPTFE2" SG_ 2566834926 SpnCm10_FECAEE 5000;
BA_ "GenSigTimeoutTime_IC_MulticS" SG_ 2566834926 SpnCm10_FECAEE 5000;
BA_ "GenSigTimeoutTime_FMS_FMS5" SG_ 2566834926 SpnCm10_FECAEE 5000;
BA_ "GenSigTimeoutTime_FMS_FMS4" SG_ 2566834926 SpnCm10_FECAEE 5000;
BA_ "GenSigSendType" SG_ 2566834926 SpnCm10_FECAEE 3;
BA_ "CI_SigName" SG_ 2566834926 SpnCm10_FECAEE "SPN Conversion Method 10";
BA_ "CI_SigId" SG_ 2566834926 SpnCm10_FECAEE 6407;
BA_ "CI_ParId" SG_ 2566834926 SpnCm10_FECAEE "1706";
BA_ "SPN" SG_ 2566834928 SpnCm10_FECAF0 1706;
BA_ "GenSigTimeoutTime_VMU" SG_ 2566834928 SpnCm10_FECAF0 5000;
BA_ "GenSigTimeoutTime_SGW" SG_ 2566834928 SpnCm10_FECAF0 5000;
BA_ "GenSigTimeoutTime_PCM" SG_ 2566834928 SpnCm10_FECAF0 5000;
BA_ "GenSigTimeoutTime_MPPxPTFE2" SG_ 2566834928 SpnCm10_FECAF0 5000;
BA_ "GenSigTimeoutTime_IC_MulticII" SG_ 2566834928 SpnCm10_FECAF0 5000;
BA_ "GenSigTimeoutTime_FMS_FMS5" SG_ 2566834928 SpnCm10_FECAF0 5000;
BA_ "GenSigTimeoutTime_FMS_FMS4" SG_ 2566834928 SpnCm10_FECAF0 5000;
BA_ "GenSigSendType" SG_ 2566834928 SpnCm10_FECAF0 3;
BA_ "CI_SigName" SG_ 2566834928 SpnCm10_FECAF0 "SPN Conversion Method 10";
BA_ "CI_SigId" SG_ 2566834928 SpnCm10_FECAF0 20616;
BA_ "CI_ParId" SG_ 2566834928 SpnCm10_FECAF0 "1706";
BA_ "SPN" SG_ 2566834931 SpnCm10_FECAF3 1706;
BA_ "GenSigTimeoutTime_VMU" SG_ 2566834931 SpnCm10_FECAF3 5000;
BA_ "GenSigTimeoutTime_SGW" SG_ 2566834931 SpnCm10_FECAF3 5000;
BA_ "GenSigTimeoutTime_PCM" SG_ 2566834931 SpnCm10_FECAF3 5000;
BA_ "GenSigTimeoutTime_MPPxPTFE2" SG_ 2566834931 SpnCm10_FECAF3 5000;
BA_ "GenSigTimeoutTime_IC_MulticS" SG_ 2566834931 SpnCm10_FECAF3 5000;
BA_ "GenSigTimeoutTime_IC_MulticII" SG_ 2566834931 SpnCm10_FECAF3 5000;
BA_ "GenSigTimeoutTime_FMS_FMS5" SG_ 2566834931 SpnCm10_FECAF3 5000;
BA_ "GenSigTimeoutTime_FMS_FMS4" SG_ 2566834931 SpnCm10_FECAF3 5000;
BA_ "GenSigSendType" SG_ 2566834931 SpnCm10_FECAF3 3;
BA_ "CI_SigName" SG_ 2566834931 SpnCm10_FECAF3 "SPN Conversion Method 10";
BA_ "CI_SigId" SG_ 2566834931 SpnCm10_FECAF3 6462;
BA_ "CI_ParId" SG_ 2566834931 SpnCm10_FECAF3 "1706";
BA_ "SPN" SG_ 2566834972 SpnCm10_FECB1C 1706;
BA_ "CI_SigName" SG_ 2566834972 SpnCm10_FECB1C "SPN Conversion Method 10";
BA_ "CI_SigId" SG_ 2566834972 SpnCm10_FECB1C 6855;
BA_ "CI_ParId" SG_ 2566834972 SpnCm10_FECB1C "1706";
BA_ "SPN" SG_ 2566834973 SpnCm10_FECB1D 1706;
BA_ "CI_SigName" SG_ 2566834973 SpnCm10_FECB1D "SPN Conversion Method 10";
BA_ "CI_SigId" SG_ 2566834973 SpnCm10_FECB1D 7020;
BA_ "CI_ParId" SG_ 2566834973 SpnCm10_FECB1D "1706";
BA_ "SPN" SG_ 2566835102 SpnCm10_FECB9E 1706;
BA_ "CI_SigName" SG_ 2566835102 SpnCm10_FECB9E "SPN Conversion Method 10";
BA_ "CI_SigId" SG_ 2566835102 SpnCm10_FECB9E 7295;
BA_ "CI_ParId" SG_ 2566835102 SpnCm10_FECB9E "1706";
BA_ "SigType" SG_ 2566835485 HrTotVehDist_10 1;
BA_ "SPN" SG_ 2566835485 HrTotVehDist_10 917;
BA_ "CI_SigName" SG_ 2566835485 HrTotVehDist_10 "High Resolution Total Vehicle Distance – 10";
BA_ "CI_SigId" SG_ 2566835485 HrTotVehDist_10 8794;
BA_ "CI_ParId" SG_ 2566835485 HrTotVehDist_10 "917";
BA_ "SigType" SG_ 2566835614 HrTotVehDist_10_FECD9E 1;
BA_ "SPN" SG_ 2566835614 HrTotVehDist_10_FECD9E 917;
BA_ "CI_SigName" SG_ 2566835614 HrTotVehDist_10_FECD9E "High Resolution Total Vehicle Distance – 10";
BA_ "CI_SigId" SG_ 2566835614 HrTotVehDist_10_FECD9E 9397;
BA_ "CI_ParId" SG_ 2566835614 HrTotVehDist_10_FECD9E "917";
BA_ "SPN" SG_ 2633943577 SpnCm10_FECA19 1706;
BA_ "GenSigTimeoutTime_SGW" SG_ 2633943577 SpnCm10_FECA19 5000;
BA_ "GenSigTimeoutTime_PCM" SG_ 2633943577 SpnCm10_FECA19 5000;
BA_ "GenSigTimeoutTime_IC_MulticII" SG_ 2633943577 SpnCm10_FECA19 5000;
BA_ "GenSigTimeoutTime_BCM_NBM" SG_ 2633943577 SpnCm10_FECA19 5000;
BA_ "GenSigSendType" SG_ 2633943577 SpnCm10_FECA19 3;
BA_ "CI_SigName" SG_ 2633943577 SpnCm10_FECA19 "SPN Conversion Method 10";
BA_ "CI_SigId" SG_ 2633943577 SpnCm10_FECA19 14970;
BA_ "CI_ParId" SG_ 2633943577 SpnCm10_FECA19 "1706";
BA_ "SPN" SG_ 2633943610 SpnCm10_FECA3A 1706;
BA_ "GenSigTimeoutTime_SGW" SG_ 2633943610 SpnCm10_FECA3A 5000;
BA_ "GenSigTimeoutTime_PCM" SG_ 2633943610 SpnCm10_FECA3A 5000;
BA_ "GenSigTimeoutTime_IC_MulticII" SG_ 2633943610 SpnCm10_FECA3A 5000;
BA_ "GenSigTimeoutTime_BCM_NBM" SG_ 2633943610 SpnCm10_FECA3A 5000;
BA_ "GenSigSendType" SG_ 2633943610 SpnCm10_FECA3A 3;
BA_ "CI_SigName" SG_ 2633943610 SpnCm10_FECA3A "SPN Conversion Method 10";
BA_ "CI_SigId" SG_ 2633943610 SpnCm10_FECA3A 20789;
BA_ "CI_ParId" SG_ 2633943610 SpnCm10_FECA3A "1706";
BA_ "SPN" SG_ 2633943680 SpnCm10_FECA80 1706;
BA_ "GenSigTimeoutTime_SGW" SG_ 2633943680 SpnCm10_FECA80 5000;
BA_ "GenSigTimeoutTime_PCM" SG_ 2633943680 SpnCm10_FECA80 5000;
BA_ "GenSigTimeoutTime_MPPxPTFE2" SG_ 2633943680 SpnCm10_FECA80 5000;
BA_ "GenSigTimeoutTime_IC_MulticS" SG_ 2633943680 SpnCm10_FECA80 5000;
BA_ "GenSigTimeoutTime_IC_MulticII" SG_ 2633943680 SpnCm10_FECA80 5000;
BA_ "GenSigTimeoutTime_FMS_FMS5" SG_ 2633943680 SpnCm10_FECA80 5000;
BA_ "GenSigTimeoutTime_FMS_FMS4" SG_ 2633943680 SpnCm10_FECA80 5000;
BA_ "GenSigSendType" SG_ 2633943680 SpnCm10_FECA80 3;
BA_ "CI_SigName" SG_ 2633943680 SpnCm10_FECA80 "SPN Conversion Method 10";
BA_ "CI_SigId" SG_ 2633943680 SpnCm10_FECA80 5722;
BA_ "CI_ParId" SG_ 2633943680 SpnCm10_FECA80 "1706";
BA_ "SigType" SG_ 2566856773 DoorClosTime4 1;
BA_ "GenSigTimeoutTime_SGW" SG_ 2566856773 DoorClosTime4 5000;
BA_ "GenSigTimeoutTime_PCM" SG_ 2566856773 DoorClosTime4 5000;
BA_ "CI_SigName" SG_ 2566856773 DoorClosTime4 "Door Closing Time 4";
BA_ "CI_SigId" SG_ 2566856773 DoorClosTime4 3375;
BA_ "CI_ParId" SG_ 2566856773 DoorClosTime4 "IB498";
BA_ "SigType" SG_ 2566856773 DoorClosTime3 1;
BA_ "GenSigTimeoutTime_SGW" SG_ 2566856773 DoorClosTime3 5000;
BA_ "GenSigTimeoutTime_PCM" SG_ 2566856773 DoorClosTime3 5000;
BA_ "CI_SigName" SG_ 2566856773 DoorClosTime3 "Door Closing Time 3";
BA_ "CI_SigId" SG_ 2566856773 DoorClosTime3 3374;
BA_ "CI_ParId" SG_ 2566856773 DoorClosTime3 "IB497";
BA_ "SigType" SG_ 2566856773 DoorClosTime2 1;
BA_ "GenSigTimeoutTime_SGW" SG_ 2566856773 DoorClosTime2 5000;
BA_ "GenSigTimeoutTime_PCM" SG_ 2566856773 DoorClosTime2 5000;
BA_ "CI_SigName" SG_ 2566856773 DoorClosTime2 "Door Closing Time 2";
BA_ "CI_SigId" SG_ 2566856773 DoorClosTime2 3373;
BA_ "CI_ParId" SG_ 2566856773 DoorClosTime2 "IB496";
BA_ "SigType" SG_ 2566856773 DoorClosTime1 1;
BA_ "GenSigTimeoutTime_SGW" SG_ 2566856773 DoorClosTime1 5000;
BA_ "GenSigTimeoutTime_PCM" SG_ 2566856773 DoorClosTime1 5000;
BA_ "CI_SigName" SG_ 2566856773 DoorClosTime1 "Door Closing Time 1";
BA_ "CI_SigId" SG_ 2566856773 DoorClosTime1 3372;
BA_ "CI_ParId" SG_ 2566856773 DoorClosTime1 "IB495";
BA_ "SigType" SG_ 2566856773 DoorClosTime0 1;
BA_ "GenSigTimeoutTime_SGW" SG_ 2566856773 DoorClosTime0 5000;
BA_ "GenSigTimeoutTime_PCM" SG_ 2566856773 DoorClosTime0 5000;
BA_ "CI_SigName" SG_ 2566856773 DoorClosTime0 "Door Closing Time 0";
BA_ "CI_SigId" SG_ 2566856773 DoorClosTime0 3371;
BA_ "CI_ParId" SG_ 2566856773 DoorClosTime0 "IB494";
BA_ "GenSigTimeoutTime_SGW" SG_ 2566856773 DoorCnt4 5000;
BA_ "GenSigTimeoutTime_PCM" SG_ 2566856773 DoorCnt4 5000;
BA_ "CI_SigName" SG_ 2566856773 DoorCnt4 "Door Counter 4";
BA_ "CI_SigId" SG_ 2566856773 DoorCnt4 3370;
BA_ "CI_ParId" SG_ 2566856773 DoorCnt4 "IB493";
BA_ "GenSigTimeoutTime_SGW" SG_ 2566856773 DoorCnt3 5000;
BA_ "GenSigTimeoutTime_PCM" SG_ 2566856773 DoorCnt3 5000;
BA_ "CI_SigName" SG_ 2566856773 DoorCnt3 "Door Counter 3";
BA_ "CI_SigId" SG_ 2566856773 DoorCnt3 3369;
BA_ "CI_ParId" SG_ 2566856773 DoorCnt3 "IB492";
BA_ "GenSigTimeoutTime_SGW" SG_ 2566856773 DoorCnt2 5000;
BA_ "GenSigTimeoutTime_PCM" SG_ 2566856773 DoorCnt2 5000;
BA_ "CI_SigName" SG_ 2566856773 DoorCnt2 "Door Counter 2";
BA_ "CI_SigId" SG_ 2566856773 DoorCnt2 3368;
BA_ "CI_ParId" SG_ 2566856773 DoorCnt2 "IB491";
BA_ "GenSigTimeoutTime_SGW" SG_ 2566856773 DoorCnt1 5000;
BA_ "GenSigTimeoutTime_PCM" SG_ 2566856773 DoorCnt1 5000;
BA_ "CI_SigName" SG_ 2566856773 DoorCnt1 "Door Counter 1";
BA_ "CI_SigId" SG_ 2566856773 DoorCnt1 3367;
BA_ "CI_ParId" SG_ 2566856773 DoorCnt1 "IB490";
BA_ "GenSigTimeoutTime_SGW" SG_ 2566856773 DoorCnt0 5000;
BA_ "GenSigTimeoutTime_PCM" SG_ 2566856773 DoorCnt0 5000;
BA_ "CI_SigName" SG_ 2566856773 DoorCnt0 "Door Counter 0";
BA_ "CI_SigId" SG_ 2566856773 DoorCnt0 3366;
BA_ "CI_ParId" SG_ 2566856773 DoorCnt0 "IB489";
BA_ "GenSigTimeoutTime_SGW" SG_ 2566856773 DoorId 5000;
BA_ "GenSigTimeoutTime_PCM" SG_ 2566856773 DoorId 5000;
BA_ "CI_SigName" SG_ 2566856773 DoorId "Door ID";
BA_ "CI_SigId" SG_ 2566856773 DoorId 3365;
BA_ "CI_ParId" SG_ 2566856773 DoorId "IB488";
BA_ "SigType" SG_ 2566749184 DpfAregenInhSts 4;
BA_ "SPN" SG_ 2566749184 DpfAregenInhSts 3702;
BA_ "GenSigTimeoutTime_VCM" SG_ 2566749184 DpfAregenInhSts 5000;
BA_ "GenSigTimeoutTime_SGW" SG_ 2566749184 DpfAregenInhSts 5000;
BA_ "GenSigTimeoutTime_PCM" SG_ 2566749184 DpfAregenInhSts 5000;
BA_ "CI_SigName" SG_ 2566749184 DpfAregenInhSts "Diesel Particulate Filter Active Regeneration Inhibited Status";
BA_ "CI_SigId" SG_ 2566749184 DpfAregenInhSts 1220;
BA_ "CI_ParId" SG_ 2566749184 DpfAregenInhSts "3702";
BA_ "SPN" SG_ 2566749184 AtDpfSts 3701;
BA_ "GenSigTimeoutTime_VCM" SG_ 2566749184 AtDpfSts 5000;
BA_ "GenSigTimeoutTime_SGW" SG_ 2566749184 AtDpfSts 5000;
BA_ "GenSigTimeoutTime_PCM" SG_ 2566749184 AtDpfSts 5000;
BA_ "CI_SigName" SG_ 2566749184 AtDpfSts "Aftertreatment Diesel Particulate Filter Status";
BA_ "CI_SigId" SG_ 2566749184 AtDpfSts 1219;
BA_ "CI_ParId" SG_ 2566749184 AtDpfSts "3701";
BA_ "SigType" SG_ 2566749184 AtDpfAregenSts 4;
BA_ "SPN" SG_ 2566749184 AtDpfAregenSts 3700;
BA_ "GenSigTimeoutTime_VCM" SG_ 2566749184 AtDpfAregenSts 5000;
BA_ "GenSigTimeoutTime_SGW" SG_ 2566749184 AtDpfAregenSts 5000;
BA_ "GenSigTimeoutTime_PCM" SG_ 2566749184 AtDpfAregenSts 5000;
BA_ "GenSigTimeoutTime_BCM_NBM" SG_ 2566749184 AtDpfAregenSts 5000;
BA_ "CI_SigName" SG_ 2566749184 AtDpfAregenSts "Aftertreatment Diesel Particulate Filter Active Regeneration Status";
BA_ "CI_SigId" SG_ 2566749184 AtDpfAregenSts 1218;
BA_ "CI_ParId" SG_ 2566749184 AtDpfAregenSts "3700";
BA_ "SigType" SG_ 2566749184 AtDpfPregenSts 4;
BA_ "SPN" SG_ 2566749184 AtDpfPregenSts 3699;
BA_ "GenSigTimeoutTime_VCM" SG_ 2566749184 AtDpfPregenSts 5000;
BA_ "GenSigTimeoutTime_SGW" SG_ 2566749184 AtDpfPregenSts 5000;
BA_ "GenSigTimeoutTime_PCM" SG_ 2566749184 AtDpfPregenSts 5000;
BA_ "GenSigTimeoutTime_BCM_NBM" SG_ 2566749184 AtDpfPregenSts 5000;
BA_ "CI_SigName" SG_ 2566749184 AtDpfPregenSts "Aftertreatment Diesel Particulate Filter Passive Regeneration Status";
BA_ "CI_SigId" SG_ 2566749184 AtDpfPregenSts 1217;
BA_ "CI_ParId" SG_ 2566749184 AtDpfPregenSts "3699";
BA_ "SPN" SG_ 2566749184 DpfLampCmd 3697;
BA_ "GenSigTimeoutTime_VCM" SG_ 2566749184 DpfLampCmd 5000;
BA_ "GenSigTimeoutTime_SGW" SG_ 2566749184 DpfLampCmd 5000;
BA_ "GenSigTimeoutTime_PCM" SG_ 2566749184 DpfLampCmd 5000;
BA_ "GenSigTimeoutTime_IC_MulticS" SG_ 2566749184 DpfLampCmd 5000;
BA_ "GenSigTimeoutTime_BCM_NBM" SG_ 2566749184 DpfLampCmd 5000;
BA_ "CI_SigName" SG_ 2566749184 DpfLampCmd "Diesel Particulate Filter Lamp Command";
BA_ "CI_SigId" SG_ 2566749184 DpfLampCmd 1216;
BA_ "CI_ParId" SG_ 2566749184 DpfLampCmd "3697";
BA_ "GenSigTimeoutTime_SGW" SG_ 2561126730 WeightAcc 5000;
BA_ "GenSigStartValue" SG_ 2561126730 WeightAcc 1;
BA_ "CI_SigName" SG_ 2561126730 WeightAcc "WeightAcc";
BA_ "CI_SigId" SG_ 2561126730 WeightAcc 14229;
BA_ "CI_ParId" SG_ 2561126730 WeightAcc "IB1617";
BA_ "SigType" SG_ 2561126730 BenefitAcc 4;
BA_ "GenSigTimeoutTime_SGW" SG_ 2561126730 BenefitAcc 5000;
BA_ "CI_SigName" SG_ 2561126730 BenefitAcc "BenefitAcc";
BA_ "CI_SigId" SG_ 2561126730 BenefitAcc 14228;
BA_ "CI_ParId" SG_ 2561126730 BenefitAcc "IB1616";
BA_ "GenSigTimeoutTime_SGW" SG_ 2561126730 TrendAcc 5000;
BA_ "GenSigStartValue" SG_ 2561126730 TrendAcc 1;
BA_ "CI_SigName" SG_ 2561126730 TrendAcc "TrendAcc";
BA_ "CI_SigId" SG_ 2561126730 TrendAcc 14227;
BA_ "CI_ParId" SG_ 2561126730 TrendAcc "IB1615";
BA_ "SigType" SG_ 2561126730 ValidAcc 4;
BA_ "GenSigTimeoutTime_SGW" SG_ 2561126730 ValidAcc 5000;
BA_ "CI_SigName" SG_ 2561126730 ValidAcc "ValidAcc";
BA_ "CI_SigId" SG_ 2561126730 ValidAcc 14226;
BA_ "CI_ParId" SG_ 2561126730 ValidAcc "IB1614";
BA_ "GenSigTimeoutTime_SGW" SG_ 2561126730 ScoreAcc 5000;
BA_ "GenSigStartValue" SG_ 2561126730 ScoreAcc 1;
BA_ "CI_SigName" SG_ 2561126730 ScoreAcc "ScoreAcc";
BA_ "CI_SigId" SG_ 2561126730 ScoreAcc 14225;
BA_ "CI_ParId" SG_ 2561126730 ScoreAcc "IB1613";
BA_ "SigType" SG_ 2561126986 EventAcc 4;
BA_ "GenSigTimeoutTime_SGW" SG_ 2561126986 EventAcc 5000;
BA_ "CI_SigName" SG_ 2561126986 EventAcc "EventAcc";
BA_ "CI_SigId" SG_ 2561126986 EventAcc 14232;
BA_ "CI_ParId" SG_ 2561126986 EventAcc "IB1619";
BA_ "GenSigTimeoutTime_SGW" SG_ 2561126986 EvaluatedSamplesAcc 5000;
BA_ "GenSigStartValue" SG_ 2561126986 EvaluatedSamplesAcc 1;
BA_ "CI_SigName" SG_ 2561126986 EvaluatedSamplesAcc "EvaluatedSamplesAcc";
BA_ "CI_SigId" SG_ 2561126986 EvaluatedSamplesAcc 14231;
BA_ "CI_ParId" SG_ 2561126986 EvaluatedSamplesAcc "IB1618";
BA_ "GenSigTimeoutTime_SGW" SG_ 2561127242 WeightAcceleration 5000;
BA_ "GenSigStartValue" SG_ 2561127242 WeightAcceleration 1;
BA_ "CI_SigName" SG_ 2561127242 WeightAcceleration "WeightAcceleration";
BA_ "CI_SigId" SG_ 2561127242 WeightAcceleration 14238;
BA_ "CI_ParId" SG_ 2561127242 WeightAcceleration "IB1624";
BA_ "SigType" SG_ 2561127242 BenefitAcceleration 4;
BA_ "GenSigTimeoutTime_SGW" SG_ 2561127242 BenefitAcceleration 5000;
BA_ "CI_SigName" SG_ 2561127242 BenefitAcceleration "BenefitAcceleration";
BA_ "CI_SigId" SG_ 2561127242 BenefitAcceleration 14237;
BA_ "CI_ParId" SG_ 2561127242 BenefitAcceleration "IB1623";
BA_ "GenSigTimeoutTime_SGW" SG_ 2561127242 TrendAcceleration 5000;
BA_ "GenSigStartValue" SG_ 2561127242 TrendAcceleration 1;
BA_ "CI_SigName" SG_ 2561127242 TrendAcceleration "TrendAcceleration";
BA_ "CI_SigId" SG_ 2561127242 TrendAcceleration 14236;
BA_ "CI_ParId" SG_ 2561127242 TrendAcceleration "IB1622";
BA_ "SigType" SG_ 2561127242 ValidAcceleration 4;
BA_ "GenSigTimeoutTime_SGW" SG_ 2561127242 ValidAcceleration 5000;
BA_ "CI_SigName" SG_ 2561127242 ValidAcceleration "ValidAcceleration";
BA_ "CI_SigId" SG_ 2561127242 ValidAcceleration 14235;
BA_ "CI_ParId" SG_ 2561127242 ValidAcceleration "IB1621";
BA_ "GenSigTimeoutTime_SGW" SG_ 2561127242 ScoreAcceleration 5000;
BA_ "GenSigStartValue" SG_ 2561127242 ScoreAcceleration 1;
BA_ "CI_SigName" SG_ 2561127242 ScoreAcceleration "ScoreAcceleration";
BA_ "CI_SigId" SG_ 2561127242 ScoreAcceleration 14234;
BA_ "CI_ParId" SG_ 2561127242 ScoreAcceleration "IB1620";
BA_ "GenSigTimeoutTime_SGW" SG_ 2561127498 AvgAccelerator 5000;
BA_ "GenSigStartValue" SG_ 2561127498 AvgAccelerator 10;
BA_ "CI_SigName" SG_ 2561127498 AvgAccelerator "AvgAccelerator";
BA_ "CI_SigId" SG_ 2561127498 AvgAccelerator 14244;
BA_ "CI_ParId" SG_ 2561127498 AvgAccelerator "IB1629";
BA_ "GenSigTimeoutTime_SGW" SG_ 2561127498 DurationAcceleration 5000;
BA_ "GenSigStartValue" SG_ 2561127498 DurationAcceleration 1;
BA_ "CI_SigName" SG_ 2561127498 DurationAcceleration "DurationAcceleration";
BA_ "CI_SigId" SG_ 2561127498 DurationAcceleration 14243;
BA_ "CI_ParId" SG_ 2561127498 DurationAcceleration "IB1628";
BA_ "GenSigTimeoutTime_SGW" SG_ 2561127498 LastManeuverScoreAcc 5000;
BA_ "GenSigStartValue" SG_ 2561127498 LastManeuverScoreAcc 1;
BA_ "CI_SigName" SG_ 2561127498 LastManeuverScoreAcc "LastManeuverScoreAcceleration";
BA_ "CI_SigId" SG_ 2561127498 LastManeuverScoreAcc 14242;
BA_ "CI_ParId" SG_ 2561127498 LastManeuverScoreAcc "IB1627";
BA_ "GenSigTimeoutTime_SGW" SG_ 2561127498 ManeuverCountAcc 5000;
BA_ "GenSigStartValue" SG_ 2561127498 ManeuverCountAcc 1;
BA_ "CI_SigName" SG_ 2561127498 ManeuverCountAcc "ManeuverCountAcceleration";
BA_ "CI_SigId" SG_ 2561127498 ManeuverCountAcc 14241;
BA_ "CI_ParId" SG_ 2561127498 ManeuverCountAcc "IB1626";
BA_ "SigType" SG_ 2561127498 EventAccelerator 4;
BA_ "GenSigTimeoutTime_SGW" SG_ 2561127498 EventAccelerator 5000;
BA_ "CI_SigName" SG_ 2561127498 EventAccelerator "EventAccelerator";
BA_ "CI_SigId" SG_ 2561127498 EventAccelerator 14240;
BA_ "CI_ParId" SG_ 2561127498 EventAccelerator "IB1625";
BA_ "GenSigTimeoutTime_SGW" SG_ 2561127754 WeightAebs 5000;
BA_ "GenSigStartValue" SG_ 2561127754 WeightAebs 1;
BA_ "CI_SigName" SG_ 2561127754 WeightAebs "WeightAebs";
BA_ "CI_SigId" SG_ 2561127754 WeightAebs 14250;
BA_ "CI_ParId" SG_ 2561127754 WeightAebs "IB1634";
BA_ "SigType" SG_ 2561127754 BenefitAebs 4;
BA_ "GenSigTimeoutTime_SGW" SG_ 2561127754 BenefitAebs 5000;
BA_ "CI_SigName" SG_ 2561127754 BenefitAebs "BenefitAebs";
BA_ "CI_SigId" SG_ 2561127754 BenefitAebs 14249;
BA_ "CI_ParId" SG_ 2561127754 BenefitAebs "IB1633";
BA_ "GenSigTimeoutTime_SGW" SG_ 2561127754 TrendAebs 5000;
BA_ "GenSigStartValue" SG_ 2561127754 TrendAebs 1;
BA_ "CI_SigName" SG_ 2561127754 TrendAebs "TrendAebs";
BA_ "CI_SigId" SG_ 2561127754 TrendAebs 14248;
BA_ "CI_ParId" SG_ 2561127754 TrendAebs "IB1632";
BA_ "SigType" SG_ 2561127754 ValidAebs 4;
BA_ "GenSigTimeoutTime_SGW" SG_ 2561127754 ValidAebs 5000;
BA_ "CI_SigName" SG_ 2561127754 ValidAebs "ValidAebs";
BA_ "CI_SigId" SG_ 2561127754 ValidAebs 14247;
BA_ "CI_ParId" SG_ 2561127754 ValidAebs "IB1631";
BA_ "GenSigTimeoutTime_SGW" SG_ 2561127754 ScoreAebs 5000;
BA_ "GenSigStartValue" SG_ 2561127754 ScoreAebs 1;
BA_ "CI_SigName" SG_ 2561127754 ScoreAebs "ScoreAebs";
BA_ "CI_SigId" SG_ 2561127754 ScoreAebs 14246;
BA_ "CI_ParId" SG_ 2561127754 ScoreAebs "IB1630";
BA_ "SigType" SG_ 2561128010 EventAebs 4;
BA_ "GenSigTimeoutTime_SGW" SG_ 2561128010 EventAebs 5000;
BA_ "CI_SigName" SG_ 2561128010 EventAebs "EventAebs";
BA_ "CI_SigId" SG_ 2561128010 EventAebs 14253;
BA_ "CI_ParId" SG_ 2561128010 EventAebs "IB1636";
BA_ "GenSigTimeoutTime_SGW" SG_ 2561128010 EvaluatedSamplesAebs 5000;
BA_ "GenSigStartValue" SG_ 2561128010 EvaluatedSamplesAebs 1;
BA_ "CI_SigName" SG_ 2561128010 EvaluatedSamplesAebs "EvaluatedSamplesAebs";
BA_ "CI_SigId" SG_ 2561128010 EvaluatedSamplesAebs 14252;
BA_ "CI_ParId" SG_ 2561128010 EvaluatedSamplesAebs "IB1635";
BA_ "GenSigTimeoutTime_SGW" SG_ 2561128266 WeightAirC 5000;
BA_ "GenSigStartValue" SG_ 2561128266 WeightAirC 1;
BA_ "CI_SigName" SG_ 2561128266 WeightAirC "WeightAirC";
BA_ "CI_SigId" SG_ 2561128266 WeightAirC 14259;
BA_ "CI_ParId" SG_ 2561128266 WeightAirC "IB1641";
BA_ "SigType" SG_ 2561128266 BenefitAirC 4;
BA_ "GenSigTimeoutTime_SGW" SG_ 2561128266 BenefitAirC 5000;
BA_ "CI_SigName" SG_ 2561128266 BenefitAirC "BenefitAirC";
BA_ "CI_SigId" SG_ 2561128266 BenefitAirC 14258;
BA_ "CI_ParId" SG_ 2561128266 BenefitAirC "IB1640";
BA_ "GenSigTimeoutTime_SGW" SG_ 2561128266 TrendAirC 5000;
BA_ "GenSigStartValue" SG_ 2561128266 TrendAirC 1;
BA_ "CI_SigName" SG_ 2561128266 TrendAirC "TrendAirC";
BA_ "CI_SigId" SG_ 2561128266 TrendAirC 14257;
BA_ "CI_ParId" SG_ 2561128266 TrendAirC "IB1639";
BA_ "SigType" SG_ 2561128266 ValidAirC 4;
BA_ "GenSigTimeoutTime_SGW" SG_ 2561128266 ValidAirC 5000;
BA_ "CI_SigName" SG_ 2561128266 ValidAirC "ValidAirC";
BA_ "CI_SigId" SG_ 2561128266 ValidAirC 14256;
BA_ "CI_ParId" SG_ 2561128266 ValidAirC "IB1638";
BA_ "GenSigTimeoutTime_SGW" SG_ 2561128266 ScoreAirC 5000;
BA_ "GenSigStartValue" SG_ 2561128266 ScoreAirC 1;
BA_ "CI_SigName" SG_ 2561128266 ScoreAirC "ScoreAirC";
BA_ "CI_SigId" SG_ 2561128266 ScoreAirC 14255;
BA_ "CI_ParId" SG_ 2561128266 ScoreAirC "IB1637";
BA_ "GenSigTimeoutTime_SGW" SG_ 2561128522 EvaluatedSamplesAirC 5000;
BA_ "GenSigStartValue" SG_ 2561128522 EvaluatedSamplesAirC 1;
BA_ "CI_SigName" SG_ 2561128522 EvaluatedSamplesAirC "EvaluatedSamplesAirC";
BA_ "CI_SigId" SG_ 2561128522 EvaluatedSamplesAirC 14261;
BA_ "CI_ParId" SG_ 2561128522 EvaluatedSamplesAirC "IB1642";
BA_ "GenSigTimeoutTime_SGW" SG_ 2561144138 WeightAttention 5000;
BA_ "GenSigStartValue" SG_ 2561144138 WeightAttention 1;
BA_ "CI_SigName" SG_ 2561144138 WeightAttention "WeightAttention";
BA_ "CI_SigId" SG_ 2561144138 WeightAttention 14267;
BA_ "CI_ParId" SG_ 2561144138 WeightAttention "IB1647";
BA_ "SigType" SG_ 2561144138 BenefitAttention 4;
BA_ "GenSigTimeoutTime_SGW" SG_ 2561144138 BenefitAttention 5000;
BA_ "CI_SigName" SG_ 2561144138 BenefitAttention "BenefitAttention";
BA_ "CI_SigId" SG_ 2561144138 BenefitAttention 14266;
BA_ "CI_ParId" SG_ 2561144138 BenefitAttention "IB1646";
BA_ "GenSigTimeoutTime_SGW" SG_ 2561144138 TrendAttention 5000;
BA_ "GenSigStartValue" SG_ 2561144138 TrendAttention 1;
BA_ "CI_SigName" SG_ 2561144138 TrendAttention "TrendAttention";
BA_ "CI_SigId" SG_ 2561144138 TrendAttention 14265;
BA_ "CI_ParId" SG_ 2561144138 TrendAttention "IB1645";
BA_ "SigType" SG_ 2561144138 ValidAttention 4;
BA_ "GenSigTimeoutTime_SGW" SG_ 2561144138 ValidAttention 5000;
BA_ "CI_SigName" SG_ 2561144138 ValidAttention "ValidAttention";
BA_ "CI_SigId" SG_ 2561144138 ValidAttention 14264;
BA_ "CI_ParId" SG_ 2561144138 ValidAttention "IB1644";
BA_ "GenSigTimeoutTime_SGW" SG_ 2561144138 ScoreAttention 5000;
BA_ "GenSigStartValue" SG_ 2561144138 ScoreAttention 1;
BA_ "CI_SigName" SG_ 2561144138 ScoreAttention "ScoreAttention";
BA_ "CI_SigId" SG_ 2561144138 ScoreAttention 14263;
BA_ "CI_ParId" SG_ 2561144138 ScoreAttention "IB1643";
BA_ "GenSigTimeoutTime_SGW" SG_ 2561128778 WeightAuxBrake 5000;
BA_ "GenSigStartValue" SG_ 2561128778 WeightAuxBrake 1;
BA_ "CI_SigName" SG_ 2561128778 WeightAuxBrake "WeightAuxBrake";
BA_ "CI_SigId" SG_ 2561128778 WeightAuxBrake 14273;
BA_ "CI_ParId" SG_ 2561128778 WeightAuxBrake "IB1652";
BA_ "SigType" SG_ 2561128778 BenefitAuxBrake 4;
BA_ "GenSigTimeoutTime_SGW" SG_ 2561128778 BenefitAuxBrake 5000;
BA_ "CI_SigName" SG_ 2561128778 BenefitAuxBrake "BenefitAuxBrake";
BA_ "CI_SigId" SG_ 2561128778 BenefitAuxBrake 14272;
BA_ "CI_ParId" SG_ 2561128778 BenefitAuxBrake "IB1651";
BA_ "GenSigTimeoutTime_SGW" SG_ 2561128778 TrendAuxBrake 5000;
BA_ "GenSigStartValue" SG_ 2561128778 TrendAuxBrake 1;
BA_ "CI_SigName" SG_ 2561128778 TrendAuxBrake "TrendAuxBrake";
BA_ "CI_SigId" SG_ 2561128778 TrendAuxBrake 14271;
BA_ "CI_ParId" SG_ 2561128778 TrendAuxBrake "IB1650";
BA_ "SigType" SG_ 2561128778 ValidAuxBrake 4;
BA_ "GenSigTimeoutTime_SGW" SG_ 2561128778 ValidAuxBrake 5000;
BA_ "CI_SigName" SG_ 2561128778 ValidAuxBrake "ValidAuxBrake";
BA_ "CI_SigId" SG_ 2561128778 ValidAuxBrake 14270;
BA_ "CI_ParId" SG_ 2561128778 ValidAuxBrake "IB1649";
BA_ "GenSigTimeoutTime_SGW" SG_ 2561128778 ScoreAuxBrake 5000;
BA_ "GenSigStartValue" SG_ 2561128778 ScoreAuxBrake 1;
BA_ "CI_SigName" SG_ 2561128778 ScoreAuxBrake "ScoreAuxBrake";
BA_ "CI_SigId" SG_ 2561128778 ScoreAuxBrake 14269;
BA_ "CI_ParId" SG_ 2561128778 ScoreAuxBrake "IB1648";
BA_ "SigType" SG_ 2561129034 EventAuxBrake 4;
BA_ "GenSigTimeoutTime_SGW" SG_ 2561129034 EventAuxBrake 5000;
BA_ "CI_SigName" SG_ 2561129034 EventAuxBrake "EventAuxBrake";
BA_ "CI_SigId" SG_ 2561129034 EventAuxBrake 14281;
BA_ "CI_ParId" SG_ 2561129034 EventAuxBrake "IB1659";
BA_ "GenSigTimeoutTime_SGW" SG_ 2561129034 AuxBrakeActive 5000;
BA_ "CI_SigName" SG_ 2561129034 AuxBrakeActive "AuxBrakeActive";
BA_ "CI_SigId" SG_ 2561129034 AuxBrakeActive 14280;
BA_ "CI_ParId" SG_ 2561129034 AuxBrakeActive "IB1658";
BA_ "SigType" SG_ 2561129034 ManeuverServiceBrakeDistance 1;
BA_ "GenSigTimeoutTime_SGW" SG_ 2561129034 ManeuverServiceBrakeDistance 5000;
BA_ "CI_SigName" SG_ 2561129034 ManeuverServiceBrakeDistance "ManeuverServiceBrakeDistance";
BA_ "CI_SigId" SG_ 2561129034 ManeuverServiceBrakeDistance 14279;
BA_ "CI_ParId" SG_ 2561129034 ManeuverServiceBrakeDistance "IB1657";
BA_ "SigType" SG_ 2561129034 ManeuverDistance 1;
BA_ "GenSigTimeoutTime_SGW" SG_ 2561129034 ManeuverDistance 5000;
BA_ "GenSigStartValue" SG_ 2561129034 ManeuverDistance 1;
BA_ "CI_SigName" SG_ 2561129034 ManeuverDistance "ManeuverDistance";
BA_ "CI_SigId" SG_ 2561129034 ManeuverDistance 14278;
BA_ "CI_ParId" SG_ 2561129034 ManeuverDistance "IB1656";
BA_ "SigType" SG_ 2561129034 TotalBrakingDistance 1;
BA_ "GenSigTimeoutTime_SGW" SG_ 2561129034 TotalBrakingDistance 5000;
BA_ "GenSigStartValue" SG_ 2561129034 TotalBrakingDistance 1;
BA_ "CI_SigName" SG_ 2561129034 TotalBrakingDistance "TotalBrakingDistance";
BA_ "CI_SigId" SG_ 2561129034 TotalBrakingDistance 14277;
BA_ "CI_ParId" SG_ 2561129034 TotalBrakingDistance "IB1655";
BA_ "GenSigTimeoutTime_SGW" SG_ 2561129034 Ratio 5000;
BA_ "GenSigStartValue" SG_ 2561129034 Ratio 10;
BA_ "CI_SigName" SG_ 2561129034 Ratio "Ratio";
BA_ "CI_SigId" SG_ 2561129034 Ratio 14276;
BA_ "CI_ParId" SG_ 2561129034 Ratio "IB1654";
BA_ "GenSigTimeoutTime_SGW" SG_ 2561129034 LastManeuverScoreAuxBrake 5000;
BA_ "GenSigStartValue" SG_ 2561129034 LastManeuverScoreAuxBrake 1;
BA_ "CI_SigName" SG_ 2561129034 LastManeuverScoreAuxBrake "LastManeuverScoreAuxBrake";
BA_ "CI_SigId" SG_ 2561129034 LastManeuverScoreAuxBrake 14275;
BA_ "CI_ParId" SG_ 2561129034 LastManeuverScoreAuxBrake "IB1653";
BA_ "GenSigTimeoutTime_SGW" SG_ 2561145930 WeightBsis 5000;
BA_ "GenSigStartValue" SG_ 2561145930 WeightBsis 1;
BA_ "CI_SigName" SG_ 2561145930 WeightBsis "WeightBsis";
BA_ "CI_SigId" SG_ 2561145930 WeightBsis 14287;
BA_ "CI_ParId" SG_ 2561145930 WeightBsis "IB1664";
BA_ "SigType" SG_ 2561145930 BenefitBsis 4;
BA_ "GenSigTimeoutTime_SGW" SG_ 2561145930 BenefitBsis 5000;
BA_ "CI_SigName" SG_ 2561145930 BenefitBsis "BenefitBsis";
BA_ "CI_SigId" SG_ 2561145930 BenefitBsis 14286;
BA_ "CI_ParId" SG_ 2561145930 BenefitBsis "IB1663";
BA_ "GenSigTimeoutTime_SGW" SG_ 2561145930 TrendBsis 5000;
BA_ "GenSigStartValue" SG_ 2561145930 TrendBsis 1;
BA_ "CI_SigName" SG_ 2561145930 TrendBsis "TrendBsis";
BA_ "CI_SigId" SG_ 2561145930 TrendBsis 14285;
BA_ "CI_ParId" SG_ 2561145930 TrendBsis "IB1662";
BA_ "SigType" SG_ 2561145930 ValidBsis 4;
BA_ "GenSigTimeoutTime_SGW" SG_ 2561145930 ValidBsis 5000;
BA_ "CI_SigName" SG_ 2561145930 ValidBsis "ValidBsis";
BA_ "CI_SigId" SG_ 2561145930 ValidBsis 14284;
BA_ "CI_ParId" SG_ 2561145930 ValidBsis "IB1661";
BA_ "GenSigTimeoutTime_SGW" SG_ 2561145930 ScoreBsis 5000;
BA_ "GenSigStartValue" SG_ 2561145930 ScoreBsis 1;
BA_ "CI_SigName" SG_ 2561145930 ScoreBsis "ScoreBsis";
BA_ "CI_SigId" SG_ 2561145930 ScoreBsis 14283;
BA_ "CI_ParId" SG_ 2561145930 ScoreBsis "IB1660";
BA_ "GenSigTimeoutTime_SGW" SG_ 2561129290 WeightCare 5000;
BA_ "GenSigStartValue" SG_ 2561129290 WeightCare 1;
BA_ "CI_SigName" SG_ 2561129290 WeightCare "WeightCare";
BA_ "CI_SigId" SG_ 2561129290 WeightCare 14293;
BA_ "CI_ParId" SG_ 2561129290 WeightCare "IB1669";
BA_ "SigType" SG_ 2561129290 BenefitCare 4;
BA_ "GenSigTimeoutTime_SGW" SG_ 2561129290 BenefitCare 5000;
BA_ "CI_SigName" SG_ 2561129290 BenefitCare "BenefitCare";
BA_ "CI_SigId" SG_ 2561129290 BenefitCare 14292;
BA_ "CI_ParId" SG_ 2561129290 BenefitCare "IB1668";
BA_ "GenSigTimeoutTime_SGW" SG_ 2561129290 TrendCare 5000;
BA_ "GenSigStartValue" SG_ 2561129290 TrendCare 1;
BA_ "CI_SigName" SG_ 2561129290 TrendCare "TrendCare";
BA_ "CI_SigId" SG_ 2561129290 TrendCare 14291;
BA_ "CI_ParId" SG_ 2561129290 TrendCare "IB1667";
BA_ "SigType" SG_ 2561129290 ValidCare 4;
BA_ "GenSigTimeoutTime_SGW" SG_ 2561129290 ValidCare 5000;
BA_ "CI_SigName" SG_ 2561129290 ValidCare "ValidCare";
BA_ "CI_SigId" SG_ 2561129290 ValidCare 14290;
BA_ "CI_ParId" SG_ 2561129290 ValidCare "IB1666";
BA_ "GenSigTimeoutTime_SGW" SG_ 2561129290 ScoreCare 5000;
BA_ "GenSigStartValue" SG_ 2561129290 ScoreCare 1;
BA_ "CI_SigName" SG_ 2561129290 ScoreCare "ScoreCare";
BA_ "CI_SigId" SG_ 2561129290 ScoreCare 14289;
BA_ "CI_ParId" SG_ 2561129290 ScoreCare "IB1665";
BA_ "SigType" SG_ 2561129546 ResetEcoB 4;
BA_ "GenSigTimeoutTime_SGW" SG_ 2561129546 ResetEcoB 5000;
BA_ "CI_SigName" SG_ 2561129546 ResetEcoB "ResetEcoB";
BA_ "CI_SigId" SG_ 2561129546 ResetEcoB 14296;
BA_ "CI_ParId" SG_ 2561129546 ResetEcoB "IB1671";
BA_ "SigType" SG_ 2561129546 ResetEcoA 4;
BA_ "GenSigTimeoutTime_SGW" SG_ 2561129546 ResetEcoA 5000;
BA_ "CI_SigName" SG_ 2561129546 ResetEcoA "ResetEcoA";
BA_ "CI_SigId" SG_ 2561129546 ResetEcoA 14295;
BA_ "CI_ParId" SG_ 2561129546 ResetEcoA "IB1670";
BA_ "GenSigTimeoutTime_SGW" SG_ 2561130058 WeightComfort 5000;
BA_ "GenSigStartValue" SG_ 2561130058 WeightComfort 1;
BA_ "CI_SigName" SG_ 2561130058 WeightComfort "WeightComfort";
BA_ "CI_SigId" SG_ 2561130058 WeightComfort 14302;
BA_ "CI_ParId" SG_ 2561130058 WeightComfort "IB1676";
BA_ "SigType" SG_ 2561130058 BenefitComfort 4;
BA_ "GenSigTimeoutTime_SGW" SG_ 2561130058 BenefitComfort 5000;
BA_ "CI_SigName" SG_ 2561130058 BenefitComfort "BenefitComfort";
BA_ "CI_SigId" SG_ 2561130058 BenefitComfort 14301;
BA_ "CI_ParId" SG_ 2561130058 BenefitComfort "IB1675";
BA_ "GenSigTimeoutTime_SGW" SG_ 2561130058 TrendComfort 5000;
BA_ "GenSigStartValue" SG_ 2561130058 TrendComfort 1;
BA_ "CI_SigName" SG_ 2561130058 TrendComfort "TrendComfort";
BA_ "CI_SigId" SG_ 2561130058 TrendComfort 14300;
BA_ "CI_ParId" SG_ 2561130058 TrendComfort "IB1674";
BA_ "SigType" SG_ 2561130058 ValidComfort 4;
BA_ "GenSigTimeoutTime_SGW" SG_ 2561130058 ValidComfort 5000;
BA_ "CI_SigName" SG_ 2561130058 ValidComfort "ValidComfort";
BA_ "CI_SigId" SG_ 2561130058 ValidComfort 14299;
BA_ "CI_ParId" SG_ 2561130058 ValidComfort "IB1673";
BA_ "GenSigTimeoutTime_SGW" SG_ 2561130058 ScoreComfort 5000;
BA_ "CI_SigName" SG_ 2561130058 ScoreComfort "ScoreComfort";
BA_ "CI_SigId" SG_ 2561130058 ScoreComfort 14298;
BA_ "CI_ParId" SG_ 2561130058 ScoreComfort "IB1672";
BA_ "SigType" SG_ 2561129802 TimeStampCurrent 1;
BA_ "GenSigTimeoutTime_SGW" SG_ 2561129802 TimeStampCurrent 5000;
BA_ "CI_SigName" SG_ 2561129802 TimeStampCurrent "TimeStampCurrent";
BA_ "CI_SigId" SG_ 2561129802 TimeStampCurrent 14305;
BA_ "CI_ParId" SG_ 2561129802 TimeStampCurrent "IB1678";
BA_ "SigType" SG_ 2561129802 OdometerTripCurrent 1;
BA_ "GenSigTimeoutTime_SGW" SG_ 2561129802 OdometerTripCurrent 5000;
BA_ "CI_SigName" SG_ 2561129802 OdometerTripCurrent "OdometerTripCurrent";
BA_ "CI_SigId" SG_ 2561129802 OdometerTripCurrent 14304;
BA_ "CI_ParId" SG_ 2561129802 OdometerTripCurrent "IB1677";
BA_ "GenSigTimeoutTime_SGW" SG_ 2561130314 WeightDas 5000;
BA_ "GenSigStartValue" SG_ 2561130314 WeightDas 1;
BA_ "CI_SigName" SG_ 2561130314 WeightDas "WeightDas";
BA_ "CI_SigId" SG_ 2561130314 WeightDas 14311;
BA_ "CI_ParId" SG_ 2561130314 WeightDas "IB1683";
BA_ "SigType" SG_ 2561130314 BenefitDas 4;
BA_ "GenSigTimeoutTime_SGW" SG_ 2561130314 BenefitDas 5000;
BA_ "CI_SigName" SG_ 2561130314 BenefitDas "BenefitDas";
BA_ "CI_SigId" SG_ 2561130314 BenefitDas 14310;
BA_ "CI_ParId" SG_ 2561130314 BenefitDas "IB1682";
BA_ "GenSigTimeoutTime_SGW" SG_ 2561130314 TrendDas 5000;
BA_ "GenSigStartValue" SG_ 2561130314 TrendDas 1;
BA_ "CI_SigName" SG_ 2561130314 TrendDas "TrendDas";
BA_ "CI_SigId" SG_ 2561130314 TrendDas 14309;
BA_ "CI_ParId" SG_ 2561130314 TrendDas "IB1681";
BA_ "SigType" SG_ 2561130314 ValidDas 4;
BA_ "GenSigTimeoutTime_SGW" SG_ 2561130314 ValidDas 5000;
BA_ "CI_SigName" SG_ 2561130314 ValidDas "ValidDas";
BA_ "CI_SigId" SG_ 2561130314 ValidDas 14308;
BA_ "CI_ParId" SG_ 2561130314 ValidDas "IB1680";
BA_ "GenSigTimeoutTime_SGW" SG_ 2561130314 ScoreDas 5000;
BA_ "GenSigStartValue" SG_ 2561130314 ScoreDas 1;
BA_ "CI_SigName" SG_ 2561130314 ScoreDas "ScoreDas";
BA_ "CI_SigId" SG_ 2561130314 ScoreDas 14307;
BA_ "CI_ParId" SG_ 2561130314 ScoreDas "IB1679";
BA_ "SigType" SG_ 2561140554 EventDas 4;
BA_ "GenSigTimeoutTime_SGW" SG_ 2561140554 EventDas 5000;
BA_ "CI_SigName" SG_ 2561140554 EventDas "EventDas";
BA_ "CI_SigId" SG_ 2561140554 EventDas 14314;
BA_ "CI_ParId" SG_ 2561140554 EventDas "IB1685";
BA_ "GenSigTimeoutTime_SGW" SG_ 2561140554 EvaluatedSamplesDas 5000;
BA_ "GenSigStartValue" SG_ 2561140554 EvaluatedSamplesDas 1;
BA_ "CI_SigName" SG_ 2561140554 EvaluatedSamplesDas "EvaluatedSamplesDas";
BA_ "CI_SigId" SG_ 2561140554 EvaluatedSamplesDas 14313;
BA_ "CI_ParId" SG_ 2561140554 EvaluatedSamplesDas "IB1684";
BA_ "GenSigTimeoutTime_SGW" SG_ 2561130570 WeightDeceleration 5000;
BA_ "GenSigStartValue" SG_ 2561130570 WeightDeceleration 1;
BA_ "CI_SigName" SG_ 2561130570 WeightDeceleration "WeightDeceleration";
BA_ "CI_SigId" SG_ 2561130570 WeightDeceleration 14320;
BA_ "CI_ParId" SG_ 2561130570 WeightDeceleration "IB1690";
BA_ "SigType" SG_ 2561130570 BenefitDeceleration 4;
BA_ "GenSigTimeoutTime_SGW" SG_ 2561130570 BenefitDeceleration 5000;
BA_ "CI_SigName" SG_ 2561130570 BenefitDeceleration "BenefitDeceleration";
BA_ "CI_SigId" SG_ 2561130570 BenefitDeceleration 14319;
BA_ "CI_ParId" SG_ 2561130570 BenefitDeceleration "IB1689";
BA_ "GenSigTimeoutTime_SGW" SG_ 2561130570 TrendDeceleration 5000;
BA_ "GenSigStartValue" SG_ 2561130570 TrendDeceleration 1;
BA_ "CI_SigName" SG_ 2561130570 TrendDeceleration "TrendDeceleration";
BA_ "CI_SigId" SG_ 2561130570 TrendDeceleration 14318;
BA_ "CI_ParId" SG_ 2561130570 TrendDeceleration "IB1688";
BA_ "SigType" SG_ 2561130570 ValidDeceleration 4;
BA_ "GenSigTimeoutTime_SGW" SG_ 2561130570 ValidDeceleration 5000;
BA_ "CI_SigName" SG_ 2561130570 ValidDeceleration "ValidDeceleration";
BA_ "CI_SigId" SG_ 2561130570 ValidDeceleration 14317;
BA_ "CI_ParId" SG_ 2561130570 ValidDeceleration "IB1687";
BA_ "GenSigTimeoutTime_SGW" SG_ 2561130570 ScoreDeceleration 5000;
BA_ "GenSigStartValue" SG_ 2561130570 ScoreDeceleration 1;
BA_ "CI_SigName" SG_ 2561130570 ScoreDeceleration "ScoreDeceleration";
BA_ "CI_SigId" SG_ 2561130570 ScoreDeceleration 14316;
BA_ "CI_ParId" SG_ 2561130570 ScoreDeceleration "IB1686";
BA_ "GenSigTimeoutTime_SGW" SG_ 2561143882 WeightDriverAwareness 5000;
BA_ "GenSigStartValue" SG_ 2561143882 WeightDriverAwareness 1;
BA_ "CI_SigName" SG_ 2561143882 WeightDriverAwareness "WeightDriverAwareness";
BA_ "CI_SigId" SG_ 2561143882 WeightDriverAwareness 14326;
BA_ "CI_ParId" SG_ 2561143882 WeightDriverAwareness "IB1695";
BA_ "SigType" SG_ 2561143882 BenefitDriverAwareness 4;
BA_ "GenSigTimeoutTime_SGW" SG_ 2561143882 BenefitDriverAwareness 5000;
BA_ "CI_SigName" SG_ 2561143882 BenefitDriverAwareness "BenefitDriverAwareness";
BA_ "CI_SigId" SG_ 2561143882 BenefitDriverAwareness 14325;
BA_ "CI_ParId" SG_ 2561143882 BenefitDriverAwareness "IB1694";
BA_ "GenSigTimeoutTime_SGW" SG_ 2561143882 TrendDriverAwareness 5000;
BA_ "GenSigStartValue" SG_ 2561143882 TrendDriverAwareness 1;
BA_ "CI_SigName" SG_ 2561143882 TrendDriverAwareness "TrendDriverAwareness";
BA_ "CI_SigId" SG_ 2561143882 TrendDriverAwareness 14324;
BA_ "CI_ParId" SG_ 2561143882 TrendDriverAwareness "IB1693";
BA_ "SigType" SG_ 2561143882 ValidDriverAwareness 4;
BA_ "GenSigTimeoutTime_SGW" SG_ 2561143882 ValidDriverAwareness 5000;
BA_ "CI_SigName" SG_ 2561143882 ValidDriverAwareness "ValidDriverAwareness";
BA_ "CI_SigId" SG_ 2561143882 ValidDriverAwareness 14323;
BA_ "CI_ParId" SG_ 2561143882 ValidDriverAwareness "IB1692";
BA_ "GenSigTimeoutTime_SGW" SG_ 2561143882 ScoreDriverAwareness 5000;
BA_ "GenSigStartValue" SG_ 2561143882 ScoreDriverAwareness 1;
BA_ "CI_SigName" SG_ 2561143882 ScoreDriverAwareness "ScoreDriverAwareness";
BA_ "CI_SigId" SG_ 2561143882 ScoreDriverAwareness 14322;
BA_ "CI_ParId" SG_ 2561143882 ScoreDriverAwareness "IB1691";
BA_ "GenSigTimeoutTime_SGW" SG_ 2561130826 WeightEcoMode 5000;
BA_ "GenSigStartValue" SG_ 2561130826 WeightEcoMode 1;
BA_ "CI_SigName" SG_ 2561130826 WeightEcoMode "WeightEcoMode";
BA_ "CI_SigId" SG_ 2561130826 WeightEcoMode 14332;
BA_ "CI_ParId" SG_ 2561130826 WeightEcoMode "IB1700";
BA_ "SigType" SG_ 2561130826 BenefitEcoMode 4;
BA_ "GenSigTimeoutTime_SGW" SG_ 2561130826 BenefitEcoMode 5000;
BA_ "CI_SigName" SG_ 2561130826 BenefitEcoMode "BenefitEcoMode";
BA_ "CI_SigId" SG_ 2561130826 BenefitEcoMode 14331;
BA_ "CI_ParId" SG_ 2561130826 BenefitEcoMode "IB1699";
BA_ "GenSigTimeoutTime_SGW" SG_ 2561130826 TrendEcoMode 5000;
BA_ "GenSigStartValue" SG_ 2561130826 TrendEcoMode 1;
BA_ "CI_SigName" SG_ 2561130826 TrendEcoMode "TrendEcoMode";
BA_ "CI_SigId" SG_ 2561130826 TrendEcoMode 14330;
BA_ "CI_ParId" SG_ 2561130826 TrendEcoMode "IB1698";
BA_ "SigType" SG_ 2561130826 ValidEcoMode 4;
BA_ "GenSigTimeoutTime_SGW" SG_ 2561130826 ValidEcoMode 5000;
BA_ "CI_SigName" SG_ 2561130826 ValidEcoMode "ValidEcoMode";
BA_ "CI_SigId" SG_ 2561130826 ValidEcoMode 14329;
BA_ "CI_ParId" SG_ 2561130826 ValidEcoMode "IB1697";
BA_ "GenSigTimeoutTime_SGW" SG_ 2561130826 ScoreEcoMode 5000;
BA_ "GenSigStartValue" SG_ 2561130826 ScoreEcoMode 1;
BA_ "CI_SigName" SG_ 2561130826 ScoreEcoMode "ScoreEcoMode";
BA_ "CI_SigId" SG_ 2561130826 ScoreEcoMode 14328;
BA_ "CI_ParId" SG_ 2561130826 ScoreEcoMode "IB1696";
BA_ "GenSigTimeoutTime_SGW" SG_ 2561131082 EvaluatedSamplesEcoMode 5000;
BA_ "GenSigStartValue" SG_ 2561131082 EvaluatedSamplesEcoMode 1;
BA_ "CI_SigName" SG_ 2561131082 EvaluatedSamplesEcoMode "EvaluatedSamplesEcoMode";
BA_ "CI_SigId" SG_ 2561131082 EvaluatedSamplesEcoMode 14334;
BA_ "CI_ParId" SG_ 2561131082 EvaluatedSamplesEcoMode "IB1701";
BA_ "GenSigTimeoutTime_SGW" SG_ 2561131338 WeightEngineUse 5000;
BA_ "GenSigStartValue" SG_ 2561131338 WeightEngineUse 1;
BA_ "CI_SigName" SG_ 2561131338 WeightEngineUse "WeightEngineUse";
BA_ "CI_SigId" SG_ 2561131338 WeightEngineUse 14340;
BA_ "CI_ParId" SG_ 2561131338 WeightEngineUse "IB1706";
BA_ "SigType" SG_ 2561131338 BenefitEngineUse 4;
BA_ "GenSigTimeoutTime_SGW" SG_ 2561131338 BenefitEngineUse 5000;
BA_ "CI_SigName" SG_ 2561131338 BenefitEngineUse "BenefitEngineUse";
BA_ "CI_SigId" SG_ 2561131338 BenefitEngineUse 14339;
BA_ "CI_ParId" SG_ 2561131338 BenefitEngineUse "IB1705";
BA_ "GenSigTimeoutTime_SGW" SG_ 2561131338 TrendEngineUse 5000;
BA_ "GenSigStartValue" SG_ 2561131338 TrendEngineUse 1;
BA_ "CI_SigName" SG_ 2561131338 TrendEngineUse "TrendEngineUse";
BA_ "CI_SigId" SG_ 2561131338 TrendEngineUse 14338;
BA_ "CI_ParId" SG_ 2561131338 TrendEngineUse "IB1704";
BA_ "SigType" SG_ 2561131338 ValidEngineUse 4;
BA_ "GenSigTimeoutTime_SGW" SG_ 2561131338 ValidEngineUse 5000;
BA_ "CI_SigName" SG_ 2561131338 ValidEngineUse "ValidEngineUse";
BA_ "CI_SigId" SG_ 2561131338 ValidEngineUse 14337;
BA_ "CI_ParId" SG_ 2561131338 ValidEngineUse "IB1703";
BA_ "GenSigTimeoutTime_SGW" SG_ 2561131338 ScoreEngineUse 5000;
BA_ "GenSigStartValue" SG_ 2561131338 ScoreEngineUse 1;
BA_ "CI_SigName" SG_ 2561131338 ScoreEngineUse "ScoreEngineUse";
BA_ "CI_SigId" SG_ 2561131338 ScoreEngineUse 14336;
BA_ "CI_ParId" SG_ 2561131338 ScoreEngineUse "IB1702";
BA_ "GenSigTimeoutTime_SGW" SG_ 2561140810 EvaluatedSamplesTrip 5000;
BA_ "GenSigStartValue" SG_ 2561140810 EvaluatedSamplesTrip 1;
BA_ "CI_SigName" SG_ 2561140810 EvaluatedSamplesTrip "EvaluatedSamplesTrip";
BA_ "CI_SigId" SG_ 2561140810 EvaluatedSamplesTrip 14343;
BA_ "CI_ParId" SG_ 2561140810 EvaluatedSamplesTrip "IB1708";
BA_ "SigType" SG_ 2561140810 EvaluatedMetersTrip 1;
BA_ "GenSigTimeoutTime_SGW" SG_ 2561140810 EvaluatedMetersTrip 5000;
BA_ "GenSigStartValue" SG_ 2561140810 EvaluatedMetersTrip 1;
BA_ "CI_SigName" SG_ 2561140810 EvaluatedMetersTrip "EvaluatedMetersTrip";
BA_ "CI_SigId" SG_ 2561140810 EvaluatedMetersTrip 14342;
BA_ "CI_ParId" SG_ 2561140810 EvaluatedMetersTrip "IB1707";
BA_ "GenSigTimeoutTime_SGW" SG_ 2561131594 WtFuel 2500;
BA_ "GenSigTimeoutTime_IC_MulticS" SG_ 2561131594 WtFuel 2500;
BA_ "GenSigStartValue" SG_ 2561131594 WtFuel 1;
BA_ "CI_SigName" SG_ 2561131594 WtFuel "WeightFuel";
BA_ "CI_SigId" SG_ 2561131594 WtFuel 1911;
BA_ "CI_ParId" SG_ 2561131594 WtFuel "IB795";
BA_ "SigType" SG_ 2561131594 BenfFuel 4;
BA_ "GenSigTimeoutTime_SGW" SG_ 2561131594 BenfFuel 2500;
BA_ "GenSigTimeoutTime_IC_MulticS" SG_ 2561131594 BenfFuel 2500;
BA_ "CI_SigName" SG_ 2561131594 BenfFuel "BenefitFuel";
BA_ "CI_SigId" SG_ 2561131594 BenfFuel 1910;
BA_ "CI_ParId" SG_ 2561131594 BenfFuel "IB794";
BA_ "GenSigTimeoutTime_SGW" SG_ 2561131594 TrendFuel 2500;
BA_ "GenSigTimeoutTime_IC_MulticS" SG_ 2561131594 TrendFuel 2500;
BA_ "GenSigStartValue" SG_ 2561131594 TrendFuel 1;
BA_ "CI_SigName" SG_ 2561131594 TrendFuel "TrendFuel";
BA_ "CI_SigId" SG_ 2561131594 TrendFuel 1909;
BA_ "CI_ParId" SG_ 2561131594 TrendFuel "IB793";
BA_ "SigType" SG_ 2561131594 ValFuel 4;
BA_ "GenSigTimeoutTime_SGW" SG_ 2561131594 ValFuel 2500;
BA_ "GenSigTimeoutTime_IC_MulticS" SG_ 2561131594 ValFuel 2500;
BA_ "CI_SigName" SG_ 2561131594 ValFuel "ValidFuel";
BA_ "CI_SigId" SG_ 2561131594 ValFuel 1908;
BA_ "CI_ParId" SG_ 2561131594 ValFuel "IB792";
BA_ "GenSigTimeoutTime_SGW" SG_ 2561131594 ScoreFuel 2500;
BA_ "GenSigTimeoutTime_IC_MulticS" SG_ 2561131594 ScoreFuel 2500;
BA_ "GenSigTimeoutTime_IC_MulticII" SG_ 2561131594 ScoreFuel 2500;
BA_ "GenSigStartValue" SG_ 2561131594 ScoreFuel 1;
BA_ "CI_SigName" SG_ 2561131594 ScoreFuel "ScoreFuel";
BA_ "CI_SigId" SG_ 2561131594 ScoreFuel 1907;
BA_ "CI_ParId" SG_ 2561131594 ScoreFuel "IB791";
BA_ "GenSigTimeoutTime_SGW" SG_ 2561141834 FuelConsumptionElec 5000;
BA_ "GenSigStartValue" SG_ 2561141834 FuelConsumptionElec 10;
BA_ "CI_SigName" SG_ 2561141834 FuelConsumptionElec "FuelConsumptionElec";
BA_ "CI_SigId" SG_ 2561141834 FuelConsumptionElec 14348;
BA_ "CI_ParId" SG_ 2561141834 FuelConsumptionElec "IB1712";
BA_ "GenSigTimeoutTime_SGW" SG_ 2561141834 FuelConsEstimatDiesel 5000;
BA_ "GenSigStartValue" SG_ 2561141834 FuelConsEstimatDiesel 10;
BA_ "CI_SigName" SG_ 2561141834 FuelConsEstimatDiesel "FuelConsumptionEstimatedDiesel";
BA_ "CI_SigId" SG_ 2561141834 FuelConsEstimatDiesel 14347;
BA_ "CI_ParId" SG_ 2561141834 FuelConsEstimatDiesel "IB1711";
BA_ "GenSigTimeoutTime_SGW" SG_ 2561141834 FuelConsumptionGas 5000;
BA_ "GenSigStartValue" SG_ 2561141834 FuelConsumptionGas 10;
BA_ "CI_SigName" SG_ 2561141834 FuelConsumptionGas "FuelConsumptionGas";
BA_ "CI_SigId" SG_ 2561141834 FuelConsumptionGas 14346;
BA_ "CI_ParId" SG_ 2561141834 FuelConsumptionGas "IB1710";
BA_ "GenSigTimeoutTime_SGW" SG_ 2561141834 FuelConsumptionDiesel 5000;
BA_ "GenSigStartValue" SG_ 2561141834 FuelConsumptionDiesel 10;
BA_ "CI_SigName" SG_ 2561141834 FuelConsumptionDiesel "FuelConsumptionDiesel";
BA_ "CI_SigId" SG_ 2561141834 FuelConsumptionDiesel 14345;
BA_ "CI_ParId" SG_ 2561141834 FuelConsumptionDiesel "IB1709";
BA_ "GenSigTimeoutTime_SGW" SG_ 2561131850 NrSatellites 5000;
BA_ "CI_SigName" SG_ 2561131850 NrSatellites "NrSatellites";
BA_ "CI_SigId" SG_ 2561131850 NrSatellites 14355;
BA_ "CI_ParId" SG_ 2561131850 NrSatellites "IB1718";
BA_ "GenSigTimeoutTime_SGW" SG_ 2561131850 Hdop 5000;
BA_ "CI_SigName" SG_ 2561131850 Hdop "Hdop";
BA_ "CI_SigId" SG_ 2561131850 Hdop 14354;
BA_ "CI_ParId" SG_ 2561131850 Hdop "IB1717";
BA_ "GenSigTimeoutTime_SGW" SG_ 2561131850 Vdop 5000;
BA_ "CI_SigName" SG_ 2561131850 Vdop "Vdop";
BA_ "CI_SigId" SG_ 2561131850 Vdop 14353;
BA_ "CI_ParId" SG_ 2561131850 Vdop "IB1716";
BA_ "GenSigTimeoutTime_SGW" SG_ 2561131850 GPSAltitude 5000;
BA_ "GenSigStartValue" SG_ 2561131850 GPSAltitude 2500;
BA_ "CI_SigName" SG_ 2561131850 GPSAltitude "GPSAltitude";
BA_ "CI_SigId" SG_ 2561131850 GPSAltitude 14352;
BA_ "CI_ParId" SG_ 2561131850 GPSAltitude "IB1715";
BA_ "GenSigTimeoutTime_SGW" SG_ 2561131850 GPSLongitude 5000;
BA_ "CI_SigName" SG_ 2561131850 GPSLongitude "GPSLongitude";
BA_ "CI_SigId" SG_ 2561131850 GPSLongitude 14351;
BA_ "CI_ParId" SG_ 2561131850 GPSLongitude "IB1714";
BA_ "GenSigTimeoutTime_SGW" SG_ 2561131850 GPSLatitude 5000;
BA_ "CI_SigName" SG_ 2561131850 GPSLatitude "GPSLatitude";
BA_ "CI_SigId" SG_ 2561131850 GPSLatitude 14350;
BA_ "CI_ParId" SG_ 2561131850 GPSLatitude "IB1713";
BA_ "GenSigTimeoutTime_SGW" SG_ 2561132106 WeightHandBrake 5000;
BA_ "GenSigStartValue" SG_ 2561132106 WeightHandBrake 1;
BA_ "CI_SigName" SG_ 2561132106 WeightHandBrake "WeightHandBrake";
BA_ "CI_SigId" SG_ 2561132106 WeightHandBrake 14361;
BA_ "CI_ParId" SG_ 2561132106 WeightHandBrake "IB1723";
BA_ "SigType" SG_ 2561132106 BenefitHandBrake 4;
BA_ "GenSigTimeoutTime_SGW" SG_ 2561132106 BenefitHandBrake 5000;
BA_ "CI_SigName" SG_ 2561132106 BenefitHandBrake "BenefitHandBrake";
BA_ "CI_SigId" SG_ 2561132106 BenefitHandBrake 14360;
BA_ "CI_ParId" SG_ 2561132106 BenefitHandBrake "IB1722";
BA_ "GenSigTimeoutTime_SGW" SG_ 2561132106 TrendHandBrake 5000;
BA_ "GenSigStartValue" SG_ 2561132106 TrendHandBrake 1;
BA_ "CI_SigName" SG_ 2561132106 TrendHandBrake "TrendHandBrake";
BA_ "CI_SigId" SG_ 2561132106 TrendHandBrake 14359;
BA_ "CI_ParId" SG_ 2561132106 TrendHandBrake "IB1721";
BA_ "SigType" SG_ 2561132106 ValidHandBrake 4;
BA_ "GenSigTimeoutTime_SGW" SG_ 2561132106 ValidHandBrake 5000;
BA_ "CI_SigName" SG_ 2561132106 ValidHandBrake "ValidHandBrake";
BA_ "CI_SigId" SG_ 2561132106 ValidHandBrake 14358;
BA_ "CI_ParId" SG_ 2561132106 ValidHandBrake "IB1720";
BA_ "GenSigTimeoutTime_SGW" SG_ 2561132106 ScoreHandBrake 5000;
BA_ "GenSigStartValue" SG_ 2561132106 ScoreHandBrake 1;
BA_ "CI_SigName" SG_ 2561132106 ScoreHandBrake "ScoreHandBrake";
BA_ "CI_SigId" SG_ 2561132106 ScoreHandBrake 14357;
BA_ "CI_ParId" SG_ 2561132106 ScoreHandBrake "IB1719";
BA_ "SigType" SG_ 2561132362 EventHandBrake 4;
BA_ "GenSigTimeoutTime_SGW" SG_ 2561132362 EventHandBrake 5000;
BA_ "CI_SigName" SG_ 2561132362 EventHandBrake "EventHandBrake";
BA_ "CI_SigId" SG_ 2561132362 EventHandBrake 14364;
BA_ "CI_ParId" SG_ 2561132362 EventHandBrake "IB1725";
BA_ "GenSigTimeoutTime_SGW" SG_ 2561132362 NumEventsHandBrake 5000;
BA_ "GenSigStartValue" SG_ 2561132362 NumEventsHandBrake 1;
BA_ "CI_SigName" SG_ 2561132362 NumEventsHandBrake "NumEventsHandBrake";
BA_ "CI_SigId" SG_ 2561132362 NumEventsHandBrake 14363;
BA_ "CI_ParId" SG_ 2561132362 NumEventsHandBrake "IB1724";
BA_ "GenSigTimeoutTime_SGW" SG_ 2561132618 WeightHarshBraking 5000;
BA_ "GenSigStartValue" SG_ 2561132618 WeightHarshBraking 1;
BA_ "CI_SigName" SG_ 2561132618 WeightHarshBraking "WeightHarshBraking";
BA_ "CI_SigId" SG_ 2561132618 WeightHarshBraking 14370;
BA_ "CI_ParId" SG_ 2561132618 WeightHarshBraking "IB1730";
BA_ "SigType" SG_ 2561132618 BenefitHarshBraking 4;
BA_ "GenSigTimeoutTime_SGW" SG_ 2561132618 BenefitHarshBraking 5000;
BA_ "CI_SigName" SG_ 2561132618 BenefitHarshBraking "BenefitHarshBraking";
BA_ "CI_SigId" SG_ 2561132618 BenefitHarshBraking 14369;
BA_ "CI_ParId" SG_ 2561132618 BenefitHarshBraking "IB1729";
BA_ "GenSigTimeoutTime_SGW" SG_ 2561132618 TrendHarshBraking 5000;
BA_ "GenSigStartValue" SG_ 2561132618 TrendHarshBraking 1;
BA_ "CI_SigName" SG_ 2561132618 TrendHarshBraking "TrendHarshBraking";
BA_ "CI_SigId" SG_ 2561132618 TrendHarshBraking 14368;
BA_ "CI_ParId" SG_ 2561132618 TrendHarshBraking "IB1728";
BA_ "SigType" SG_ 2561132618 ValidHarshBraking 4;
BA_ "GenSigTimeoutTime_SGW" SG_ 2561132618 ValidHarshBraking 5000;
BA_ "CI_SigName" SG_ 2561132618 ValidHarshBraking "ValidHarshBraking";
BA_ "CI_SigId" SG_ 2561132618 ValidHarshBraking 14367;
BA_ "CI_ParId" SG_ 2561132618 ValidHarshBraking "IB1727";
BA_ "GenSigTimeoutTime_SGW" SG_ 2561132618 ScoreHarshBraking 5000;
BA_ "GenSigStartValue" SG_ 2561132618 ScoreHarshBraking 1;
BA_ "CI_SigName" SG_ 2561132618 ScoreHarshBraking "ScoreHarshBraking";
BA_ "CI_SigId" SG_ 2561132618 ScoreHarshBraking 14366;
BA_ "CI_ParId" SG_ 2561132618 ScoreHarshBraking "IB1726";
BA_ "GenSigTimeoutTime_SGW" SG_ 2561132874 MaxDecelHarshBraking 5000;
BA_ "CI_SigName" SG_ 2561132874 MaxDecelHarshBraking "MaxDecelerationHarshBraking";
BA_ "CI_SigId" SG_ 2561132874 MaxDecelHarshBraking 14374;
BA_ "CI_ParId" SG_ 2561132874 MaxDecelHarshBraking "IB1733";
BA_ "SigType" SG_ 2561132874 EventHarshBraking 4;
BA_ "GenSigTimeoutTime_SGW" SG_ 2561132874 EventHarshBraking 5000;
BA_ "CI_SigName" SG_ 2561132874 EventHarshBraking "EventHarshBraking";
BA_ "CI_SigId" SG_ 2561132874 EventHarshBraking 14373;
BA_ "CI_ParId" SG_ 2561132874 EventHarshBraking "IB1732";
BA_ "SigType" SG_ 2561132874 EvalMetersHarshBraking 1;
BA_ "GenSigTimeoutTime_SGW" SG_ 2561132874 EvalMetersHarshBraking 5000;
BA_ "GenSigStartValue" SG_ 2561132874 EvalMetersHarshBraking 1;
BA_ "CI_SigName" SG_ 2561132874 EvalMetersHarshBraking "EvaluatedMetersHarshBraking";
BA_ "CI_SigId" SG_ 2561132874 EvalMetersHarshBraking 14372;
BA_ "CI_ParId" SG_ 2561132874 EvalMetersHarshBraking "IB1731";
BA_ "GenSigTimeoutTime_SGW" SG_ 2561133130 WeightHarshSteering 5000;
BA_ "GenSigStartValue" SG_ 2561133130 WeightHarshSteering 1;
BA_ "CI_SigName" SG_ 2561133130 WeightHarshSteering "WeightHarshSteering";
BA_ "CI_SigId" SG_ 2561133130 WeightHarshSteering 14380;
BA_ "CI_ParId" SG_ 2561133130 WeightHarshSteering "IB1738";
BA_ "SigType" SG_ 2561133130 BenefitHarshSteering 4;
BA_ "GenSigTimeoutTime_SGW" SG_ 2561133130 BenefitHarshSteering 5000;
BA_ "CI_SigName" SG_ 2561133130 BenefitHarshSteering "BenefitHarshSteering";
BA_ "CI_SigId" SG_ 2561133130 BenefitHarshSteering 14379;
BA_ "CI_ParId" SG_ 2561133130 BenefitHarshSteering "IB1737";
BA_ "GenSigTimeoutTime_SGW" SG_ 2561133130 TrendHarshSteering 5000;
BA_ "GenSigStartValue" SG_ 2561133130 TrendHarshSteering 1;
BA_ "CI_SigName" SG_ 2561133130 TrendHarshSteering "TrendHarshSteering";
BA_ "CI_SigId" SG_ 2561133130 TrendHarshSteering 14378;
BA_ "CI_ParId" SG_ 2561133130 TrendHarshSteering "IB1736";
BA_ "SigType" SG_ 2561133130 ValidHarshSteering 4;
BA_ "GenSigTimeoutTime_SGW" SG_ 2561133130 ValidHarshSteering 5000;
BA_ "CI_SigName" SG_ 2561133130 ValidHarshSteering "ValidHarshSteering";
BA_ "CI_SigId" SG_ 2561133130 ValidHarshSteering 14377;
BA_ "CI_ParId" SG_ 2561133130 ValidHarshSteering "IB1735";
BA_ "GenSigTimeoutTime_SGW" SG_ 2561133130 ScoreHarshSteering 5000;
BA_ "GenSigStartValue" SG_ 2561133130 ScoreHarshSteering 1;
BA_ "CI_SigName" SG_ 2561133130 ScoreHarshSteering "ScoreHarshSteering";
BA_ "CI_SigId" SG_ 2561133130 ScoreHarshSteering 14376;
BA_ "CI_ParId" SG_ 2561133130 ScoreHarshSteering "IB1734";
BA_ "SigType" SG_ 2561133386 EventHarshSteering 4;
BA_ "GenSigTimeoutTime_SGW" SG_ 2561133386 EventHarshSteering 5000;
BA_ "CI_SigName" SG_ 2561133386 EventHarshSteering "EventHarshSteering";
BA_ "CI_SigId" SG_ 2561133386 EventHarshSteering 14383;
BA_ "CI_ParId" SG_ 2561133386 EventHarshSteering "IB1740";
BA_ "SigType" SG_ 2561133386 EvalMetersHarshSteering 1;
BA_ "GenSigTimeoutTime_SGW" SG_ 2561133386 EvalMetersHarshSteering 5000;
BA_ "GenSigStartValue" SG_ 2561133386 EvalMetersHarshSteering 1;
BA_ "CI_SigName" SG_ 2561133386 EvalMetersHarshSteering "EvaluatedMetersHarshSteering";
BA_ "CI_SigId" SG_ 2561133386 EvalMetersHarshSteering 14382;
BA_ "CI_ParId" SG_ 2561133386 EvalMetersHarshSteering "IB1739";
BA_ "GenSigTimeoutTime_SGW" SG_ 2561133898 WeightInertia 5000;
BA_ "GenSigStartValue" SG_ 2561133898 WeightInertia 1;
BA_ "CI_SigName" SG_ 2561133898 WeightInertia "WeightInertia";
BA_ "CI_SigId" SG_ 2561133898 WeightInertia 14389;
BA_ "CI_ParId" SG_ 2561133898 WeightInertia "IB1745";
BA_ "SigType" SG_ 2561133898 BenefitInertia 4;
BA_ "GenSigTimeoutTime_SGW" SG_ 2561133898 BenefitInertia 5000;
BA_ "CI_SigName" SG_ 2561133898 BenefitInertia "BenefitInertia";
BA_ "CI_SigId" SG_ 2561133898 BenefitInertia 14388;
BA_ "CI_ParId" SG_ 2561133898 BenefitInertia "IB1744";
BA_ "GenSigTimeoutTime_SGW" SG_ 2561133898 TrendInertia 5000;
BA_ "GenSigStartValue" SG_ 2561133898 TrendInertia 1;
BA_ "CI_SigName" SG_ 2561133898 TrendInertia "TrendInertia";
BA_ "CI_SigId" SG_ 2561133898 TrendInertia 14387;
BA_ "CI_ParId" SG_ 2561133898 TrendInertia "IB1743";
BA_ "SigType" SG_ 2561133898 ValidInertia 4;
BA_ "GenSigTimeoutTime_SGW" SG_ 2561133898 ValidInertia 5000;
BA_ "CI_SigName" SG_ 2561133898 ValidInertia "ValidInertia";
BA_ "CI_SigId" SG_ 2561133898 ValidInertia 14386;
BA_ "CI_ParId" SG_ 2561133898 ValidInertia "IB1742";
BA_ "GenSigTimeoutTime_SGW" SG_ 2561133898 ScoreInertia 5000;
BA_ "GenSigStartValue" SG_ 2561133898 ScoreInertia 1;
BA_ "CI_SigName" SG_ 2561133898 ScoreInertia "ScoreInertia";
BA_ "CI_SigId" SG_ 2561133898 ScoreInertia 14385;
BA_ "CI_ParId" SG_ 2561133898 ScoreInertia "IB1741";
BA_ "SigType" SG_ 2561134154 PunishingManeuvInertia 4;
BA_ "GenSigTimeoutTime_SGW" SG_ 2561134154 PunishingManeuvInertia 5000;
BA_ "CI_SigName" SG_ 2561134154 PunishingManeuvInertia "PunishingManeuverInertia";
BA_ "CI_SigId" SG_ 2561134154 PunishingManeuvInertia 14399;
BA_ "CI_ParId" SG_ 2561134154 PunishingManeuvInertia "IB1754";
BA_ "SigType" SG_ 2561134154 DangerOfCollisInertia 4;
BA_ "GenSigTimeoutTime_SGW" SG_ 2561134154 DangerOfCollisInertia 5000;
BA_ "CI_SigName" SG_ 2561134154 DangerOfCollisInertia "DangerOfCollisionInertia";
BA_ "CI_SigId" SG_ 2561134154 DangerOfCollisInertia 14398;
BA_ "CI_ParId" SG_ 2561134154 DangerOfCollisInertia "IB1753";
BA_ "SigType" SG_ 2561134154 StartingSpeedInertia 1;
BA_ "GenSigTimeoutTime_SGW" SG_ 2561134154 StartingSpeedInertia 5000;
BA_ "CI_SigName" SG_ 2561134154 StartingSpeedInertia "StartingSpeedInertia";
BA_ "CI_SigId" SG_ 2561134154 StartingSpeedInertia 14397;
BA_ "CI_ParId" SG_ 2561134154 StartingSpeedInertia "IB1752";
BA_ "GenSigTimeoutTime_SGW" SG_ 2561134154 DurationInertia 5000;
BA_ "GenSigStartValue" SG_ 2561134154 DurationInertia 1;
BA_ "CI_SigName" SG_ 2561134154 DurationInertia "DurationInertia";
BA_ "CI_SigId" SG_ 2561134154 DurationInertia 14396;
BA_ "CI_ParId" SG_ 2561134154 DurationInertia "IB1751";
BA_ "GenSigTimeoutTime_SGW" SG_ 2561134154 ManeuverCountInertia 5000;
BA_ "GenSigStartValue" SG_ 2561134154 ManeuverCountInertia 1;
BA_ "CI_SigName" SG_ 2561134154 ManeuverCountInertia "ManeuverCountInertia";
BA_ "CI_SigId" SG_ 2561134154 ManeuverCountInertia 14395;
BA_ "CI_ParId" SG_ 2561134154 ManeuverCountInertia "IB1750";
BA_ "GenSigTimeoutTime_SGW" SG_ 2561134154 EndReasonInertia 5000;
BA_ "CI_SigName" SG_ 2561134154 EndReasonInertia "EndReasonInertia";
BA_ "CI_SigId" SG_ 2561134154 EndReasonInertia 14394;
BA_ "CI_ParId" SG_ 2561134154 EndReasonInertia "IB1749";
BA_ "SigType" SG_ 2561134154 StartReasonInertia 4;
BA_ "GenSigTimeoutTime_SGW" SG_ 2561134154 StartReasonInertia 5000;
BA_ "CI_SigName" SG_ 2561134154 StartReasonInertia "StartReasonInertia";
BA_ "CI_SigId" SG_ 2561134154 StartReasonInertia 14393;
BA_ "CI_ParId" SG_ 2561134154 StartReasonInertia "IB1748";
BA_ "GenSigTimeoutTime_SGW" SG_ 2561134154 EventInertia 5000;
BA_ "CI_SigName" SG_ 2561134154 EventInertia "EventInertia";
BA_ "CI_SigId" SG_ 2561134154 EventInertia 14392;
BA_ "CI_ParId" SG_ 2561134154 EventInertia "IB1747";
BA_ "GenSigTimeoutTime_SGW" SG_ 2561134154 LastManeuverScoreInertia 5000;
BA_ "GenSigStartValue" SG_ 2561134154 LastManeuverScoreInertia 1;
BA_ "CI_SigName" SG_ 2561134154 LastManeuverScoreInertia "LastManeuverScoreInertia";
BA_ "CI_SigId" SG_ 2561134154 LastManeuverScoreInertia 14391;
BA_ "CI_ParId" SG_ 2561134154 LastManeuverScoreInertia "IB1746";
BA_ "GenSigTimeoutTime_SGW" SG_ 2561134410 WeightInertiaPecc 5000;
BA_ "GenSigStartValue" SG_ 2561134410 WeightInertiaPecc 1;
BA_ "CI_SigName" SG_ 2561134410 WeightInertiaPecc "WeightInertiaPecc";
BA_ "CI_SigId" SG_ 2561134410 WeightInertiaPecc 14405;
BA_ "CI_ParId" SG_ 2561134410 WeightInertiaPecc "IB1759";
BA_ "SigType" SG_ 2561134410 BenefitInertiaPecc 4;
BA_ "GenSigTimeoutTime_SGW" SG_ 2561134410 BenefitInertiaPecc 5000;
BA_ "CI_SigName" SG_ 2561134410 BenefitInertiaPecc "BenefitInertiaPecc";
BA_ "CI_SigId" SG_ 2561134410 BenefitInertiaPecc 14404;
BA_ "CI_ParId" SG_ 2561134410 BenefitInertiaPecc "IB1758";
BA_ "GenSigTimeoutTime_SGW" SG_ 2561134410 TrendInertiaPecc 5000;
BA_ "GenSigStartValue" SG_ 2561134410 TrendInertiaPecc 1;
BA_ "CI_SigName" SG_ 2561134410 TrendInertiaPecc "TrendInertiaPecc";
BA_ "CI_SigId" SG_ 2561134410 TrendInertiaPecc 14403;
BA_ "CI_ParId" SG_ 2561134410 TrendInertiaPecc "IB1757";
BA_ "SigType" SG_ 2561134410 ValidInertiaPecc 4;
BA_ "GenSigTimeoutTime_SGW" SG_ 2561134410 ValidInertiaPecc 5000;
BA_ "CI_SigName" SG_ 2561134410 ValidInertiaPecc "ValidInertiaPecc";
BA_ "CI_SigId" SG_ 2561134410 ValidInertiaPecc 14402;
BA_ "CI_ParId" SG_ 2561134410 ValidInertiaPecc "IB1756";
BA_ "GenSigTimeoutTime_SGW" SG_ 2561134410 ScoreInertiaPecc 5000;
BA_ "GenSigStartValue" SG_ 2561134410 ScoreInertiaPecc 1;
BA_ "CI_SigName" SG_ 2561134410 ScoreInertiaPecc "ScoreInertiaPecc";
BA_ "CI_SigId" SG_ 2561134410 ScoreInertiaPecc 14401;
BA_ "CI_ParId" SG_ 2561134410 ScoreInertiaPecc "IB1755";
VAL_ 2566844672 CcSts 0 "Off/Disabled" 1 "Hold" 2 "Accelerate" 3 "Decelerate" 4 "Resume" 5 "Set" 6 "Accelerator Override" 7 "Not Available" ;
VAL_ 2566844672 PtoGovSts 0 "Off/Disabled" 1 "Hold" 2 "Remote Hold" 3 "Standby" 4 "Remote Standby" 5 "Set" 6 "Dec/Coast" 7 "Resume" 8 "Accelerate" 9 "Accelerator Override" 10 "Preprogr. set speed 1" 11 "Preprogr. set speed 2" 12 "Preprogr. set speed 3" 13 "Preprogr. set speed 4" 14 "Preprogr. set speed 5" 15 "Preprogr. set speed 6" 16 "Preprogr. set speed 7" 17 "Preprogr. set speed 8" 18 "Set speed memory 1" 19 "Set speed memory 2" 20 "Set speed memory 3" 30 "Not defined" 31 "Not Available" ;
VAL_ 2566844672 CltSw 0 "Released" 1 "Depressed" 2 "Error" 3 "Not Available" ;
VAL_ 2566844672 BrkSw 0 "Released" 1 "Depressed" 2 "Error" 3 "Not Available" ;
VAL_ 2566844672 CcActv 0 "Off" 1 "On" 2 "Error" 3 "Not Available" ;
VAL_ 2566844672 WhBasedVehSpeed 65024 "Error" 65535 "Not_Available" ;
VAL_ 2566844672 ParkBrkSw 0 "Not set" 1 "Set" 2 "Error" 3 "Not Available" ;
VAL_ 2566865139 CoolSts 0 "No_cooling" 1 "Off" 2 "On" 3 "Refuelling" 4 "Warning" 5 "Error" 6 "Chiller_No_Can" 7 "MaintenChillerManualCirculat" ;
VAL_ 2566802967 Sts2OfDoors 0 "All bus doors are disabled" 1 "At least 1 bus door enabled" 2 "Error" 3 "Not Available" ;
VAL_ 2566802967 Ramp_WhChairLiftPos 0 "Inside bus" 1 "Outside bus" 2 "Error" 3 "Not Available" ;
VAL_ 2566802967 PosOfDoors 0 "At least 1 door is open" 1 "Closing last door" 2 "All doors closed" 14 "Error" 15 "Not Available" ;
VAL_ 2566759703 EnaStsOfDoor10 0 "Door disabled" 1 "Door enabled" 2 "Error" 3 "Not Available" ;
VAL_ 2566759703 OpenStsOfDoor10 0 "Door closed" 1 "Door opened" 2 "Error" 3 "Not Available" ;
VAL_ 2566759703 LckStsOfDoor10 0 "Unlocked" 1 "Locked" 2 "Error" 3 "Not Available" ;
VAL_ 2566759703 EnaStsOfDoor9 0 "Door disabled" 1 "Door enabled" 2 "Error" 3 "Not Available" ;
VAL_ 2566759703 OpenStsOfDoor9 0 "Door closed" 1 "Door opened" 2 "Error" 3 "Not Available" ;
VAL_ 2566759703 LckStsOfDoor9 0 "Unlocked" 1 "Locked" 2 "Error" 3 "Not Available" ;
VAL_ 2566759703 EnaStsOfDoor8 0 "Door disabled" 1 "Door enabled" 2 "Error" 3 "Not Available" ;
VAL_ 2566759703 OpenStsOfDoor8 0 "Door closed" 1 "Door opened" 2 "Error" 3 "Not Available" ;
VAL_ 2566759703 LckStsOfDoor8 0 "Unlocked" 1 "Locked" 2 "Error" 3 "Not Available" ;
VAL_ 2566759703 EnaStsOfDoor7 0 "Door disabled" 1 "Door enabled" 2 "Error" 3 "Not Available" ;
VAL_ 2566759703 OpenStsOfDoor7 0 "Door closed" 1 "Door opened" 2 "Error" 3 "Not Available" ;
VAL_ 2566759703 LckStsOfDoor7 0 "Unlocked" 1 "Locked" 2 "Error" 3 "Not Available" ;
VAL_ 2566759703 EnaStsOfDoor6 0 "Door disabled" 1 "Door enabled" 2 "Error" 3 "Not Available" ;
VAL_ 2566759703 OpenStsOfDoor6 0 "Door closed" 1 "Door opened" 2 "Error" 3 "Not Available" ;
VAL_ 2566759703 LckStsOfDoor6 0 "Unlocked" 1 "Locked" 2 "Error" 3 "Not Available" ;
VAL_ 2566759703 EnaStsOfDoor5 0 "Door disabled" 1 "Door enabled" 2 "Error" 3 "Not Available" ;
VAL_ 2566759703 OpenStsOfDoor5 0 "Door closed" 1 "Door opened" 2 "Error" 3 "Not Available" ;
VAL_ 2566759703 LckStsOfDoor5 0 "Unlocked" 1 "Locked" 2 "Error" 3 "Not Available" ;
VAL_ 2566759703 EnaStsOfDoor4 0 "Door disabled" 1 "Door enabled" 2 "Error" 3 "Not Available" ;
VAL_ 2566759703 OpenStsOfDoor4 0 "Door closed" 1 "Door opened" 2 "Error" 3 "Not Available" ;
VAL_ 2566759703 LckStsOfDoor4 0 "Unlocked" 1 "Locked" 2 "Error" 3 "Not Available" ;
VAL_ 2566759703 EnaStsOfDoor3 0 "Door disabled" 1 "Door enabled" 2 "Error" 3 "Not Available" ;
VAL_ 2566759703 OpenStsOfDoor3 0 "Door closed" 1 "Door opened" 2 "Error" 3 "Not Available" ;
VAL_ 2566759703 LckStsOfDoor3 0 "Unlocked" 1 "Locked" 2 "Error" 3 "Not Available" ;
VAL_ 2566759703 EnaStsOfDoor2 0 "Door disabled" 1 "Door enabled" 2 "Error" 3 "Not Available" ;
VAL_ 2566759703 OpenStsOfDoor2 0 "Door closed" 1 "Door opened" 2 "Error" 3 "Not Available" ;
VAL_ 2566759703 LckStsOfDoor2 0 "Unlocked" 1 "Locked" 2 "Error" 3 "Not Available" ;
VAL_ 2566759703 EnaStsOfDoor1 0 "Door disabled" 1 "Door enabled" 2 "Error" 3 "Not Available" ;
VAL_ 2566759703 OpenStsOfDoor1 0 "Door closed" 1 "Door opened" 2 "Error" 3 "Not Available" ;
VAL_ 2566759703 LckStsOfDoor1 0 "Unlocked" 1 "Locked" 2 "Error" 3 "Not Available" ;
VAL_ 2566849774 CodriverVdoPersDataCons 0 "Refused" 1 "Permitted" ;
VAL_ 2566849774 DrivVdoPersDataCons 0 "Refused" 1 "Permitted" ;
VAL_ 2566849774 CodriverItsPersDataCons 0 "Refused" 1 "Permitted" ;
VAL_ 2566849774 DrivItsPersDataCons 0 "Refused" 1 "Permitted" ;
VAL_ 2566834688 SpnCm20 0 "SPN v.4" 1 "SPN v.1,2,3" ;
VAL_ 2566834691 SpnCm10 0 "SPN v.4" 1 "SPN v.1,2,3" ;
VAL_ 2566834699 SpnCm10_FECA0B 0 "SPN v.4" 1 "SPN v.1,2,3" ;
VAL_ 2566834704 SpnCm10_FECA10 0 "SPN v.4" 1 "SPN v.1,2,3" ;
VAL_ 2566834711 SpnCm20_FECA17 0 "SPN v.4" 1 "SPN v.1,2,3" ;
VAL_ 2566834716 SpnCm10_FECA1C 0 "SPN v.4" 1 "SPN v.1,2,3" ;
VAL_ 2566834717 SpnCm10_FECA1D 0 "SPN v.4" 1 "SPN v.1,2,3" ;
VAL_ 2566834721 SpnCm10_FECA21 0 "SPN v.4" 1 "SPN v.1,2,3" ;
VAL_ 2566834727 SpnCm10_FECA27 0 "SPN v.4" 1 "SPN v.1,2,3" ;
VAL_ 2566834734 SpnCm10_FECA2E 0 "SPN v.4" 1 "SPN v.1,2,3" ;
VAL_ 2566834735 SpnCm10_FECA2F 0 "SPN v.4" 1 "SPN v.1,2,3" ;
VAL_ 2566834739 SpnCm10_FECA33 0 "SPN v.4" 1 "SPN v.1,2,3" ;
VAL_ 2566834744 SpnCm10_FECA38 0 "SPN v.4" 1 "SPN v.1,2,3" ;
VAL_ 2566834752 SpnCm10_FECA40 0 "SPN v.4" 1 "SPN v.1,2,3" ;
VAL_ 2566834761 SpnCm10_FECA49 0 "SPN v.4" 1 "SPN v.1,2,3" ;
VAL_ 2566834762 SpnCm10_FECA4A 0 "SPN v.4" 1 "SPN v.1,2,3" ;
VAL_ 2566834778 SpnCm10_FECA5A 0 "SPN v.4" 1 "SPN v.1,2,3" ;
VAL_ 2566834782 SpnCm10_FECA5E 0 "SPN v.4" 1 "SPN v.1,2,3" ;
VAL_ 2566834814 SpnCm10_FECA7E 0 "SPN v.4" 1 "SPN v.1,2,3" ;
VAL_ 2566834832 SpnCm10_FECA90 0 "SPN v.4" 1 "SPN v.1,2,3" ;
VAL_ 2566834833 SpnCm10_FECA91 0 "SPN v.4" 1 "SPN v.1,2,3" ;
VAL_ 2566834834 SpnCm10_FECA92 0 "SPN v.4" 1 "SPN v.1,2,3" ;
VAL_ 2566834844 SpnCm10_FECA9C 0 "SPN v.4" 1 "SPN v.1,2,3" ;
VAL_ 2566834846 SpnCm10_FECA9E 0 "SPN v.4" 1 "SPN v.1,2,3" ;
VAL_ 2566834848 SpnCm10_FECAA0 0 "SPN v.4" 1 "SPN v.1,2,3" ;
VAL_ 2566834920 SpnCm10_FECAE8 0 "SPN v.4" 1 "SPN v.1,2,3" ;
VAL_ 2566834926 SpnCm10_FECAEE 0 "SPN v.4" 1 "SPN v.1,2,3" ;
VAL_ 2566834928 SpnCm10_FECAF0 0 "SPN v.4" 1 "SPN v.1,2,3" ;
VAL_ 2566834931 SpnCm10_FECAF3 0 "SPN v.4" 1 "SPN v.1,2,3" ;
VAL_ 2566834972 SpnCm10_FECB1C 0 "SPN v.4" 1 "SPN v.1,2,3" ;
VAL_ 2566834973 SpnCm10_FECB1D 0 "SPN v.4" 1 "SPN v.1,2,3" ;
VAL_ 2566835102 SpnCm10_FECB9E 0 "SPN v.4" 1 "SPN v.1,2,3" ;
VAL_ 2633943577 SpnCm10_FECA19 0 "SPN v.4" 1 "SPN v.1,2,3" ;
VAL_ 2633943610 SpnCm10_FECA3A 0 "SPN v.4" 1 "SPN v.1,2,3" ;
VAL_ 2633943680 SpnCm10_FECA80 0 "SPN v.4" 1 "SPN v.1,2,3" ;
VAL_ 2566856773 DoorId 0 "Not used" 1 "Door_1" 2 "Door_2" 3 "Door_3" 4 "Door_4" 5 "Door_5" 6 "Door_6" 7 "Door_7" ;
VAL_ 2566749184 DpfAregenInhSts 0 "Not inhibited" 1 "Inhibited" 2 "Reserved" 3 "Not Available" ;
VAL_ 2566749184 AtDpfSts 0 "Not needed" 1 "Needed, lowest level" 2 "Needed, moderate level" 3 "Needed,highest level" 4 "Reserved" 5 "Reserved" 6 "Reserved" 7 "Not Available" ;
VAL_ 2566749184 AtDpfAregenSts 0 "Not active" 1 "Active" 2 "Needed, automatically imminent" 3 "Not Available" ;
VAL_ 2566749184 AtDpfPregenSts 0 "Not active" 1 "Active" 2 "Reserved" 3 "Not Available" ;
VAL_ 2566749184 DpfLampCmd 0 "Off" 1 "On, solid" 2 "Reserved" 3 "Reserved" 4 "On, fast blink (1 HZ)" 5 "On, very fast blink" 6 "Reserved" 7 "Not Available" ;
VAL_ 2561126730 BenefitAcc 0 "False" 1 "True" 2 "Reserved" 3 "Not available" ;
VAL_ 2561126730 ValidAcc 0 "False" 1 "True" 2 "Reserved" 3 "Not available" ;
VAL_ 2561126986 EventAcc 0 "NoEvent" 1 "AccCEnabled" 2 "AccDisabled" 3 "AccTriggered" ;
VAL_ 2561127242 BenefitAcceleration 0 "False" 1 "True" 2 "Reserved" 3 "Not available" ;
VAL_ 2561127242 ValidAcceleration 0 "False" 1 "True" 2 "Reserved" 3 "Not available" ;
VAL_ 2561127498 EventAccelerator 0 "NoEvent" 1 "GoodAcc" 2 "BadAcc" ;
VAL_ 2561127754 BenefitAebs 0 "False" 1 "True" 2 "Reserved" 3 "Not available" ;
VAL_ 2561127754 ValidAebs 0 "False" 1 "True" 2 "Reserved" 3 "Not available" ;
VAL_ 2561128010 EventAebs 0 "NoEvent" 1 "AebsEnabled" 2 "AebsDisabled" 3 "AebsTriggered" ;
VAL_ 2561128266 BenefitAirC 0 "False" 1 "True" 2 "Reserved" 3 "Not available" ;
VAL_ 2561128266 ValidAirC 0 "False" 1 "True" 2 "Reserved" 3 "Not available" ;
VAL_ 2561144138 BenefitAttention 0 "False" 1 "True" 2 "Reserved" 3 "Not available" ;
VAL_ 2561144138 ValidAttention 0 "False" 1 "True" 2 "Reserved" 3 "Not available" ;
VAL_ 2561128778 BenefitAuxBrake 0 "False" 1 "True" 2 "Reserved" 3 "Not available" ;
VAL_ 2561128778 ValidAuxBrake 0 "False" 1 "True" 2 "Reserved" 3 "Not available" ;
VAL_ 2561129034 EventAuxBrake 0 "NoEvent" 1 "GoodAuxBrake" 2 "BadAuxBrake" ;
VAL_ 2561145930 BenefitBsis 0 "False" 1 "True" 2 "Reserved" 3 "Not available" ;
VAL_ 2561145930 ValidBsis 0 "False" 1 "True" 2 "Reserved" 3 "Not available" ;
VAL_ 2561129290 BenefitCare 0 "False" 1 "True" 2 "Reserved" 3 "Not available" ;
VAL_ 2561129290 ValidCare 0 "False" 1 "True" 2 "Reserved" 3 "Not available" ;
VAL_ 2561129546 ResetEcoB 0 "False" 1 "True" 2 "Reserved" 3 "Not available" ;
VAL_ 2561129546 ResetEcoA 0 "False" 1 "True" 2 "Reserved" 3 "Not available" ;
VAL_ 2561130058 BenefitComfort 0 "False" 1 "True" 2 "Reserved" 3 "Not available" ;
VAL_ 2561130058 ValidComfort 0 "False" 1 "True" 2 "Reserved" 3 "Not available" ;
VAL_ 2561130314 BenefitDas 0 "False" 1 "True" 2 "Reserved" 3 "Not available" ;
VAL_ 2561130314 ValidDas 0 "False" 1 "True" 2 "Reserved" 3 "Not available" ;
VAL_ 2561140554 EventDas 0 "NoEvent" 1 "DasWarning" 2 "DasStop" ;
VAL_ 2561130570 BenefitDeceleration 0 "False" 1 "True" 2 "Reserved" 3 "Not available" ;
VAL_ 2561130570 ValidDeceleration 0 "False" 1 "True" 2 "Reserved" 3 "Not available" ;
VAL_ 2561143882 BenefitDriverAwareness 0 "False" 1 "True" 2 "Reserved" 3 "Not available" ;
VAL_ 2561143882 ValidDriverAwareness 0 "False" 1 "True" 2 "Reserved" 3 "Not available" ;
VAL_ 2561130826 BenefitEcoMode 0 "False" 1 "True" 2 "Reserved" 3 "Not available" ;
VAL_ 2561130826 ValidEcoMode 0 "False" 1 "True" 2 "Reserved" 3 "Not available" ;
VAL_ 2561131338 BenefitEngineUse 0 "False" 1 "True" 2 "Reserved" 3 "Not available" ;
VAL_ 2561131338 ValidEngineUse 0 "False" 1 "True" 2 "Reserved" 3 "Not available" ;
VAL_ 2561131594 BenfFuel 0 "False" 1 "True" 2 "Reserved" 3 "Not available" ;
VAL_ 2561131594 ValFuel 0 "False" 1 "True" 2 "Reserved" 3 "Not available" ;
VAL_ 2561132106 BenefitHandBrake 0 "False" 1 "True" 2 "Reserved" 3 "Not available" ;
VAL_ 2561132106 ValidHandBrake 0 "False" 1 "True" 2 "Reserved" 3 "Not available" ;
VAL_ 2561132362 EventHandBrake 0 "NoEvent" 1 "BadHandBrake" ;
VAL_ 2561132618 BenefitHarshBraking 0 "False" 1 "True" 2 "Reserved" 3 "Not available" ;
VAL_ 2561132618 ValidHarshBraking 0 "False" 1 "True" 2 "Reserved" 3 "Not available" ;
VAL_ 2561132874 EventHarshBraking 0 "NoEvent" 1 "HarshBrakingDetected" ;
VAL_ 2561133130 BenefitHarshSteering 0 "False" 1 "True" 2 "Reserved" 3 "Not available" ;
VAL_ 2561133130 ValidHarshSteering 0 "False" 1 "True" 2 "Reserved" 3 "Not available" ;
VAL_ 2561133386 EventHarshSteering 0 "NoEvent" 1 "HarshSteeringDetected" ;
VAL_ 2561133898 BenefitInertia 0 "False" 1 "True" 2 "Reserved" 3 "Not available" ;
VAL_ 2561133898 ValidInertia 0 "False" 1 "True" 2 "Reserved" 3 "Not available" ;
VAL_ 2561134154 PunishingManeuvInertia 0 "False" 1 "True" 2 "Reserved" 3 "Not available" ;
VAL_ 2561134154 DangerOfCollisInertia 0 "False" 1 "True" 2 "Reserved" 3 "Not available" ;
VAL_ 2561134154 EndReasonInertia 0 "NoReason" 1 "BrakeAction" 2 "GasPedalPressed" 3 "CruiseControlEnabled" 4 "NoEnded" ;
VAL_ 2561134154 StartReasonInertia 0 "NoReason" 1 "GasPedalReleased" 2 "CruiseControlDisabled" ;
VAL_ 2561134154 EventInertia 0 "NoEvent" 1 "GoodInertia" 2 "BadInertia" 3 "GoodGasGas" 4 "DangerOfCollision" 5 "PunishingManeuver" ;
VAL_ 2561134410 BenefitInertiaPecc 0 "False" 1 "True" 2 "Reserved" 3 "Not available" ;
VAL_ 2561134410 ValidInertiaPecc 0 "False" 1 "True" 2 "Reserved" 3 "Not available" ;
